VERSION ""

NS_ :

BS_:

BU_: BMS HVB BMU

BO_ 2147484693 CURRENT: 4 Vector__XXX
 SG_ Current : 7|32@0+ (1000,-2147483648) [-2147483648|4292819811352] "A" Vector__XXX

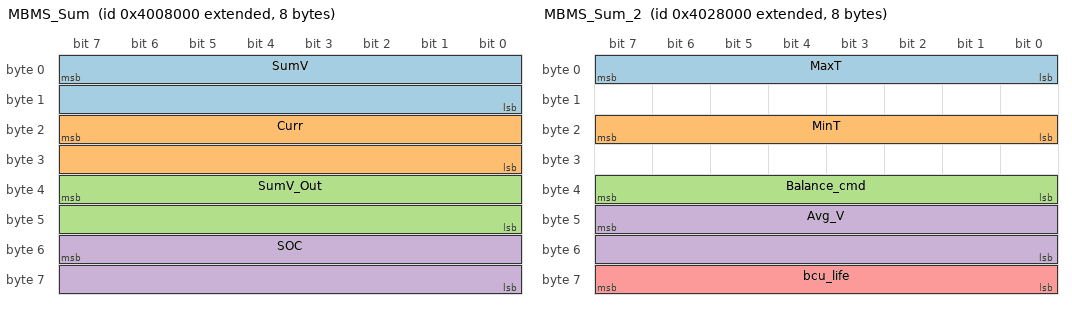
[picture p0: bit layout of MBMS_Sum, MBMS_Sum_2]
BO_ 2214625280 MBMS_Sum: 8 BMS
 SG_ SumV : 7|16@0+ (0.1,0) [1|1] "V" Vector__XXX
 SG_ Curr : 23|16@0+ (0.1,-3000) [1|1] "A" Vector__XXX
 SG_ SumV_Out : 39|16@0+ (0.1,0) [1|1] "V" Vector__XXX
 SG_ SOC : 55|16@0+ (0.1,0) [1|1] "%" Vector__XXX

BO_ 2214690816 MBMS_EVI: 8 BMS
 SG_ MaxV : 7|16@0+ (0.001,0) [1|1] "V" Vector__XXX
 SG_ MinV : 31|16@0+ (0.001,0) [1|1] "V" Vector__XXX
 SG_ SN : 55|8@0+ (1,0) [1|1] "" Vector__XXX

BO_ 2214756352 MBMS_Sum_2: 8 BMS
 SG_ MaxT : 7|8@0+ (1,-40) [1|1] "⊥" Vector__XXX
 SG_ MinT : 23|8@0+ (1,-40) [1|1] "⊥" Vector__XXX
 SG_ Balance_cmd : 39|8@0+ (1,0) [1|1] "" Vector__XXX
 SG_ Avg_V : 47|16@0+ (0.001,0) [1|1] "V" Vector__XXX
 SG_ bcu_life : 63|8@0+ (1,0) [1|1] "" Vector__XXX

BO_ 2214887424 MBMS_Chg_2: 8 BMS
 SG_ NomCap : 39|16@0+ (1,0) [1|1] "AH" Vector__XXX
 SG_ ActCap_ : 55|16@0+ (1,0) [1|1] "AH" Vector__XXX

BO_ 2214952960 MBMS_Data_1: 8 BMS
 SG_ Total_In_Ah : 7|32@0+ (1,0) [1|1] "" Vector__XXX
 SG_ Total_Out_Ah : 39|32@0+ (1,0) [1|1] "" Vector__XXX

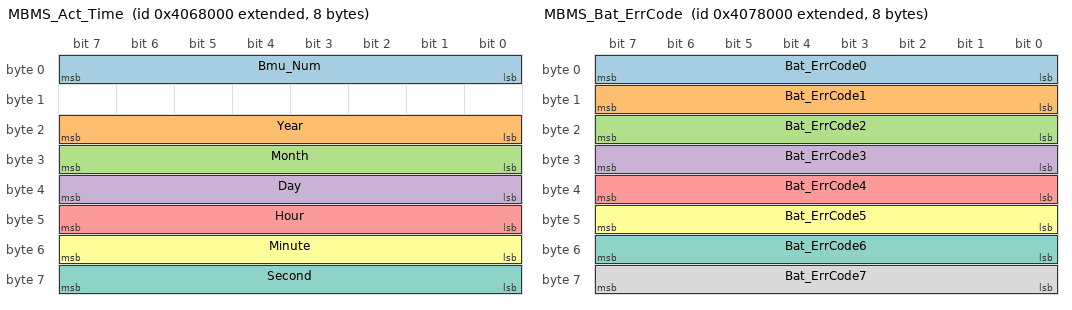
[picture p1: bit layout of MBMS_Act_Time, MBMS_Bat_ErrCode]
BO_ 2215018496 MBMS_Act_Time: 8 BMS
 SG_ Bmu_Num : 7|8@0+ (1,0) [1|1] "" Vector__XXX
 SG_ Year : 23|8@0+ (1,0) [1|1] "" Vector__XXX
 SG_ Month : 31|8@0+ (1,0) [1|1] "" Vector__XXX
 SG_ Day : 39|8@0+ (1,0) [1|1] "" Vector__XXX
 SG_ Hour : 47|8@0+ (1,0) [1|1] "" Vector__XXX
 SG_ Minute : 55|8@0+ (1,0) [1|1] "" Vector__XXX
 SG_ Second : 63|8@0+ (1,0) [1|1] "" Vector__XXX

BO_ 2215084032 MBMS_Bat_ErrCode: 8 BMS
 SG_ Bat_ErrCode0 : 7|8@0+ (1,0) [1|1] "" Vector__XXX
 SG_ Bat_ErrCode1 : 15|8@0+ (1,0) [1|1] "" Vector__XXX
 SG_ Bat_ErrCode2 : 23|8@0+ (1,0) [1|1] "" Vector__XXX
 SG_ Bat_ErrCode3 : 31|8@0+ (1,0) [1|1] "" Vector__XXX
 SG_ Bat_ErrCode4 : 39|8@0+ (1,0) [1|1] "" Vector__XXX
 SG_ Bat_ErrCode5 : 47|8@0+ (1,0) [1|1] "" Vector__XXX
 SG_ Bat_ErrCode6 : 55|8@0+ (1,0) [1|1] "" Vector__XXX
 SG_ Bat_ErrCode7 : 63|8@0+ (1,0) [1|1] "" Vector__XXX

BO_ 2215149568 MBMS_BatSys_ErrCode: 8 BMS
 SG_ BatSys_ErrCode0 : 7|8@0+ (1,0) [1|1] "" Vector__XXX
 SG_ BatSys_ErrCode1 : 15|8@0+ (1,0) [1|1] "" Vector__XXX

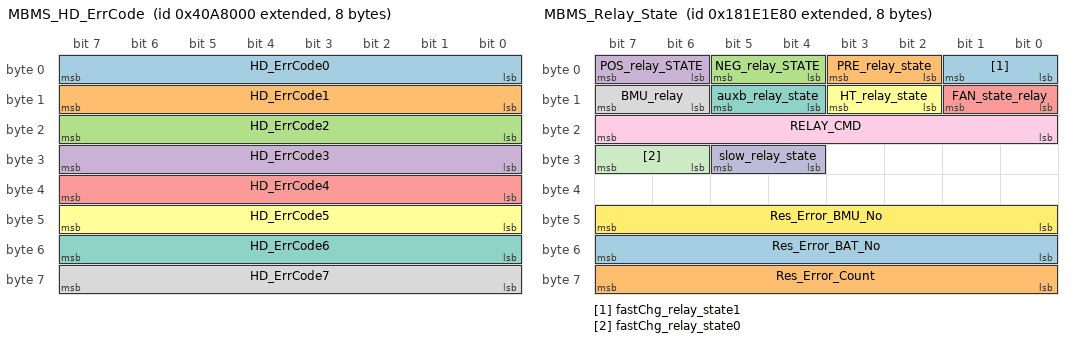
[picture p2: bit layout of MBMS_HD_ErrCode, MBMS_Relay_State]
BO_ 2215280640 MBMS_HD_ErrCode: 8 BMS
 SG_ HD_ErrCode0 : 7|8@0+ (1,0) [1|1] "" Vector__XXX
 SG_ HD_ErrCode1 : 15|8@0+ (1,0) [1|1] "" Vector__XXX
 SG_ HD_ErrCode2 : 23|8@0+ (1,0) [1|1] "" Vector__XXX
 SG_ HD_ErrCode3 : 31|8@0+ (1,0) [1|1] "" Vector__XXX
 SG_ HD_ErrCode4 : 39|8@0+ (1,0) [1|1] "" Vector__XXX
 SG_ HD_ErrCode5 : 47|8@0+ (1,0) [1|1] "" Vector__XXX
 SG_ HD_ErrCode6 : 55|8@0+ (1,0) [1|1] "" Vector__XXX
 SG_ HD_ErrCode7 : 63|8@0+ (1,0) [1|1] "" Vector__XXX

BO_ 2552110720 MBMS_Relay_State: 8 BMS
 SG_ fastChg_relay_state1 : 1|2@0+ (1,0) [1|1] "" Vector__XXX
 SG_ PRE_relay_state : 3|2@0+ (1,0) [1|1] "" Vector__XXX
 SG_ NEG_relay_STATE : 5|2@0+ (1,0) [1|1] "" Vector__XXX
 SG_ POS_relay_STATE : 7|2@0+ (1,0) [1|1] "" Vector__XXX
 SG_ FAN_state_relay : 9|2@0+ (1,0) [1|1] "" Vector__XXX
 SG_ HT_relay_state : 11|2@0+ (1,0) [1|1] "" Vector__XXX
 SG_ auxb_relay_state : 13|2@0+ (1,0) [1|1] "" Vector__XXX
 SG_ BMU_relay : 15|2@0+ (1,0) [1|1] "" Vector__XXX
 SG_ RELAY_CMD : 23|8@0+ (1,0) [1|1] "" Vector__XXX
 SG_ slow_relay_state : 29|2@0+ (1,0) [1|1] "" Vector__XXX
 SG_ fastChg_relay_state0 : 31|2@0+ (1,0) [1|1] "" Vector__XXX
 SG_ Res_Error_BMU_No : 47|8@0+ (1,0) [1|1] "" Vector__XXX
 SG_ Res_Error_BAT_No : 55|8@0+ (1,0) [1|1] "" Vector__XXX
 SG_ Res_Error_Count : 63|8@0+ (1,0) [1|1] "" Vector__XXX

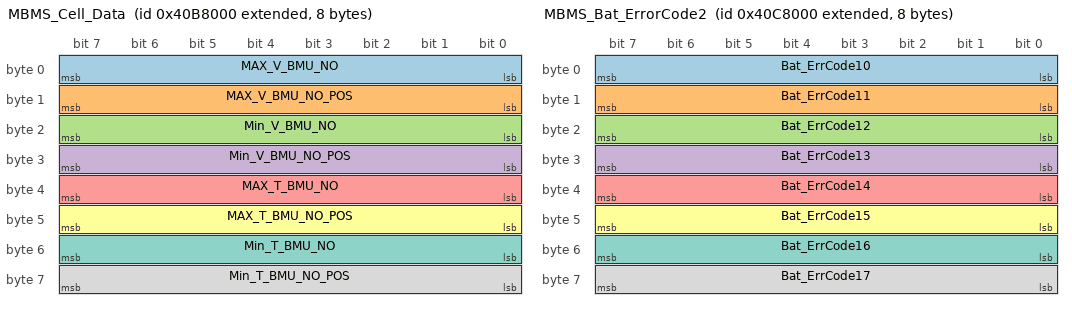
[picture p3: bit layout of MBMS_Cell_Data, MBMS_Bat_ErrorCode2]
BO_ 2215346176 MBMS_Cell_Data: 8 BMS
 SG_ MAX_V_BMU_NO : 7|8@0+ (1,0) [1|1] "" Vector__XXX
 SG_ MAX_V_BMU_NO_POS : 15|8@0+ (1,0) [1|1] "" Vector__XXX
 SG_ Min_V_BMU_NO : 23|8@0+ (1,0) [1|1] "" Vector__XXX
 SG_ Min_V_BMU_NO_POS : 31|8@0+ (1,0) [1|1] "" Vector__XXX
 SG_ MAX_T_BMU_NO : 39|8@0+ (1,0) [1|1] "" Vector__XXX
 SG_ MAX_T_BMU_NO_POS : 47|8@0+ (1,0) [1|1] "" Vector__XXX
 SG_ Min_T_BMU_NO : 55|8@0+ (1,0) [1|1] "" Vector__XXX
 SG_ Min_T_BMU_NO_POS : 63|8@0+ (1,0) [1|1] "" Vector__XXX

BO_ 2215411712 MBMS_Bat_ErrorCode2: 8 BMS
 SG_ Bat_ErrCode10 : 7|8@0+ (1,0) [1|1] "" Vector__XXX
 SG_ Bat_ErrCode11 : 15|8@0+ (1,0) [1|1] "" Vector__XXX
 SG_ Bat_ErrCode12 : 23|8@0+ (1,0) [1|1] "" Vector__XXX
 SG_ Bat_ErrCode13 : 31|8@0+ (1,0) [1|1] "" Vector__XXX
 SG_ Bat_ErrCode14 : 39|8@0+ (1,0) [1|1] "" Vector__XXX
 SG_ Bat_ErrCode15 : 47|8@0+ (1,0) [1|1] "" Vector__XXX
 SG_ Bat_ErrCode16 : 55|8@0+ (1,0) [1|1] "" Vector__XXX
 SG_ Bat_ErrCode17 : 63|8@0+ (1,0) [1|1] "" Vector__XXX

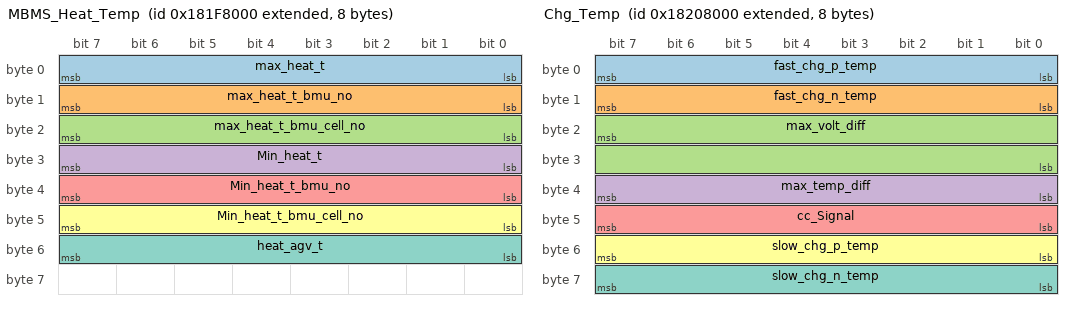
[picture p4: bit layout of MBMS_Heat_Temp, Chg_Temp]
BO_ 2552201216 MBMS_Heat_Temp: 8 BMS
 SG_ max_heat_t : 7|8@0+ (1,-40) [1|1] "⊥" Vector__XXX
 SG_ max_heat_t_bmu_no : 15|8@0+ (1,0) [1|1] "" Vector__XXX
 SG_ max_heat_t_bmu_cell_no : 23|8@0+ (1,0) [1|1] "" Vector__XXX
 SG_ Min_heat_t : 31|8@0+ (1,-40) [1|1] "⊥" Vector__XXX
 SG_ Min_heat_t_bmu_no : 39|8@0+ (1,0) [1|1] "" Vector__XXX
 SG_ Min_heat_t_bmu_cell_no : 47|8@0+ (1,0) [1|1] "" Vector__XXX
 SG_ heat_agv_t : 55|8@0+ (1,-40) [1|1] "⊥" Vector__XXX

BO_ 2552266752 Chg_Temp: 8 BMS
 SG_ fast_chg_p_temp : 7|8@0+ (1,-40) [1|1] "⊥" Vector__XXX
 SG_ fast_chg_n_temp : 15|8@0+ (1,-40) [1|1] "⊥" Vector__XXX
 SG_ max_volt_diff : 23|16@0+ (1,0) [1|1] "mV" Vector__XXX
 SG_ max_temp_diff : 39|8@0+ (1,-40) [1|1] "⊥" Vector__XXX
 SG_ cc_Signal : 47|8@0+ (1,0) [1|1] "" Vector__XXX
 SG_ slow_chg_p_temp : 55|8@0+ (1,-40) [1|1] "⊥" Vector__XXX
 SG_ slow_chg_n_temp : 63|8@0+ (1,-40) [1|1] "⊥" Vector__XXX

BO_ 2215542784 MBMS_HV: 8 BMS
 SG_ BAT_TV : 7|16@0+ (0.1,0) [1|1] "" Vector__XXX
 SG_ CHG_TV : 23|16@0+ (0.1,0) [1|1] "" Vector__XXX

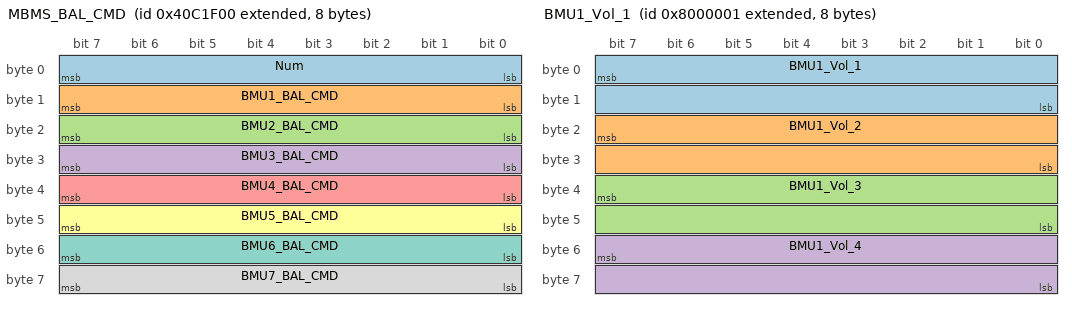
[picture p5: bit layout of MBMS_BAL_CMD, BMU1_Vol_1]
BO_ 2215386880 MBMS_BAL_CMD: 8 BMS
 SG_ Num : 7|8@0+ (1,0) [1|1] "" Vector__XXX
 SG_ BMU1_BAL_CMD : 15|8@0+ (1,0) [1|1] "" Vector__XXX
 SG_ BMU2_BAL_CMD : 23|8@0+ (1,0) [1|1] "" Vector__XXX
 SG_ BMU3_BAL_CMD : 31|8@0+ (1,0) [1|1] "" Vector__XXX
 SG_ BMU4_BAL_CMD : 39|8@0+ (1,0) [1|1] "" Vector__XXX
 SG_ BMU5_BAL_CMD : 47|8@0+ (1,0) [1|1] "" Vector__XXX
 SG_ BMU6_BAL_CMD : 55|8@0+ (1,0) [1|1] "" Vector__XXX
 SG_ BMU7_BAL_CMD : 63|8@0+ (1,0) [1|1] "" Vector__XXX

BO_ 2214920222 HVC_ISO_Res: 8 HVB
 SG_ ISO_RES_VAL : 7|16@0+ (1,0) [1|1] "K次"  BMS

BO_ 2281701377 BMU1_Vol_1: 8 BMU
 SG_ BMU1_Vol_1 : 7|16@0+ (0.001,0) [1|1] "V"  BMS
 SG_ BMU1_Vol_2 : 23|16@0+ (0.001,0) [1|1] "V"  BMS
 SG_ BMU1_Vol_3 : 39|16@0+ (0.001,0) [1|1] "V"  BMS
 SG_ BMU1_Vol_4 : 55|16@0+ (0.001,0) [1|1] "V"  BMS

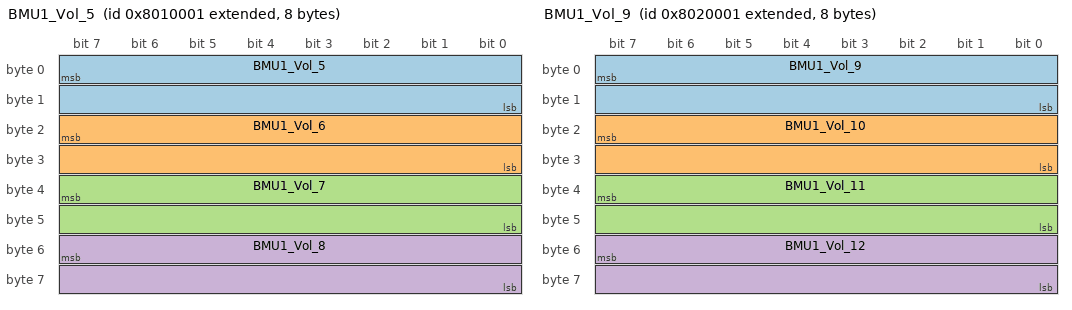
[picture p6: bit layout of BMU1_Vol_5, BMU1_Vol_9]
BO_ 2281766913 BMU1_Vol_5: 8 BMU
 SG_ BMU1_Vol_5 : 7|16@0+ (0.001,0) [1|1] "V"  BMS
 SG_ BMU1_Vol_6 : 23|16@0+ (0.001,0) [1|1] "V"  BMS
 SG_ BMU1_Vol_7 : 39|16@0+ (0.001,0) [1|1] "V"  BMS
 SG_ BMU1_Vol_8 : 55|16@0+ (0.001,0) [1|1] "V"  BMS

BO_ 2281832449 BMU1_Vol_9: 8 BMU
 SG_ BMU1_Vol_9 : 7|16@0+ (0.001,0) [1|1] "V"  BMS
 SG_ BMU1_Vol_10 : 23|16@0+ (0.001,0) [1|1] "V"  BMS
 SG_ BMU1_Vol_11 : 39|16@0+ (0.001,0) [1|1] "V"  BMS
 SG_ BMU1_Vol_12 : 55|16@0+ (0.001,0) [1|1] "V"  BMS

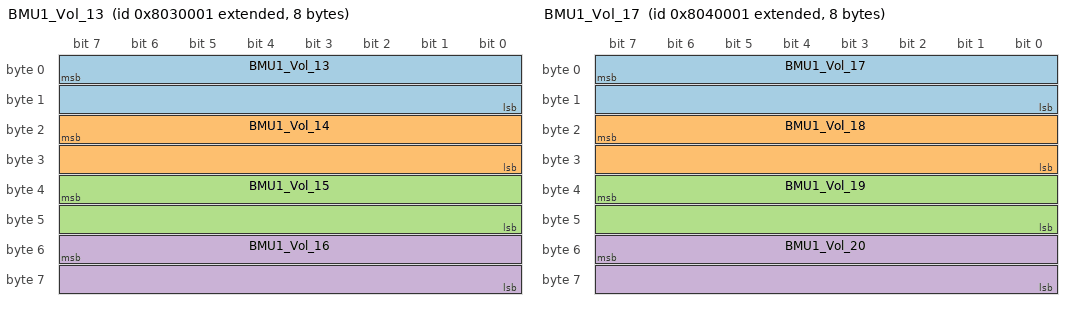
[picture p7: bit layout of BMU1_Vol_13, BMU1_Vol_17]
BO_ 2281897985 BMU1_Vol_13: 8 BMU
 SG_ BMU1_Vol_13 : 7|16@0+ (0.001,0) [1|1] "V"  BMS
 SG_ BMU1_Vol_14 : 23|16@0+ (0.001,0) [1|1] "V"  BMS
 SG_ BMU1_Vol_15 : 39|16@0+ (0.001,0) [1|1] "V"  BMS
 SG_ BMU1_Vol_16 : 55|16@0+ (0.001,0) [1|1] "V"  BMS

BO_ 2281963521 BMU1_Vol_17: 8 BMU
 SG_ BMU1_Vol_17 : 7|16@0+ (0.001,0) [1|1] "V"  BMS
 SG_ BMU1_Vol_18 : 23|16@0+ (0.001,0) [1|1] "V"  BMS
 SG_ BMU1_Vol_19 : 39|16@0+ (0.001,0) [1|1] "V"  BMS
 SG_ BMU1_Vol_20 : 55|16@0+ (0.001,0) [1|1] "V"  BMS

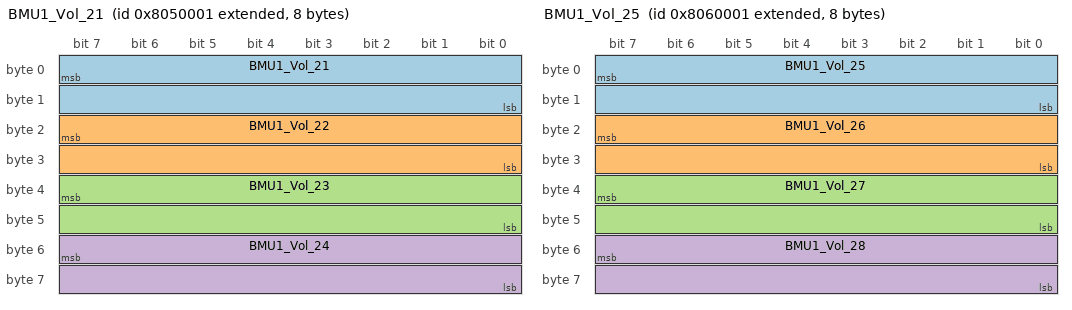
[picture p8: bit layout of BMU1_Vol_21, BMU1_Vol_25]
BO_ 2282029057 BMU1_Vol_21: 8 BMU
 SG_ BMU1_Vol_21 : 7|16@0+ (0.001,0) [1|1] "V"  BMS
 SG_ BMU1_Vol_22 : 23|16@0+ (0.001,0) [1|1] "V"  BMS
 SG_ BMU1_Vol_23 : 39|16@0+ (0.001,0) [1|1] "V"  BMS
 SG_ BMU1_Vol_24 : 55|16@0+ (0.001,0) [1|1] "V"  BMS

BO_ 2282094593 BMU1_Vol_25: 8 BMU
 SG_ BMU1_Vol_25 : 7|16@0+ (0.001,0) [1|1] "V"  BMS
 SG_ BMU1_Vol_26 : 23|16@0+ (0.001,0) [1|1] "V"  BMS
 SG_ BMU1_Vol_27 : 39|16@0+ (0.001,0) [1|1] "V"  BMS
 SG_ BMU1_Vol_28 : 55|16@0+ (0.001,0) [1|1] "V"  BMS

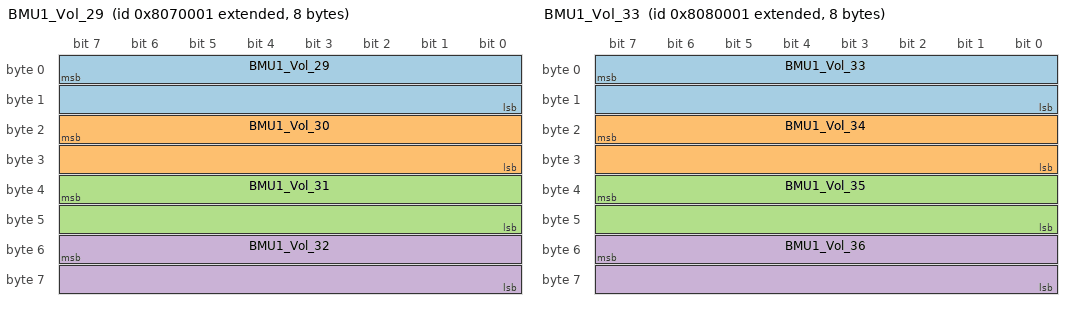
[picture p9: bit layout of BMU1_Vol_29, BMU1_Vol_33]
BO_ 2282160129 BMU1_Vol_29: 8 BMU
 SG_ BMU1_Vol_29 : 7|16@0+ (0.001,0) [1|1] "V"  BMS
 SG_ BMU1_Vol_30 : 23|16@0+ (0.001,0) [1|1] "V"  BMS
 SG_ BMU1_Vol_31 : 39|16@0+ (0.001,0) [1|1] "V"  BMS
 SG_ BMU1_Vol_32 : 55|16@0+ (0.001,0) [1|1] "V"  BMS

BO_ 2282225665 BMU1_Vol_33: 8 BMU
 SG_ BMU1_Vol_33 : 7|16@0+ (0.001,0) [1|1] "V"  BMS
 SG_ BMU1_Vol_34 : 23|16@0+ (0.001,0) [1|1] "V"  BMS
 SG_ BMU1_Vol_35 : 39|16@0+ (0.001,0) [1|1] "V"  BMS
 SG_ BMU1_Vol_36 : 55|16@0+ (0.001,0) [1|1] "V"  BMS

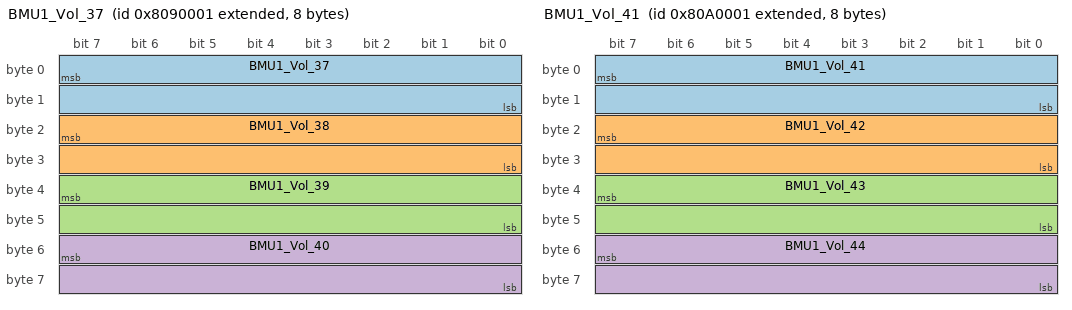
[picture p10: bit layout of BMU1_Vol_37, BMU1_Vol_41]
BO_ 2282291201 BMU1_Vol_37: 8 BMU
 SG_ BMU1_Vol_37 : 7|16@0+ (0.001,0) [1|1] "V"  BMS
 SG_ BMU1_Vol_38 : 23|16@0+ (0.001,0) [1|1] "V"  BMS
 SG_ BMU1_Vol_39 : 39|16@0+ (0.001,0) [1|1] "V"  BMS
 SG_ BMU1_Vol_40 : 55|16@0+ (0.001,0) [1|1] "V"  BMS

BO_ 2282356737 BMU1_Vol_41: 8 BMU
 SG_ BMU1_Vol_41 : 7|16@0+ (0.001,0) [1|1] "V"  BMS
 SG_ BMU1_Vol_42 : 23|16@0+ (0.001,0) [1|1] "V"  BMS
 SG_ BMU1_Vol_43 : 39|16@0+ (0.001,0) [1|1] "V"  BMS
 SG_ BMU1_Vol_44 : 55|16@0+ (0.001,0) [1|1] "V"  BMS

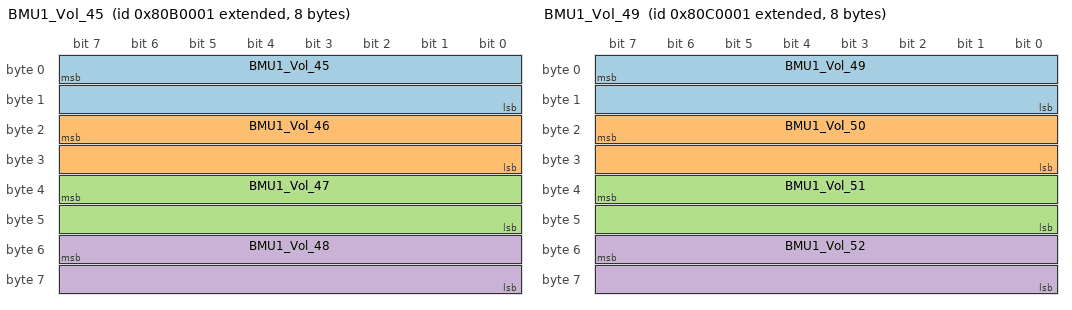
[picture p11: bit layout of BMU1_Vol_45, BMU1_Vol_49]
BO_ 2282422273 BMU1_Vol_45: 8 BMU
 SG_ BMU1_Vol_45 : 7|16@0+ (0.001,0) [1|1] "V"  BMS
 SG_ BMU1_Vol_46 : 23|16@0+ (0.001,0) [1|1] "V"  BMS
 SG_ BMU1_Vol_47 : 39|16@0+ (0.001,0) [1|1] "V"  BMS
 SG_ BMU1_Vol_48 : 55|16@0+ (0.001,0) [1|1] "V"  BMS

BO_ 2282487809 BMU1_Vol_49: 8 BMU
 SG_ BMU1_Vol_49 : 7|16@0+ (0.001,0) [1|1] "V"  BMS
 SG_ BMU1_Vol_50 : 23|16@0+ (0.001,0) [1|1] "V"  BMS
 SG_ BMU1_Vol_51 : 39|16@0+ (0.001,0) [1|1] "V"  BMS
 SG_ BMU1_Vol_52 : 55|16@0+ (0.001,0) [1|1] "V"  BMS

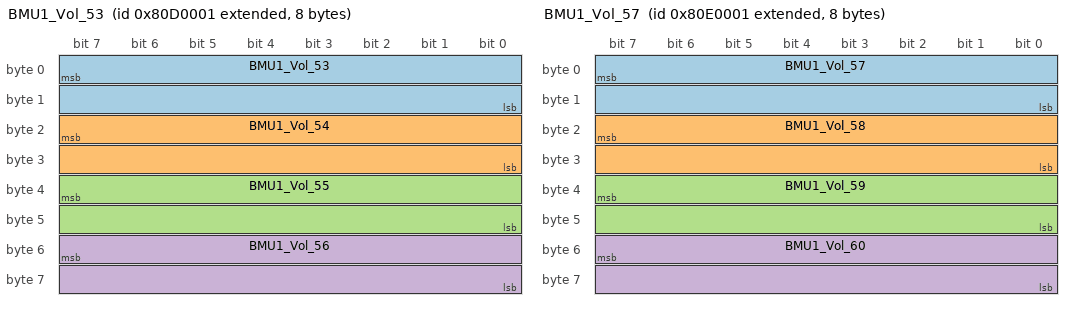
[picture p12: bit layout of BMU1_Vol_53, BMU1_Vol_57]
BO_ 2282553345 BMU1_Vol_53: 8 BMU
 SG_ BMU1_Vol_53 : 7|16@0+ (0.001,0) [1|1] "V"  BMS
 SG_ BMU1_Vol_54 : 23|16@0+ (0.001,0) [1|1] "V"  BMS
 SG_ BMU1_Vol_55 : 39|16@0+ (0.001,0) [1|1] "V"  BMS
 SG_ BMU1_Vol_56 : 55|16@0+ (0.001,0) [1|1] "V"  BMS

BO_ 2282618881 BMU1_Vol_57: 8 BMU
 SG_ BMU1_Vol_57 : 7|16@0+ (0.001,0) [1|1] "V"  BMS
 SG_ BMU1_Vol_58 : 23|16@0+ (0.001,0) [1|1] "V"  BMS
 SG_ BMU1_Vol_59 : 39|16@0+ (0.001,0) [1|1] "V"  BMS
 SG_ BMU1_Vol_60 : 55|16@0+ (0.001,0) [1|1] "V"  BMS

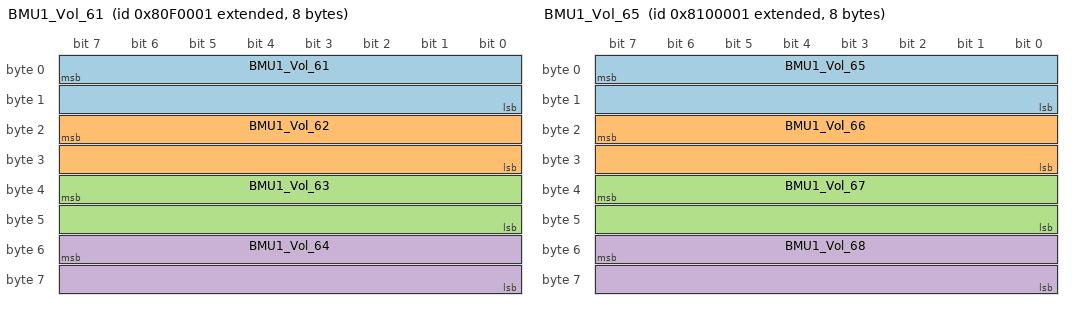
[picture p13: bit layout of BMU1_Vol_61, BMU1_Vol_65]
BO_ 2282684417 BMU1_Vol_61: 8 BMU
 SG_ BMU1_Vol_61 : 7|16@0+ (0.001,0) [1|1] "V"  BMS
 SG_ BMU1_Vol_62 : 23|16@0+ (0.001,0) [1|1] "V"  BMS
 SG_ BMU1_Vol_63 : 39|16@0+ (0.001,0) [1|1] "V"  BMS
 SG_ BMU1_Vol_64 : 55|16@0+ (0.001,0) [1|1] "V"  BMS

BO_ 2282749953 BMU1_Vol_65: 8 BMU
 SG_ BMU1_Vol_65 : 7|16@0+ (0.001,0) [1|1] "V"  BMS
 SG_ BMU1_Vol_66 : 23|16@0+ (0.001,0) [1|1] "V"  BMS
 SG_ BMU1_Vol_67 : 39|16@0+ (0.001,0) [1|1] "V"  BMS
 SG_ BMU1_Vol_68 : 55|16@0+ (0.001,0) [1|1] "V"  BMS

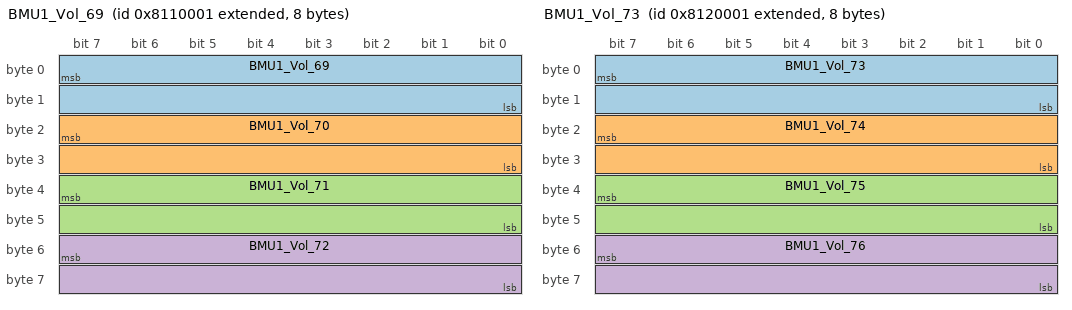
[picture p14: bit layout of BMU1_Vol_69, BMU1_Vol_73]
BO_ 2282815489 BMU1_Vol_69: 8 BMU
 SG_ BMU1_Vol_69 : 7|16@0+ (0.001,0) [1|1] "V"  BMS
 SG_ BMU1_Vol_70 : 23|16@0+ (0.001,0) [1|1] "V"  BMS
 SG_ BMU1_Vol_71 : 39|16@0+ (0.001,0) [1|1] "V"  BMS
 SG_ BMU1_Vol_72 : 55|16@0+ (0.001,0) [1|1] "V"  BMS

BO_ 2282881025 BMU1_Vol_73: 8 BMU
 SG_ BMU1_Vol_73 : 7|16@0+ (0.001,0) [1|1] "V"  BMS
 SG_ BMU1_Vol_74 : 23|16@0+ (0.001,0) [1|1] "V"  BMS
 SG_ BMU1_Vol_75 : 39|16@0+ (0.001,0) [1|1] "V"  BMS
 SG_ BMU1_Vol_76 : 55|16@0+ (0.001,0) [1|1] "V"  BMS

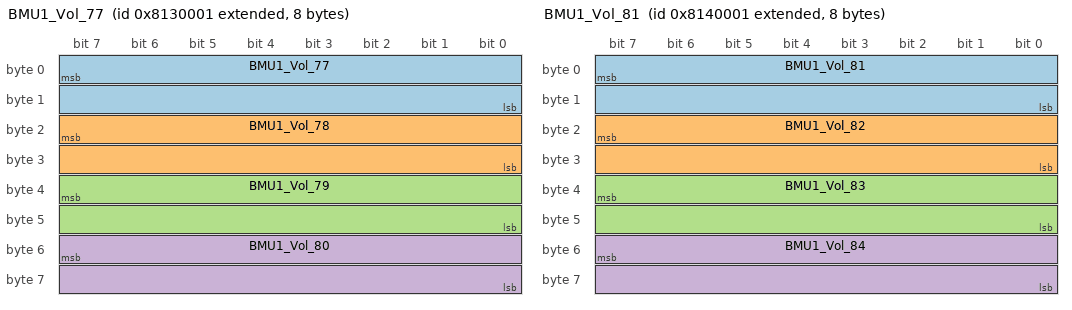
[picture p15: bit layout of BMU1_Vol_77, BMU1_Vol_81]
BO_ 2282946561 BMU1_Vol_77: 8 BMU
 SG_ BMU1_Vol_77 : 7|16@0+ (0.001,0) [1|1] "V"  BMS
 SG_ BMU1_Vol_78 : 23|16@0+ (0.001,0) [1|1] "V"  BMS
 SG_ BMU1_Vol_79 : 39|16@0+ (0.001,0) [1|1] "V"  BMS
 SG_ BMU1_Vol_80 : 55|16@0+ (0.001,0) [1|1] "V"  BMS

BO_ 2283012097 BMU1_Vol_81: 8 BMU
 SG_ BMU1_Vol_81 : 7|16@0+ (0.001,0) [1|1] "V"  BMS
 SG_ BMU1_Vol_82 : 23|16@0+ (0.001,0) [1|1] "V"  BMS
 SG_ BMU1_Vol_83 : 39|16@0+ (0.001,0) [1|1] "V"  BMS
 SG_ BMU1_Vol_84 : 55|16@0+ (0.001,0) [1|1] "V"  BMS

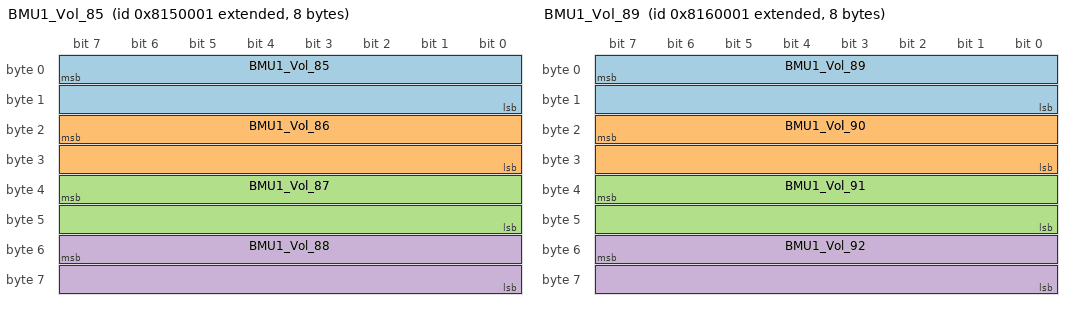
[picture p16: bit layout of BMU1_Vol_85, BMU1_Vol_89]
BO_ 2283077633 BMU1_Vol_85: 8 BMU
 SG_ BMU1_Vol_85 : 7|16@0+ (0.001,0) [1|1] "V"  BMS
 SG_ BMU1_Vol_86 : 23|16@0+ (0.001,0) [1|1] "V"  BMS
 SG_ BMU1_Vol_87 : 39|16@0+ (0.001,0) [1|1] "V"  BMS
 SG_ BMU1_Vol_88 : 55|16@0+ (0.001,0) [1|1] "V"  BMS

BO_ 2283143169 BMU1_Vol_89: 8 BMU
 SG_ BMU1_Vol_89 : 7|16@0+ (0.001,0) [1|1] "V"  BMS
 SG_ BMU1_Vol_90 : 23|16@0+ (0.001,0) [1|1] "V"  BMS
 SG_ BMU1_Vol_91 : 39|16@0+ (0.001,0) [1|1] "V"  BMS
 SG_ BMU1_Vol_92 : 55|16@0+ (0.001,0) [1|1] "V"  BMS

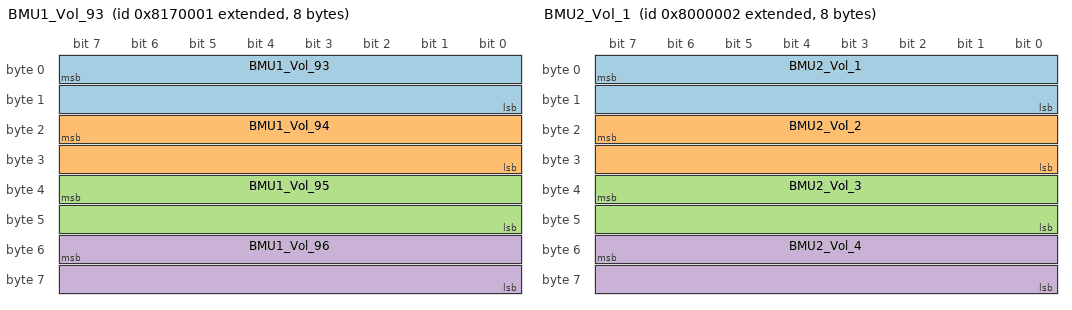
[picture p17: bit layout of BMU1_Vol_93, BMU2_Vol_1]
BO_ 2283208705 BMU1_Vol_93: 8 BMU
 SG_ BMU1_Vol_93 : 7|16@0+ (0.001,0) [1|1] "V"  BMS
 SG_ BMU1_Vol_94 : 23|16@0+ (0.001,0) [1|1] "V"  BMS
 SG_ BMU1_Vol_95 : 39|16@0+ (0.001,0) [1|1] "V"  BMS
 SG_ BMU1_Vol_96 : 55|16@0+ (0.001,0) [1|1] "V"  BMS

BO_ 2281701378 BMU2_Vol_1: 8 BMU
 SG_ BMU2_Vol_1 : 7|16@0+ (0.001,0) [1|1] "V"  BMS
 SG_ BMU2_Vol_2 : 23|16@0+ (0.001,0) [1|1] "V"  BMS
 SG_ BMU2_Vol_3 : 39|16@0+ (0.001,0) [1|1] "V"  BMS
 SG_ BMU2_Vol_4 : 55|16@0+ (0.001,0) [1|1] "V"  BMS

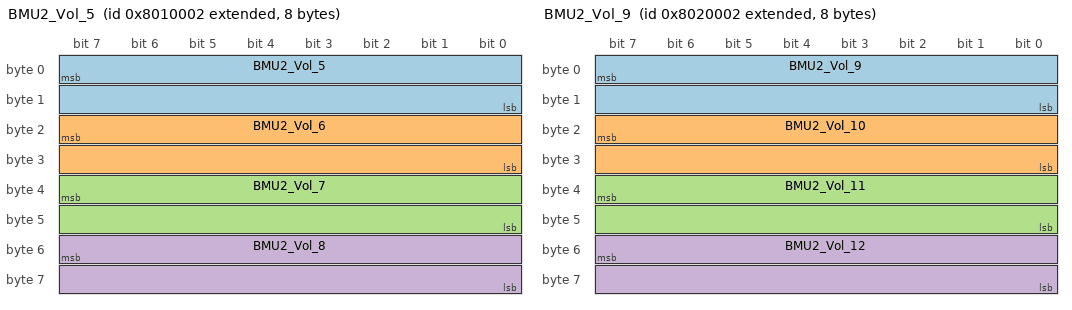
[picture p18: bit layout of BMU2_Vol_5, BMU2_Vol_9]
BO_ 2281766914 BMU2_Vol_5: 8 BMU
 SG_ BMU2_Vol_5 : 7|16@0+ (0.001,0) [1|1] "V"  BMS
 SG_ BMU2_Vol_6 : 23|16@0+ (0.001,0) [1|1] "V"  BMS
 SG_ BMU2_Vol_7 : 39|16@0+ (0.001,0) [1|1] "V"  BMS
 SG_ BMU2_Vol_8 : 55|16@0+ (0.001,0) [1|1] "V"  BMS

BO_ 2281832450 BMU2_Vol_9: 8 BMU
 SG_ BMU2_Vol_9 : 7|16@0+ (0.001,0) [1|1] "V"  BMS
 SG_ BMU2_Vol_10 : 23|16@0+ (0.001,0) [1|1] "V"  BMS
 SG_ BMU2_Vol_11 : 39|16@0+ (0.001,0) [1|1] "V"  BMS
 SG_ BMU2_Vol_12 : 55|16@0+ (0.001,0) [1|1] "V"  BMS

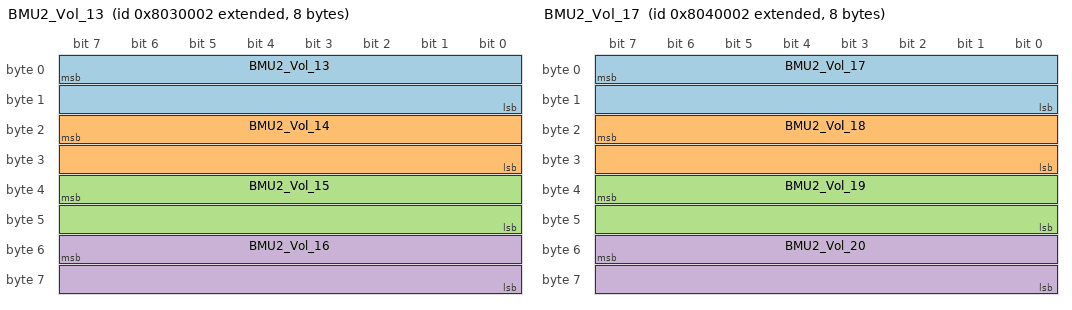
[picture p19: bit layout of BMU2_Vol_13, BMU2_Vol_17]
BO_ 2281897986 BMU2_Vol_13: 8 BMU
 SG_ BMU2_Vol_13 : 7|16@0+ (0.001,0) [1|1] "V"  BMS
 SG_ BMU2_Vol_14 : 23|16@0+ (0.001,0) [1|1] "V"  BMS
 SG_ BMU2_Vol_15 : 39|16@0+ (0.001,0) [1|1] "V"  BMS
 SG_ BMU2_Vol_16 : 55|16@0+ (0.001,0) [1|1] "V"  BMS

BO_ 2281963522 BMU2_Vol_17: 8 BMU
 SG_ BMU2_Vol_17 : 7|16@0+ (0.001,0) [1|1] "V"  BMS
 SG_ BMU2_Vol_18 : 23|16@0+ (0.001,0) [1|1] "V"  BMS
 SG_ BMU2_Vol_19 : 39|16@0+ (0.001,0) [1|1] "V"  BMS
 SG_ BMU2_Vol_20 : 55|16@0+ (0.001,0) [1|1] "V"  BMS

BO_ 2282029058 BMU2_Vol_21: 8 BMU
 SG_ BMU2_Vol_21 : 7|16@0+ (0.001,0) [1|1] "V"  BMS
 SG_ BMU2_Vol_22 : 23|16@0+ (0.001,0) [1|1] "V"  BMS
 SG_ BMU2_Vol_23 : 39|16@0+ (0.001,0) [1|1] "V"  BMS
 SG_ BMU2_Vol_24 : 55|16@0+ (0.001,0) [1|1] "V"  BMS

BO_ 2282094594 BMU2_Vol_25: 8 BMU
 SG_ BMU2_Vol_25 : 7|16@0+ (0.001,0) [1|1] "V"  BMS
 SG_ BMU2_Vol_26 : 23|16@0+ (0.001,0) [1|1] "V"  BMS
 SG_ BMU2_Vol_27 : 39|16@0+ (0.001,0) [1|1] "V"  BMS
 SG_ BMU2_Vol_28 : 55|16@0+ (0.001,0) [1|1] "V"  BMS

BO_ 2282160130 BMU2_Vol_29: 8 BMU
 SG_ BMU2_Vol_29 : 7|16@0+ (0.001,0) [1|1] "V"  BMS
 SG_ BMU2_Vol_30 : 23|16@0+ (0.001,0) [1|1] "V"  BMS
 SG_ BMU2_Vol_31 : 39|16@0+ (0.001,0) [1|1] "V"  BMS
 SG_ BMU2_Vol_32 : 55|16@0+ (0.001,0) [1|1] "V"  BMS

BO_ 2282225666 BMU2_Vol_33: 8 BMU
 SG_ BMU2_Vol_33 : 7|16@0+ (0.001,0) [1|1] "V"  BMS
 SG_ BMU2_Vol_34 : 23|16@0+ (0.001,0) [1|1] "V"  BMS
 SG_ BMU2_Vol_35 : 39|16@0+ (0.001,0) [1|1] "V"  BMS
 SG_ BMU2_Vol_36 : 55|16@0+ (0.001,0) [1|1] "V"  BMS

BO_ 2282291202 BMU2_Vol_37: 8 BMU
 SG_ BMU2_Vol_37 : 7|16@0+ (0.001,0) [1|1] "V"  BMS
 SG_ BMU2_Vol_38 : 23|16@0+ (0.001,0) [1|1] "V"  BMS
 SG_ BMU2_Vol_39 : 39|16@0+ (0.001,0) [1|1] "V"  BMS
 SG_ BMU2_Vol_40 : 55|16@0+ (0.001,0) [1|1] "V"  BMS

BO_ 2282356738 BMU2_Vol_41: 8 BMU
 SG_ BMU2_Vol_41 : 7|16@0+ (0.001,0) [1|1] "V"  BMS
 SG_ BMU2_Vol_42 : 23|16@0+ (0.001,0) [1|1] "V"  BMS
 SG_ BMU2_Vol_43 : 39|16@0+ (0.001,0) [1|1] "V"  BMS
 SG_ BMU2_Vol_44 : 55|16@0+ (0.001,0) [1|1] "V"  BMS

BO_ 2282422274 BMU2_Vol_45: 8 BMU
 SG_ BMU2_Vol_45 : 7|16@0+ (0.001,0) [1|1] "V"  BMS
 SG_ BMU2_Vol_46 : 23|16@0+ (0.001,0) [1|1] "V"  BMS
 SG_ BMU2_Vol_47 : 39|16@0+ (0.001,0) [1|1] "V"  BMS
 SG_ BMU2_Vol_48 : 55|16@0+ (0.001,0) [1|1] "V"  BMS

BO_ 2282487810 BMU2_Vol_49: 8 BMU
 SG_ BMU2_Vol_49 : 7|16@0+ (0.001,0) [1|1] "V"  BMS
 SG_ BMU2_Vol_50 : 23|16@0+ (0.001,0) [1|1] "V"  BMS
 SG_ BMU2_Vol_51 : 39|16@0+ (0.001,0) [1|1] "V"  BMS
 SG_ BMU2_Vol_52 : 55|16@0+ (0.001,0) [1|1] "V"  BMS

BO_ 2282553346 BMU2_Vol_53: 8 BMU
 SG_ BMU2_Vol_53 : 7|16@0+ (0.001,0) [1|1] "V"  BMS
 SG_ BMU2_Vol_54 : 23|16@0+ (0.001,0) [1|1] "V"  BMS
 SG_ BMU2_Vol_55 : 39|16@0+ (0.001,0) [1|1] "V"  BMS
 SG_ BMU2_Vol_56 : 55|16@0+ (0.001,0) [1|1] "V"  BMS

BO_ 2282618882 BMU2_Vol_57: 8 BMU
 SG_ BMU2_Vol_57 : 7|16@0+ (0.001,0) [1|1] "V"  BMS
 SG_ BMU2_Vol_58 : 23|16@0+ (0.001,0) [1|1] "V"  BMS
 SG_ BMU2_Vol_59 : 39|16@0+ (0.001,0) [1|1] "V"  BMS
 SG_ BMU2_Vol_60 : 55|16@0+ (0.001,0) [1|1] "V"  BMS

BO_ 2282684418 BMU2_Vol_61: 8 BMU
 SG_ BMU2_Vol_61 : 7|16@0+ (0.001,0) [1|1] "V"  BMS
 SG_ BMU2_Vol_62 : 23|16@0+ (0.001,0) [1|1] "V"  BMS
 SG_ BMU2_Vol_63 : 39|16@0+ (0.001,0) [1|1] "V"  BMS
 SG_ BMU2_Vol_64 : 55|16@0+ (0.001,0) [1|1] "V"  BMS

BO_ 2282749954 BMU2_Vol_65: 8 BMU
 SG_ BMU2_Vol_65 : 7|16@0+ (0.001,0) [1|1] "V"  BMS
 SG_ BMU2_Vol_66 : 23|16@0+ (0.001,0) [1|1] "V"  BMS
 SG_ BMU2_Vol_67 : 39|16@0+ (0.001,0) [1|1] "V"  BMS
 SG_ BMU2_Vol_68 : 55|16@0+ (0.001,0) [1|1] "V"  BMS

BO_ 2282815490 BMU2_Vol_69: 8 BMU
 SG_ BMU2_Vol_69 : 7|16@0+ (0.001,0) [1|1] "V"  BMS
 SG_ BMU2_Vol_70 : 23|16@0+ (0.001,0) [1|1] "V"  BMS
 SG_ BMU2_Vol_71 : 39|16@0+ (0.001,0) [1|1] "V"  BMS
 SG_ BMU2_Vol_72 : 55|16@0+ (0.001,0) [1|1] "V"  BMS

BO_ 2282881026 BMU2_Vol_73: 8 BMU
 SG_ BMU2_Vol_73 : 7|16@0+ (0.001,0) [1|1] "V"  BMS
 SG_ BMU2_Vol_74 : 23|16@0+ (0.001,0) [1|1] "V"  BMS
 SG_ BMU2_Vol_75 : 39|16@0+ (0.001,0) [1|1] "V"  BMS
 SG_ BMU2_Vol_76 : 55|16@0+ (0.001,0) [1|1] "V"  BMS

BO_ 2282946562 BMU2_Vol_77: 8 BMU
 SG_ BMU2_Vol_77 : 7|16@0+ (0.001,0) [1|1] "V"  BMS
 SG_ BMU2_Vol_78 : 23|16@0+ (0.001,0) [1|1] "V"  BMS
 SG_ BMU2_Vol_79 : 39|16@0+ (0.001,0) [1|1] "V"  BMS
 SG_ BMU2_Vol_80 : 55|16@0+ (0.001,0) [1|1] "V"  BMS

BO_ 2283012098 BMU2_Vol_81: 8 BMU
 SG_ BMU2_Vol_81 : 7|16@0+ (0.001,0) [1|1] "V"  BMS
 SG_ BMU2_Vol_82 : 23|16@0+ (0.001,0) [1|1] "V"  BMS
 SG_ BMU2_Vol_83 : 39|16@0+ (0.001,0) [1|1] "V"  BMS
 SG_ BMU2_Vol_84 : 55|16@0+ (0.001,0) [1|1] "V"  BMS

BO_ 2283077634 BMU2_Vol_85: 8 BMU
 SG_ BMU2_Vol_85 : 7|16@0+ (0.001,0) [1|1] "V"  BMS
 SG_ BMU2_Vol_86 : 23|16@0+ (0.001,0) [1|1] "V"  BMS
 SG_ BMU2_Vol_87 : 39|16@0+ (0.001,0) [1|1] "V"  BMS
 SG_ BMU2_Vol_88 : 55|16@0+ (0.001,0) [1|1] "V"  BMS

BO_ 2283143170 BMU2_Vol_89: 8 BMU
 SG_ BMU2_Vol_89 : 7|16@0+ (0.001,0) [1|1] "V"  BMS
 SG_ BMU2_Vol_90 : 23|16@0+ (0.001,0) [1|1] "V"  BMS
 SG_ BMU2_Vol_91 : 39|16@0+ (0.001,0) [1|1] "V"  BMS
 SG_ BMU2_Vol_92 : 55|16@0+ (0.001,0) [1|1] "V"  BMS

BO_ 2283208706 BMU2_Vol_93: 8 BMU
 SG_ BMU2_Vol_93 : 7|16@0+ (0.001,0) [1|1] "V"  BMS
 SG_ BMU2_Vol_94 : 23|16@0+ (0.001,0) [1|1] "V"  BMS
 SG_ BMU2_Vol_95 : 39|16@0+ (0.001,0) [1|1] "V"  BMS
 SG_ BMU2_Vol_96 : 55|16@0+ (0.001,0) [1|1] "V"  BMS

BO_ 2281701379 BMU3_Vol_1: 8 BMU
 SG_ BMU3_Vol_1 : 7|16@0+ (0.001,0) [1|1] "V"  BMS
 SG_ BMU3_Vol_2 : 23|16@0+ (0.001,0) [1|1] "V"  BMS
 SG_ BMU3_Vol_3 : 39|16@0+ (0.001,0) [1|1] "V"  BMS
 SG_ BMU3_Vol_4 : 55|16@0+ (0.001,0) [1|1] "V"  BMS

BO_ 2281766915 BMU3_Vol_5: 8 BMU
 SG_ BMU3_Vol_5 : 7|16@0+ (0.001,0) [1|1] "V"  BMS
 SG_ BMU3_Vol_6 : 23|16@0+ (0.001,0) [1|1] "V"  BMS
 SG_ BMU3_Vol_7 : 39|16@0+ (0.001,0) [1|1] "V"  BMS
 SG_ BMU3_Vol_8 : 55|16@0+ (0.001,0) [1|1] "V"  BMS

BO_ 2281832451 BMU3_Vol_9: 8 BMU
 SG_ BMU3_Vol_9 : 7|16@0+ (0.001,0) [1|1] "V"  BMS
 SG_ BMU3_Vol_10 : 23|16@0+ (0.001,0) [1|1] "V"  BMS
 SG_ BMU3_Vol_11 : 39|16@0+ (0.001,0) [1|1] "V"  BMS
 SG_ BMU3_Vol_12 : 55|16@0+ (0.001,0) [1|1] "V"  BMS

BO_ 2281897987 BMU3_Vol_13: 8 BMU
 SG_ BMU3_Vol_13 : 7|16@0+ (0.001,0) [1|1] "V"  BMS
 SG_ BMU3_Vol_14 : 23|16@0+ (0.001,0) [1|1] "V"  BMS
 SG_ BMU3_Vol_15 : 39|16@0+ (0.001,0) [1|1] "V"  BMS
 SG_ BMU3_Vol_16 : 55|16@0+ (0.001,0) [1|1] "V"  BMS

BO_ 2281963523 BMU3_Vol_17: 8 BMU
 SG_ BMU3_Vol_17 : 7|16@0+ (0.001,0) [1|1] "V"  BMS
 SG_ BMU3_Vol_18 : 23|16@0+ (0.001,0) [1|1] "V"  BMS
 SG_ BMU3_Vol_19 : 39|16@0+ (0.001,0) [1|1] "V"  BMS
 SG_ BMU3_Vol_20 : 55|16@0+ (0.001,0) [1|1] "V"  BMS

BO_ 2282029059 BMU3_Vol_21: 8 BMU
 SG_ BMU3_Vol_21 : 7|16@0+ (0.001,0) [1|1] "V"  BMS
 SG_ BMU3_Vol_22 : 23|16@0+ (0.001,0) [1|1] "V"  BMS
 SG_ BMU3_Vol_23 : 39|16@0+ (0.001,0) [1|1] "V"  BMS
 SG_ BMU3_Vol_24 : 55|16@0+ (0.001,0) [1|1] "V"  BMS

BO_ 2282094595 BMU3_Vol_25: 8 BMU
 SG_ BMU3_Vol_25 : 7|16@0+ (0.001,0) [1|1] "V"  BMS
 SG_ BMU3_Vol_26 : 23|16@0+ (0.001,0) [1|1] "V"  BMS
 SG_ BMU3_Vol_27 : 39|16@0+ (0.001,0) [1|1] "V"  BMS
 SG_ BMU3_Vol_28 : 55|16@0+ (0.001,0) [1|1] "V"  BMS

BO_ 2282160131 BMU3_Vol_29: 8 BMU
 SG_ BMU3_Vol_29 : 7|16@0+ (0.001,0) [1|1] "V"  BMS
 SG_ BMU3_Vol_30 : 23|16@0+ (0.001,0) [1|1] "V"  BMS
 SG_ BMU3_Vol_31 : 39|16@0+ (0.001,0) [1|1] "V"  BMS
 SG_ BMU3_Vol_32 : 55|16@0+ (0.001,0) [1|1] "V"  BMS

BO_ 2282225667 BMU3_Vol_33: 8 BMU
 SG_ BMU3_Vol_33 : 7|16@0+ (0.001,0) [1|1] "V"  BMS
 SG_ BMU3_Vol_34 : 23|16@0+ (0.001,0) [1|1] "V"  BMS
 SG_ BMU3_Vol_35 : 39|16@0+ (0.001,0) [1|1] "V"  BMS
 SG_ BMU3_Vol_36 : 55|16@0+ (0.001,0) [1|1] "V"  BMS

BO_ 2282291203 BMU3_Vol_37: 8 BMU
 SG_ BMU3_Vol_37 : 7|16@0+ (0.001,0) [1|1] "V"  BMS
 SG_ BMU3_Vol_38 : 23|16@0+ (0.001,0) [1|1] "V"  BMS
 SG_ BMU3_Vol_39 : 39|16@0+ (0.001,0) [1|1] "V"  BMS
 SG_ BMU3_Vol_40 : 55|16@0+ (0.001,0) [1|1] "V"  BMS

BO_ 2282356739 BMU3_Vol_41: 8 BMU
 SG_ BMU3_Vol_41 : 7|16@0+ (0.001,0) [1|1] "V"  BMS
 SG_ BMU3_Vol_42 : 23|16@0+ (0.001,0) [1|1] "V"  BMS
 SG_ BMU3_Vol_43 : 39|16@0+ (0.001,0) [1|1] "V"  BMS
 SG_ BMU3_Vol_44 : 55|16@0+ (0.001,0) [1|1] "V"  BMS

BO_ 2282422275 BMU3_Vol_45: 8 BMU
 SG_ BMU3_Vol_45 : 7|16@0+ (0.001,0) [1|1] "V"  BMS
 SG_ BMU3_Vol_46 : 23|16@0+ (0.001,0) [1|1] "V"  BMS
 SG_ BMU3_Vol_47 : 39|16@0+ (0.001,0) [1|1] "V"  BMS
 SG_ BMU3_Vol_48 : 55|16@0+ (0.001,0) [1|1] "V"  BMS

BO_ 2282487811 BMU3_Vol_49: 8 BMU
 SG_ BMU3_Vol_49 : 7|16@0+ (0.001,0) [1|1] "V"  BMS
 SG_ BMU3_Vol_50 : 23|16@0+ (0.001,0) [1|1] "V"  BMS
 SG_ BMU3_Vol_51 : 39|16@0+ (0.001,0) [1|1] "V"  BMS
 SG_ BMU3_Vol_52 : 55|16@0+ (0.001,0) [1|1] "V"  BMS

BO_ 2282553347 BMU3_Vol_53: 8 BMU
 SG_ BMU3_Vol_53 : 7|16@0+ (0.001,0) [1|1] "V"  BMS
 SG_ BMU3_Vol_54 : 23|16@0+ (0.001,0) [1|1] "V"  BMS
 SG_ BMU3_Vol_55 : 39|16@0+ (0.001,0) [1|1] "V"  BMS
 SG_ BMU3_Vol_56 : 55|16@0+ (0.001,0) [1|1] "V"  BMS

BO_ 2282618883 BMU3_Vol_57: 8 BMU
 SG_ BMU3_Vol_57 : 7|16@0+ (0.001,0) [1|1] "V"  BMS
 SG_ BMU3_Vol_58 : 23|16@0+ (0.001,0) [1|1] "V"  BMS
 SG_ BMU3_Vol_59 : 39|16@0+ (0.001,0) [1|1] "V"  BMS
 SG_ BMU3_Vol_60 : 55|16@0+ (0.001,0) [1|1] "V"  BMS

BO_ 2282684419 BMU3_Vol_61: 8 BMU
 SG_ BMU3_Vol_61 : 7|16@0+ (0.001,0) [1|1] "V"  BMS
 SG_ BMU3_Vol_62 : 23|16@0+ (0.001,0) [1|1] "V"  BMS
 SG_ BMU3_Vol_63 : 39|16@0+ (0.001,0) [1|1] "V"  BMS
 SG_ BMU3_Vol_64 : 55|16@0+ (0.001,0) [1|1] "V"  BMS

BO_ 2282749955 BMU3_Vol_65: 8 BMU
 SG_ BMU3_Vol_65 : 7|16@0+ (0.001,0) [1|1] "V"  BMS
 SG_ BMU3_Vol_66 : 23|16@0+ (0.001,0) [1|1] "V"  BMS
 SG_ BMU3_Vol_67 : 39|16@0+ (0.001,0) [1|1] "V"  BMS
 SG_ BMU3_Vol_68 : 55|16@0+ (0.001,0) [1|1] "V"  BMS

BO_ 2282815491 BMU3_Vol_69: 8 BMU
 SG_ BMU3_Vol_69 : 7|16@0+ (0.001,0) [1|1] "V"  BMS
 SG_ BMU3_Vol_70 : 23|16@0+ (0.001,0) [1|1] "V"  BMS
 SG_ BMU3_Vol_71 : 39|16@0+ (0.001,0) [1|1] "V"  BMS
 SG_ BMU3_Vol_72 : 55|16@0+ (0.001,0) [1|1] "V"  BMS

BO_ 2282881027 BMU3_Vol_73: 8 BMU
 SG_ BMU3_Vol_73 : 7|16@0+ (0.001,0) [1|1] "V"  BMS
 SG_ BMU3_Vol_74 : 23|16@0+ (0.001,0) [1|1] "V"  BMS
 SG_ BMU3_Vol_75 : 39|16@0+ (0.001,0) [1|1] "V"  BMS
 SG_ BMU3_Vol_76 : 55|16@0+ (0.001,0) [1|1] "V"  BMS

BO_ 2282946563 BMU3_Vol_77: 8 BMU
 SG_ BMU3_Vol_77 : 7|16@0+ (0.001,0) [1|1] "V"  BMS
 SG_ BMU3_Vol_78 : 23|16@0+ (0.001,0) [1|1] "V"  BMS
 SG_ BMU3_Vol_79 : 39|16@0+ (0.001,0) [1|1] "V"  BMS
 SG_ BMU3_Vol_80 : 55|16@0+ (0.001,0) [1|1] "V"  BMS

BO_ 2283012099 BMU3_Vol_81: 8 BMU
 SG_ BMU3_Vol_81 : 7|16@0+ (0.001,0) [1|1] "V"  BMS
 SG_ BMU3_Vol_82 : 23|16@0+ (0.001,0) [1|1] "V"  BMS
 SG_ BMU3_Vol_83 : 39|16@0+ (0.001,0) [1|1] "V"  BMS
 SG_ BMU3_Vol_84 : 55|16@0+ (0.001,0) [1|1] "V"  BMS

BO_ 2283077635 BMU3_Vol_85: 8 BMU
 SG_ BMU3_Vol_85 : 7|16@0+ (0.001,0) [1|1] "V"  BMS
 SG_ BMU3_Vol_86 : 23|16@0+ (0.001,0) [1|1] "V"  BMS
 SG_ BMU3_Vol_87 : 39|16@0+ (0.001,0) [1|1] "V"  BMS
 SG_ BMU3_Vol_88 : 55|16@0+ (0.001,0) [1|1] "V"  BMS

BO_ 2283143171 BMU3_Vol_89: 8 BMU
 SG_ BMU3_Vol_89 : 7|16@0+ (0.001,0) [1|1] "V"  BMS
 SG_ BMU3_Vol_90 : 23|16@0+ (0.001,0) [1|1] "V"  BMS
 SG_ BMU3_Vol_91 : 39|16@0+ (0.001,0) [1|1] "V"  BMS
 SG_ BMU3_Vol_92 : 55|16@0+ (0.001,0) [1|1] "V"  BMS

BO_ 2283208707 BMU3_Vol_93: 8 BMU
 SG_ BMU3_Vol_93 : 7|16@0+ (0.001,0) [1|1] "V"  BMS
 SG_ BMU3_Vol_94 : 23|16@0+ (0.001,0) [1|1] "V"  BMS
 SG_ BMU3_Vol_95 : 39|16@0+ (0.001,0) [1|1] "V"  BMS
 SG_ BMU3_Vol_96 : 55|16@0+ (0.001,0) [1|1] "V"  BMS

BO_ 2281701380 BMU4_Vol_1: 8 BMU
 SG_ BMU4_Vol_1 : 7|16@0+ (0.001,0) [1|1] "V"  BMS
 SG_ BMU4_Vol_2 : 23|16@0+ (0.001,0) [1|1] "V"  BMS
 SG_ BMU4_Vol_3 : 39|16@0+ (0.001,0) [1|1] "V"  BMS
 SG_ BMU4_Vol_4 : 55|16@0+ (0.001,0) [1|1] "V"  BMS

BO_ 2281766916 BMU4_Vol_5: 8 BMU
 SG_ BMU4_Vol_5 : 7|16@0+ (0.001,0) [1|1] "V"  BMS
 SG_ BMU4_Vol_6 : 23|16@0+ (0.001,0) [1|1] "V"  BMS
 SG_ BMU4_Vol_7 : 39|16@0+ (0.001,0) [1|1] "V"  BMS
 SG_ BMU4_Vol_8 : 55|16@0+ (0.001,0) [1|1] "V"  BMS

BO_ 2281832452 BMU4_Vol_9: 8 BMU
 SG_ BMU4_Vol_9 : 7|16@0+ (0.001,0) [1|1] "V"  BMS
 SG_ BMU4_Vol_10 : 23|16@0+ (0.001,0) [1|1] "V"  BMS
 SG_ BMU4_Vol_11 : 39|16@0+ (0.001,0) [1|1] "V"  BMS
 SG_ BMU4_Vol_12 : 55|16@0+ (0.001,0) [1|1] "V"  BMS

BO_ 2281897988 BMU4_Vol_13: 8 BMU
 SG_ BMU4_Vol_13 : 7|16@0+ (0.001,0) [1|1] "V"  BMS
 SG_ BMU4_Vol_14 : 23|16@0+ (0.001,0) [1|1] "V"  BMS
 SG_ BMU4_Vol_15 : 39|16@0+ (0.001,0) [1|1] "V"  BMS
 SG_ BMU4_Vol_16 : 55|16@0+ (0.001,0) [1|1] "V"  BMS

BO_ 2281963524 BMU4_Vol_17: 8 BMU
 SG_ BMU4_Vol_17 : 7|16@0+ (0.001,0) [1|1] "V"  BMS
 SG_ BMU4_Vol_18 : 23|16@0+ (0.001,0) [1|1] "V"  BMS
 SG_ BMU4_Vol_19 : 39|16@0+ (0.001,0) [1|1] "V"  BMS
 SG_ BMU4_Vol_20 : 55|16@0+ (0.001,0) [1|1] "V"  BMS

BO_ 2282029060 BMU4_Vol_21: 8 BMU
 SG_ BMU4_Vol_21 : 7|16@0+ (0.001,0) [1|1] "V"  BMS
 SG_ BMU4_Vol_22 : 23|16@0+ (0.001,0) [1|1] "V"  BMS
 SG_ BMU4_Vol_23 : 39|16@0+ (0.001,0) [1|1] "V"  BMS
 SG_ BMU4_Vol_24 : 55|16@0+ (0.001,0) [1|1] "V"  BMS

BO_ 2282094596 BMU4_Vol_25: 8 BMU
 SG_ BMU4_Vol_25 : 7|16@0+ (0.001,0) [1|1] "V"  BMS
 SG_ BMU4_Vol_26 : 23|16@0+ (0.001,0) [1|1] "V"  BMS
 SG_ BMU4_Vol_27 : 39|16@0+ (0.001,0) [1|1] "V"  BMS
 SG_ BMU4_Vol_28 : 55|16@0+ (0.001,0) [1|1] "V"  BMS

BO_ 2282160132 BMU4_Vol_29: 8 BMU
 SG_ BMU4_Vol_29 : 7|16@0+ (0.001,0) [1|1] "V"  BMS
 SG_ BMU4_Vol_30 : 23|16@0+ (0.001,0) [1|1] "V"  BMS
 SG_ BMU4_Vol_31 : 39|16@0+ (0.001,0) [1|1] "V"  BMS
 SG_ BMU4_Vol_32 : 55|16@0+ (0.001,0) [1|1] "V"  BMS

BO_ 2282225668 BMU4_Vol_33: 8 BMU
 SG_ BMU4_Vol_33 : 7|16@0+ (0.001,0) [1|1] "V"  BMS
 SG_ BMU4_Vol_34 : 23|16@0+ (0.001,0) [1|1] "V"  BMS
 SG_ BMU4_Vol_35 : 39|16@0+ (0.001,0) [1|1] "V"  BMS
 SG_ BMU4_Vol_36 : 55|16@0+ (0.001,0) [1|1] "V"  BMS

BO_ 2282291204 BMU4_Vol_37: 8 BMU
 SG_ BMU4_Vol_37 : 7|16@0+ (0.001,0) [1|1] "V"  BMS
 SG_ BMU4_Vol_38 : 23|16@0+ (0.001,0) [1|1] "V"  BMS
 SG_ BMU4_Vol_39 : 39|16@0+ (0.001,0) [1|1] "V"  BMS
 SG_ BMU4_Vol_40 : 55|16@0+ (0.001,0) [1|1] "V"  BMS

BO_ 2282356740 BMU4_Vol_41: 8 BMU
 SG_ BMU4_Vol_41 : 7|16@0+ (0.001,0) [1|1] "V"  BMS
 SG_ BMU4_Vol_42 : 23|16@0+ (0.001,0) [1|1] "V"  BMS
 SG_ BMU4_Vol_43 : 39|16@0+ (0.001,0) [1|1] "V"  BMS
 SG_ BMU4_Vol_44 : 55|16@0+ (0.001,0) [1|1] "V"  BMS

BO_ 2282422276 BMU4_Vol_45: 8 BMU
 SG_ BMU4_Vol_45 : 7|16@0+ (0.001,0) [1|1] "V"  BMS
 SG_ BMU4_Vol_46 : 23|16@0+ (0.001,0) [1|1] "V"  BMS
 SG_ BMU4_Vol_47 : 39|16@0+ (0.001,0) [1|1] "V"  BMS
 SG_ BMU4_Vol_48 : 55|16@0+ (0.001,0) [1|1] "V"  BMS

BO_ 2282487812 BMU4_Vol_49: 8 BMU
 SG_ BMU4_Vol_49 : 7|16@0+ (0.001,0) [1|1] "V"  BMS
 SG_ BMU4_Vol_50 : 23|16@0+ (0.001,0) [1|1] "V"  BMS
 SG_ BMU4_Vol_51 : 39|16@0+ (0.001,0) [1|1] "V"  BMS
 SG_ BMU4_Vol_52 : 55|16@0+ (0.001,0) [1|1] "V"  BMS

BO_ 2282553348 BMU4_Vol_53: 8 BMU
 SG_ BMU4_Vol_53 : 7|16@0+ (0.001,0) [1|1] "V"  BMS
 SG_ BMU4_Vol_54 : 23|16@0+ (0.001,0) [1|1] "V"  BMS
 SG_ BMU4_Vol_55 : 39|16@0+ (0.001,0) [1|1] "V"  BMS
 SG_ BMU4_Vol_56 : 55|16@0+ (0.001,0) [1|1] "V"  BMS

BO_ 2282618884 BMU4_Vol_57: 8 BMU
 SG_ BMU4_Vol_57 : 7|16@0+ (0.001,0) [1|1] "V"  BMS
 SG_ BMU4_Vol_58 : 23|16@0+ (0.001,0) [1|1] "V"  BMS
 SG_ BMU4_Vol_59 : 39|16@0+ (0.001,0) [1|1] "V"  BMS
 SG_ BMU4_Vol_60 : 55|16@0+ (0.001,0) [1|1] "V"  BMS

BO_ 2282684420 BMU4_Vol_61: 8 BMU
 SG_ BMU4_Vol_61 : 7|16@0+ (0.001,0) [1|1] "V"  BMS
 SG_ BMU4_Vol_62 : 23|16@0+ (0.001,0) [1|1] "V"  BMS
 SG_ BMU4_Vol_63 : 39|16@0+ (0.001,0) [1|1] "V"  BMS
 SG_ BMU4_Vol_64 : 55|16@0+ (0.001,0) [1|1] "V"  BMS

BO_ 2282749956 BMU4_Vol_65: 8 BMU
 SG_ BMU4_Vol_65 : 7|16@0+ (0.001,0) [1|1] "V"  BMS
 SG_ BMU4_Vol_66 : 23|16@0+ (0.001,0) [1|1] "V"  BMS
 SG_ BMU4_Vol_67 : 39|16@0+ (0.001,0) [1|1] "V"  BMS
 SG_ BMU4_Vol_68 : 55|16@0+ (0.001,0) [1|1] "V"  BMS

BO_ 2282815492 BMU4_Vol_69: 8 BMU
 SG_ BMU4_Vol_69 : 7|16@0+ (0.001,0) [1|1] "V"  BMS
 SG_ BMU4_Vol_70 : 23|16@0+ (0.001,0) [1|1] "V"  BMS
 SG_ BMU4_Vol_71 : 39|16@0+ (0.001,0) [1|1] "V"  BMS
 SG_ BMU4_Vol_72 : 55|16@0+ (0.001,0) [1|1] "V"  BMS

BO_ 2282881028 BMU4_Vol_73: 8 BMU
 SG_ BMU4_Vol_73 : 7|16@0+ (0.001,0) [1|1] "V"  BMS
 SG_ BMU4_Vol_74 : 23|16@0+ (0.001,0) [1|1] "V"  BMS
 SG_ BMU4_Vol_75 : 39|16@0+ (0.001,0) [1|1] "V"  BMS
 SG_ BMU4_Vol_76 : 55|16@0+ (0.001,0) [1|1] "V"  BMS

BO_ 2282946564 BMU4_Vol_77: 8 BMU
 SG_ BMU4_Vol_77 : 7|16@0+ (0.001,0) [1|1] "V"  BMS
 SG_ BMU4_Vol_78 : 23|16@0+ (0.001,0) [1|1] "V"  BMS
 SG_ BMU4_Vol_79 : 39|16@0+ (0.001,0) [1|1] "V"  BMS
 SG_ BMU4_Vol_80 : 55|16@0+ (0.001,0) [1|1] "V"  BMS

BO_ 2283012100 BMU4_Vol_81: 8 BMU
 SG_ BMU4_Vol_81 : 7|16@0+ (0.001,0) [1|1] "V"  BMS
 SG_ BMU4_Vol_82 : 23|16@0+ (0.001,0) [1|1] "V"  BMS
 SG_ BMU4_Vol_83 : 39|16@0+ (0.001,0) [1|1] "V"  BMS
 SG_ BMU4_Vol_84 : 55|16@0+ (0.001,0) [1|1] "V"  BMS

BO_ 2283077636 BMU4_Vol_85: 8 BMU
 SG_ BMU4_Vol_85 : 7|16@0+ (0.001,0) [1|1] "V"  BMS
 SG_ BMU4_Vol_86 : 23|16@0+ (0.001,0) [1|1] "V"  BMS
 SG_ BMU4_Vol_87 : 39|16@0+ (0.001,0) [1|1] "V"  BMS
 SG_ BMU4_Vol_88 : 55|16@0+ (0.001,0) [1|1] "V"  BMS

BO_ 2283143172 BMU4_Vol_89: 8 BMU
 SG_ BMU4_Vol_89 : 7|16@0+ (0.001,0) [1|1] "V"  BMS
 SG_ BMU4_Vol_90 : 23|16@0+ (0.001,0) [1|1] "V"  BMS
 SG_ BMU4_Vol_91 : 39|16@0+ (0.001,0) [1|1] "V"  BMS
 SG_ BMU4_Vol_92 : 55|16@0+ (0.001,0) [1|1] "V"  BMS

BO_ 2283208708 BMU4_Vol_93: 8 BMU
 SG_ BMU4_Vol_93 : 7|16@0+ (0.001,0) [1|1] "V"  BMS
 SG_ BMU4_Vol_94 : 23|16@0+ (0.001,0) [1|1] "V"  BMS
 SG_ BMU4_Vol_95 : 39|16@0+ (0.001,0) [1|1] "V"  BMS
 SG_ BMU4_Vol_96 : 55|16@0+ (0.001,0) [1|1] "V"  BMS

BO_ 2281701381 BMU5_Vol_1: 8 BMU
 SG_ BMU5_Vol_1 : 7|16@0+ (0.001,0) [1|1] "V"  BMS
 SG_ BMU5_Vol_2 : 23|16@0+ (0.001,0) [1|1] "V"  BMS
 SG_ BMU5_Vol_3 : 39|16@0+ (0.001,0) [1|1] "V"  BMS
 SG_ BMU5_Vol_4 : 55|16@0+ (0.001,0) [1|1] "V"  BMS

BO_ 2281766917 BMU5_Vol_5: 8 BMU
 SG_ BMU5_Vol_5 : 7|16@0+ (0.001,0) [1|1] "V"  BMS
 SG_ BMU5_Vol_6 : 23|16@0+ (0.001,0) [1|1] "V"  BMS
 SG_ BMU5_Vol_7 : 39|16@0+ (0.001,0) [1|1] "V"  BMS
 SG_ BMU5_Vol_8 : 55|16@0+ (0.001,0) [1|1] "V"  BMS

BO_ 2281832453 BMU5_Vol_9: 8 BMU
 SG_ BMU5_Vol_9 : 7|16@0+ (0.001,0) [1|1] "V"  BMS
 SG_ BMU5_Vol_10 : 23|16@0+ (0.001,0) [1|1] "V"  BMS
 SG_ BMU5_Vol_11 : 39|16@0+ (0.001,0) [1|1] "V"  BMS
 SG_ BMU5_Vol_12 : 55|16@0+ (0.001,0) [1|1] "V"  BMS

BO_ 2281897989 BMU5_Vol_13: 8 BMU
 SG_ BMU5_Vol_13 : 7|16@0+ (0.001,0) [1|1] "V"  BMS
 SG_ BMU5_Vol_14 : 23|16@0+ (0.001,0) [1|1] "V"  BMS
 SG_ BMU5_Vol_15 : 39|16@0+ (0.001,0) [1|1] "V"  BMS
 SG_ BMU5_Vol_16 : 55|16@0+ (0.001,0) [1|1] "V"  BMS

BO_ 2281963525 BMU5_Vol_17: 8 BMU
 SG_ BMU5_Vol_17 : 7|16@0+ (0.001,0) [1|1] "V"  BMS
 SG_ BMU5_Vol_18 : 23|16@0+ (0.001,0) [1|1] "V"  BMS
 SG_ BMU5_Vol_19 : 39|16@0+ (0.001,0) [1|1] "V"  BMS
 SG_ BMU5_Vol_20 : 55|16@0+ (0.001,0) [1|1] "V"  BMS

BO_ 2282029061 BMU5_Vol_21: 8 BMU
 SG_ BMU5_Vol_21 : 7|16@0+ (0.001,0) [1|1] "V"  BMS
 SG_ BMU5_Vol_22 : 23|16@0+ (0.001,0) [1|1] "V"  BMS
 SG_ BMU5_Vol_23 : 39|16@0+ (0.001,0) [1|1] "V"  BMS
 SG_ BMU5_Vol_24 : 55|16@0+ (0.001,0) [1|1] "V"  BMS

BO_ 2282094597 BMU5_Vol_25: 8 BMU
 SG_ BMU5_Vol_25 : 7|16@0+ (0.001,0) [1|1] "V"  BMS
 SG_ BMU5_Vol_26 : 23|16@0+ (0.001,0) [1|1] "V"  BMS
 SG_ BMU5_Vol_27 : 39|16@0+ (0.001,0) [1|1] "V"  BMS
 SG_ BMU5_Vol_28 : 55|16@0+ (0.001,0) [1|1] "V"  BMS

BO_ 2282160133 BMU5_Vol_29: 8 BMU
 SG_ BMU5_Vol_29 : 7|16@0+ (0.001,0) [1|1] "V"  BMS
 SG_ BMU5_Vol_30 : 23|16@0+ (0.001,0) [1|1] "V"  BMS
 SG_ BMU5_Vol_31 : 39|16@0+ (0.001,0) [1|1] "V"  BMS
 SG_ BMU5_Vol_32 : 55|16@0+ (0.001,0) [1|1] "V"  BMS

BO_ 2282225669 BMU5_Vol_33: 8 BMU
 SG_ BMU5_Vol_33 : 7|16@0+ (0.001,0) [1|1] "V"  BMS
 SG_ BMU5_Vol_34 : 23|16@0+ (0.001,0) [1|1] "V"  BMS
 SG_ BMU5_Vol_35 : 39|16@0+ (0.001,0) [1|1] "V"  BMS
 SG_ BMU5_Vol_36 : 55|16@0+ (0.001,0) [1|1] "V"  BMS

BO_ 2282291205 BMU5_Vol_37: 8 BMU
 SG_ BMU5_Vol_37 : 7|16@0+ (0.001,0) [1|1] "V"  BMS
 SG_ BMU5_Vol_38 : 23|16@0+ (0.001,0) [1|1] "V"  BMS
 SG_ BMU5_Vol_39 : 39|16@0+ (0.001,0) [1|1] "V"  BMS
 SG_ BMU5_Vol_40 : 55|16@0+ (0.001,0) [1|1] "V"  BMS

BO_ 2282356741 BMU5_Vol_41: 8 BMU
 SG_ BMU5_Vol_41 : 7|16@0+ (0.001,0) [1|1] "V"  BMS
 SG_ BMU5_Vol_42 : 23|16@0+ (0.001,0) [1|1] "V"  BMS
 SG_ BMU5_Vol_43 : 39|16@0+ (0.001,0) [1|1] "V"  BMS
 SG_ BMU5_Vol_44 : 55|16@0+ (0.001,0) [1|1] "V"  BMS

BO_ 2282422277 BMU5_Vol_45: 8 BMU
 SG_ BMU5_Vol_45 : 7|16@0+ (0.001,0) [1|1] "V"  BMS
 SG_ BMU5_Vol_46 : 23|16@0+ (0.001,0) [1|1] "V"  BMS
 SG_ BMU5_Vol_47 : 39|16@0+ (0.001,0) [1|1] "V"  BMS
 SG_ BMU5_Vol_48 : 55|16@0+ (0.001,0) [1|1] "V"  BMS

BO_ 2282487813 BMU5_Vol_49: 8 BMU
 SG_ BMU5_Vol_49 : 7|16@0+ (0.001,0) [1|1] "V"  BMS
 SG_ BMU5_Vol_50 : 23|16@0+ (0.001,0) [1|1] "V"  BMS
 SG_ BMU5_Vol_51 : 39|16@0+ (0.001,0) [1|1] "V"  BMS
 SG_ BMU5_Vol_52 : 55|16@0+ (0.001,0) [1|1] "V"  BMS

BO_ 2282553349 BMU5_Vol_53: 8 BMU
 SG_ BMU5_Vol_53 : 7|16@0+ (0.001,0) [1|1] "V"  BMS
 SG_ BMU5_Vol_54 : 23|16@0+ (0.001,0) [1|1] "V"  BMS
 SG_ BMU5_Vol_55 : 39|16@0+ (0.001,0) [1|1] "V"  BMS
 SG_ BMU5_Vol_56 : 55|16@0+ (0.001,0) [1|1] "V"  BMS

BO_ 2282618885 BMU5_Vol_57: 8 BMU
 SG_ BMU5_Vol_57 : 7|16@0+ (0.001,0) [1|1] "V"  BMS
 SG_ BMU5_Vol_58 : 23|16@0+ (0.001,0) [1|1] "V"  BMS
 SG_ BMU5_Vol_59 : 39|16@0+ (0.001,0) [1|1] "V"  BMS
 SG_ BMU5_Vol_60 : 55|16@0+ (0.001,0) [1|1] "V"  BMS

BO_ 2282684421 BMU5_Vol_61: 8 BMU
 SG_ BMU5_Vol_61 : 7|16@0+ (0.001,0) [1|1] "V"  BMS
 SG_ BMU5_Vol_62 : 23|16@0+ (0.001,0) [1|1] "V"  BMS
 SG_ BMU5_Vol_63 : 39|16@0+ (0.001,0) [1|1] "V"  BMS
 SG_ BMU5_Vol_64 : 55|16@0+ (0.001,0) [1|1] "V"  BMS

BO_ 2282749957 BMU5_Vol_65: 8 BMU
 SG_ BMU5_Vol_65 : 7|16@0+ (0.001,0) [1|1] "V"  BMS
 SG_ BMU5_Vol_66 : 23|16@0+ (0.001,0) [1|1] "V"  BMS
 SG_ BMU5_Vol_67 : 39|16@0+ (0.001,0) [1|1] "V"  BMS
 SG_ BMU5_Vol_68 : 55|16@0+ (0.001,0) [1|1] "V"  BMS

BO_ 2282815493 BMU5_Vol_69: 8 BMU
 SG_ BMU5_Vol_69 : 7|16@0+ (0.001,0) [1|1] "V"  BMS
 SG_ BMU5_Vol_70 : 23|16@0+ (0.001,0) [1|1] "V"  BMS
 SG_ BMU5_Vol_71 : 39|16@0+ (0.001,0) [1|1] "V"  BMS
 SG_ BMU5_Vol_72 : 55|16@0+ (0.001,0) [1|1] "V"  BMS

BO_ 2282881029 BMU5_Vol_73: 8 BMU
 SG_ BMU5_Vol_73 : 7|16@0+ (0.001,0) [1|1] "V"  BMS
 SG_ BMU5_Vol_74 : 23|16@0+ (0.001,0) [1|1] "V"  BMS
 SG_ BMU5_Vol_75 : 39|16@0+ (0.001,0) [1|1] "V"  BMS
 SG_ BMU5_Vol_76 : 55|16@0+ (0.001,0) [1|1] "V"  BMS

BO_ 2282946565 BMU5_Vol_77: 8 BMU
 SG_ BMU5_Vol_77 : 7|16@0+ (0.001,0) [1|1] "V"  BMS
 SG_ BMU5_Vol_78 : 23|16@0+ (0.001,0) [1|1] "V"  BMS
 SG_ BMU5_Vol_79 : 39|16@0+ (0.001,0) [1|1] "V"  BMS
 SG_ BMU5_Vol_80 : 55|16@0+ (0.001,0) [1|1] "V"  BMS

BO_ 2283012101 BMU5_Vol_81: 8 BMU
 SG_ BMU5_Vol_81 : 7|16@0+ (0.001,0) [1|1] "V"  BMS
 SG_ BMU5_Vol_82 : 23|16@0+ (0.001,0) [1|1] "V"  BMS
 SG_ BMU5_Vol_83 : 39|16@0+ (0.001,0) [1|1] "V"  BMS
 SG_ BMU5_Vol_84 : 55|16@0+ (0.001,0) [1|1] "V"  BMS

BO_ 2283077637 BMU5_Vol_85: 8 BMU
 SG_ BMU5_Vol_85 : 7|16@0+ (0.001,0) [1|1] "V"  BMS
 SG_ BMU5_Vol_86 : 23|16@0+ (0.001,0) [1|1] "V"  BMS
 SG_ BMU5_Vol_87 : 39|16@0+ (0.001,0) [1|1] "V"  BMS
 SG_ BMU5_Vol_88 : 55|16@0+ (0.001,0) [1|1] "V"  BMS

BO_ 2283143173 BMU5_Vol_89: 8 BMU
 SG_ BMU5_Vol_89 : 7|16@0+ (0.001,0) [1|1] "V"  BMS
 SG_ BMU5_Vol_90 : 23|16@0+ (0.001,0) [1|1] "V"  BMS
 SG_ BMU5_Vol_91 : 39|16@0+ (0.001,0) [1|1] "V"  BMS
 SG_ BMU5_Vol_92 : 55|16@0+ (0.001,0) [1|1] "V"  BMS

BO_ 2283208709 BMU5_Vol_93: 8 BMU
 SG_ BMU5_Vol_93 : 7|16@0+ (0.001,0) [1|1] "V"  BMS
 SG_ BMU5_Vol_94 : 23|16@0+ (0.001,0) [1|1] "V"  BMS
 SG_ BMU5_Vol_95 : 39|16@0+ (0.001,0) [1|1] "V"  BMS
 SG_ BMU5_Vol_96 : 55|16@0+ (0.001,0) [1|1] "V"  BMS

BO_ 2281701382 BMU6_Vol_1: 8 BMU
 SG_ BMU6_Vol_1 : 7|16@0+ (0.001,0) [1|1] "V"  BMS
 SG_ BMU6_Vol_2 : 23|16@0+ (0.001,0) [1|1] "V"  BMS
 SG_ BMU6_Vol_3 : 39|16@0+ (0.001,0) [1|1] "V"  BMS
 SG_ BMU6_Vol_4 : 55|16@0+ (0.001,0) [1|1] "V"  BMS

BO_ 2281766918 BMU6_Vol_5: 8 BMU
 SG_ BMU6_Vol_5 : 7|16@0+ (0.001,0) [1|1] "V"  BMS
 SG_ BMU6_Vol_6 : 23|16@0+ (0.001,0) [1|1] "V"  BMS
 SG_ BMU6_Vol_7 : 39|16@0+ (0.001,0) [1|1] "V"  BMS
 SG_ BMU6_Vol_8 : 55|16@0+ (0.001,0) [1|1] "V"  BMS

BO_ 2281832454 BMU6_Vol_9: 8 BMU
 SG_ BMU6_Vol_9 : 7|16@0+ (0.001,0) [1|1] "V"  BMS
 SG_ BMU6_Vol_10 : 23|16@0+ (0.001,0) [1|1] "V"  BMS
 SG_ BMU6_Vol_11 : 39|16@0+ (0.001,0) [1|1] "V"  BMS
 SG_ BMU6_Vol_12 : 55|16@0+ (0.001,0) [1|1] "V"  BMS

BO_ 2281897990 BMU6_Vol_13: 8 BMU
 SG_ BMU6_Vol_13 : 7|16@0+ (0.001,0) [1|1] "V"  BMS
 SG_ BMU6_Vol_14 : 23|16@0+ (0.001,0) [1|1] "V"  BMS
 SG_ BMU6_Vol_15 : 39|16@0+ (0.001,0) [1|1] "V"  BMS
 SG_ BMU6_Vol_16 : 55|16@0+ (0.001,0) [1|1] "V"  BMS

BO_ 2281963526 BMU6_Vol_17: 8 BMU
 SG_ BMU6_Vol_17 : 7|16@0+ (0.001,0) [1|1] "V"  BMS
 SG_ BMU6_Vol_18 : 23|16@0+ (0.001,0) [1|1] "V"  BMS
 SG_ BMU6_Vol_19 : 39|16@0+ (0.001,0) [1|1] "V"  BMS
 SG_ BMU6_Vol_20 : 55|16@0+ (0.001,0) [1|1] "V"  BMS

BO_ 2282029062 BMU6_Vol_21: 8 BMU
 SG_ BMU6_Vol_21 : 7|16@0+ (0.001,0) [1|1] "V"  BMS
 SG_ BMU6_Vol_22 : 23|16@0+ (0.001,0) [1|1] "V"  BMS
 SG_ BMU6_Vol_23 : 39|16@0+ (0.001,0) [1|1] "V"  BMS
 SG_ BMU6_Vol_24 : 55|16@0+ (0.001,0) [1|1] "V"  BMS

BO_ 2282094598 BMU6_Vol_25: 8 BMU
 SG_ BMU6_Vol_25 : 7|16@0+ (0.001,0) [1|1] "V"  BMS
 SG_ BMU6_Vol_26 : 23|16@0+ (0.001,0) [1|1] "V"  BMS
 SG_ BMU6_Vol_27 : 39|16@0+ (0.001,0) [1|1] "V"  BMS
 SG_ BMU6_Vol_28 : 55|16@0+ (0.001,0) [1|1] "V"  BMS

BO_ 2282160134 BMU6_Vol_29: 8 BMU
 SG_ BMU6_Vol_29 : 7|16@0+ (0.001,0) [1|1] "V"  BMS
 SG_ BMU6_Vol_30 : 23|16@0+ (0.001,0) [1|1] "V"  BMS
 SG_ BMU6_Vol_31 : 39|16@0+ (0.001,0) [1|1] "V"  BMS
 SG_ BMU6_Vol_32 : 55|16@0+ (0.001,0) [1|1] "V"  BMS

BO_ 2282225670 BMU6_Vol_33: 8 BMU
 SG_ BMU6_Vol_33 : 7|16@0+ (0.001,0) [1|1] "V"  BMS
 SG_ BMU6_Vol_34 : 23|16@0+ (0.001,0) [1|1] "V"  BMS
 SG_ BMU6_Vol_35 : 39|16@0+ (0.001,0) [1|1] "V"  BMS
 SG_ BMU6_Vol_36 : 55|16@0+ (0.001,0) [1|1] "V"  BMS

BO_ 2282291206 BMU6_Vol_37: 8 BMU
 SG_ BMU6_Vol_37 : 7|16@0+ (0.001,0) [1|1] "V"  BMS
 SG_ BMU6_Vol_38 : 23|16@0+ (0.001,0) [1|1] "V"  BMS
 SG_ BMU6_Vol_39 : 39|16@0+ (0.001,0) [1|1] "V"  BMS
 SG_ BMU6_Vol_40 : 55|16@0+ (0.001,0) [1|1] "V"  BMS

BO_ 2282356742 BMU6_Vol_41: 8 BMU
 SG_ BMU6_Vol_41 : 7|16@0+ (0.001,0) [1|1] "V"  BMS
 SG_ BMU6_Vol_42 : 23|16@0+ (0.001,0) [1|1] "V"  BMS
 SG_ BMU6_Vol_43 : 39|16@0+ (0.001,0) [1|1] "V"  BMS
 SG_ BMU6_Vol_44 : 55|16@0+ (0.001,0) [1|1] "V"  BMS

BO_ 2282422278 BMU6_Vol_45: 8 BMU
 SG_ BMU6_Vol_45 : 7|16@0+ (0.001,0) [1|1] "V"  BMS
 SG_ BMU6_Vol_46 : 23|16@0+ (0.001,0) [1|1] "V"  BMS
 SG_ BMU6_Vol_47 : 39|16@0+ (0.001,0) [1|1] "V"  BMS
 SG_ BMU6_Vol_48 : 55|16@0+ (0.001,0) [1|1] "V"  BMS

BO_ 2282487814 BMU6_Vol_49: 8 BMU
 SG_ BMU6_Vol_49 : 7|16@0+ (0.001,0) [1|1] "V"  BMS
 SG_ BMU6_Vol_50 : 23|16@0+ (0.001,0) [1|1] "V"  BMS
 SG_ BMU6_Vol_51 : 39|16@0+ (0.001,0) [1|1] "V"  BMS
 SG_ BMU6_Vol_52 : 55|16@0+ (0.001,0) [1|1] "V"  BMS

BO_ 2282553350 BMU6_Vol_53: 8 BMU
 SG_ BMU6_Vol_53 : 7|16@0+ (0.001,0) [1|1] "V"  BMS
 SG_ BMU6_Vol_54 : 23|16@0+ (0.001,0) [1|1] "V"  BMS
 SG_ BMU6_Vol_55 : 39|16@0+ (0.001,0) [1|1] "V"  BMS
 SG_ BMU6_Vol_56 : 55|16@0+ (0.001,0) [1|1] "V"  BMS

BO_ 2282618886 BMU6_Vol_57: 8 BMU
 SG_ BMU6_Vol_57 : 7|16@0+ (0.001,0) [1|1] "V"  BMS
 SG_ BMU6_Vol_58 : 23|16@0+ (0.001,0) [1|1] "V"  BMS
 SG_ BMU6_Vol_59 : 39|16@0+ (0.001,0) [1|1] "V"  BMS
 SG_ BMU6_Vol_60 : 55|16@0+ (0.001,0) [1|1] "V"  BMS

BO_ 2282684422 BMU6_Vol_61: 8 BMU
 SG_ BMU6_Vol_61 : 7|16@0+ (0.001,0) [1|1] "V"  BMS
 SG_ BMU6_Vol_62 : 23|16@0+ (0.001,0) [1|1] "V"  BMS
 SG_ BMU6_Vol_63 : 39|16@0+ (0.001,0) [1|1] "V"  BMS
 SG_ BMU6_Vol_64 : 55|16@0+ (0.001,0) [1|1] "V"  BMS

BO_ 2282749958 BMU6_Vol_65: 8 BMU
 SG_ BMU6_Vol_65 : 7|16@0+ (0.001,0) [1|1] "V"  BMS
 SG_ BMU6_Vol_66 : 23|16@0+ (0.001,0) [1|1] "V"  BMS
 SG_ BMU6_Vol_67 : 39|16@0+ (0.001,0) [1|1] "V"  BMS
 SG_ BMU6_Vol_68 : 55|16@0+ (0.001,0) [1|1] "V"  BMS

BO_ 2282815494 BMU6_Vol_69: 8 BMU
 SG_ BMU6_Vol_69 : 7|16@0+ (0.001,0) [1|1] "V"  BMS
 SG_ BMU6_Vol_70 : 23|16@0+ (0.001,0) [1|1] "V"  BMS
 SG_ BMU6_Vol_71 : 39|16@0+ (0.001,0) [1|1] "V"  BMS
 SG_ BMU6_Vol_72 : 55|16@0+ (0.001,0) [1|1] "V"  BMS

BO_ 2282881030 BMU6_Vol_73: 8 BMU
 SG_ BMU6_Vol_73 : 7|16@0+ (0.001,0) [1|1] "V"  BMS
 SG_ BMU6_Vol_74 : 23|16@0+ (0.001,0) [1|1] "V"  BMS
 SG_ BMU6_Vol_75 : 39|16@0+ (0.001,0) [1|1] "V"  BMS
 SG_ BMU6_Vol_76 : 55|16@0+ (0.001,0) [1|1] "V"  BMS

BO_ 2282946566 BMU6_Vol_77: 8 BMU
 SG_ BMU6_Vol_77 : 7|16@0+ (0.001,0) [1|1] "V"  BMS
 SG_ BMU6_Vol_78 : 23|16@0+ (0.001,0) [1|1] "V"  BMS
 SG_ BMU6_Vol_79 : 39|16@0+ (0.001,0) [1|1] "V"  BMS
 SG_ BMU6_Vol_80 : 55|16@0+ (0.001,0) [1|1] "V"  BMS

BO_ 2283012102 BMU6_Vol_81: 8 BMU
 SG_ BMU6_Vol_81 : 7|16@0+ (0.001,0) [1|1] "V"  BMS
 SG_ BMU6_Vol_82 : 23|16@0+ (0.001,0) [1|1] "V"  BMS
 SG_ BMU6_Vol_83 : 39|16@0+ (0.001,0) [1|1] "V"  BMS
 SG_ BMU6_Vol_84 : 55|16@0+ (0.001,0) [1|1] "V"  BMS

BO_ 2283077638 BMU6_Vol_85: 8 BMU
 SG_ BMU6_Vol_85 : 7|16@0+ (0.001,0) [1|1] "V"  BMS
 SG_ BMU6_Vol_86 : 23|16@0+ (0.001,0) [1|1] "V"  BMS
 SG_ BMU6_Vol_87 : 39|16@0+ (0.001,0) [1|1] "V"  BMS
 SG_ BMU6_Vol_88 : 55|16@0+ (0.001,0) [1|1] "V"  BMS

BO_ 2283143174 BMU6_Vol_89: 8 BMU
 SG_ BMU6_Vol_89 : 7|16@0+ (0.001,0) [1|1] "V"  BMS
 SG_ BMU6_Vol_90 : 23|16@0+ (0.001,0) [1|1] "V"  BMS
 SG_ BMU6_Vol_91 : 39|16@0+ (0.001,0) [1|1] "V"  BMS
 SG_ BMU6_Vol_92 : 55|16@0+ (0.001,0) [1|1] "V"  BMS

BO_ 2283208710 BMU6_Vol_93: 8 BMU
 SG_ BMU6_Vol_93 : 7|16@0+ (0.001,0) [1|1] "V"  BMS
 SG_ BMU6_Vol_94 : 23|16@0+ (0.001,0) [1|1] "V"  BMS
 SG_ BMU6_Vol_95 : 39|16@0+ (0.001,0) [1|1] "V"  BMS
 SG_ BMU6_Vol_96 : 55|16@0+ (0.001,0) [1|1] "V"  BMS

BO_ 2281701383 BMU7_Vol_1: 8 BMU
 SG_ BMU7_Vol_1 : 7|16@0+ (0.001,0) [1|1] "V"  BMS
 SG_ BMU7_Vol_2 : 23|16@0+ (0.001,0) [1|1] "V"  BMS
 SG_ BMU7_Vol_3 : 39|16@0+ (0.001,0) [1|1] "V"  BMS
 SG_ BMU7_Vol_4 : 55|16@0+ (0.001,0) [1|1] "V"  BMS

BO_ 2281766919 BMU7_Vol_5: 8 BMU
 SG_ BMU7_Vol_5 : 7|16@0+ (0.001,0) [1|1] "V"  BMS
 SG_ BMU7_Vol_6 : 23|16@0+ (0.001,0) [1|1] "V"  BMS
 SG_ BMU7_Vol_7 : 39|16@0+ (0.001,0) [1|1] "V"  BMS
 SG_ BMU7_Vol_8 : 55|16@0+ (0.001,0) [1|1] "V"  BMS

BO_ 2281832455 BMU7_Vol_9: 8 BMU
 SG_ BMU7_Vol_9 : 7|16@0+ (0.001,0) [1|1] "V"  BMS
 SG_ BMU7_Vol_10 : 23|16@0+ (0.001,0) [1|1] "V"  BMS
 SG_ BMU7_Vol_11 : 39|16@0+ (0.001,0) [1|1] "V"  BMS
 SG_ BMU7_Vol_12 : 55|16@0+ (0.001,0) [1|1] "V"  BMS

BO_ 2281897991 BMU7_Vol_13: 8 BMU
 SG_ BMU7_Vol_13 : 7|16@0+ (0.001,0) [1|1] "V"  BMS
 SG_ BMU7_Vol_14 : 23|16@0+ (0.001,0) [1|1] "V"  BMS
 SG_ BMU7_Vol_15 : 39|16@0+ (0.001,0) [1|1] "V"  BMS
 SG_ BMU7_Vol_16 : 55|16@0+ (0.001,0) [1|1] "V"  BMS

BO_ 2281963527 BMU7_Vol_17: 8 BMU
 SG_ BMU7_Vol_17 : 7|16@0+ (0.001,0) [1|1] "V"  BMS
 SG_ BMU7_Vol_18 : 23|16@0+ (0.001,0) [1|1] "V"  BMS
 SG_ BMU7_Vol_19 : 39|16@0+ (0.001,0) [1|1] "V"  BMS
 SG_ BMU7_Vol_20 : 55|16@0+ (0.001,0) [1|1] "V"  BMS

BO_ 2282029063 BMU7_Vol_21: 8 BMU
 SG_ BMU7_Vol_21 : 7|16@0+ (0.001,0) [1|1] "V"  BMS
 SG_ BMU7_Vol_22 : 23|16@0+ (0.001,0) [1|1] "V"  BMS
 SG_ BMU7_Vol_23 : 39|16@0+ (0.001,0) [1|1] "V"  BMS
 SG_ BMU7_Vol_24 : 55|16@0+ (0.001,0) [1|1] "V"  BMS

BO_ 2282094599 BMU7_Vol_25: 8 BMU
 SG_ BMU7_Vol_25 : 7|16@0+ (0.001,0) [1|1] "V"  BMS
 SG_ BMU7_Vol_26 : 23|16@0+ (0.001,0) [1|1] "V"  BMS
 SG_ BMU7_Vol_27 : 39|16@0+ (0.001,0) [1|1] "V"  BMS
 SG_ BMU7_Vol_28 : 55|16@0+ (0.001,0) [1|1] "V"  BMS

BO_ 2282160135 BMU7_Vol_29: 8 BMU
 SG_ BMU7_Vol_29 : 7|16@0+ (0.001,0) [1|1] "V"  BMS
 SG_ BMU7_Vol_30 : 23|16@0+ (0.001,0) [1|1] "V"  BMS
 SG_ BMU7_Vol_31 : 39|16@0+ (0.001,0) [1|1] "V"  BMS
 SG_ BMU7_Vol_32 : 55|16@0+ (0.001,0) [1|1] "V"  BMS

BO_ 2282225671 BMU7_Vol_33: 8 BMU
 SG_ BMU7_Vol_33 : 7|16@0+ (0.001,0) [1|1] "V"  BMS
 SG_ BMU7_Vol_34 : 23|16@0+ (0.001,0) [1|1] "V"  BMS
 SG_ BMU7_Vol_35 : 39|16@0+ (0.001,0) [1|1] "V"  BMS
 SG_ BMU7_Vol_36 : 55|16@0+ (0.001,0) [1|1] "V"  BMS

BO_ 2282291207 BMU7_Vol_37: 8 BMU
 SG_ BMU7_Vol_37 : 7|16@0+ (0.001,0) [1|1] "V"  BMS
 SG_ BMU7_Vol_38 : 23|16@0+ (0.001,0) [1|1] "V"  BMS
 SG_ BMU7_Vol_39 : 39|16@0+ (0.001,0) [1|1] "V"  BMS
 SG_ BMU7_Vol_40 : 55|16@0+ (0.001,0) [1|1] "V"  BMS

BO_ 2282356743 BMU7_Vol_41: 8 BMU
 SG_ BMU7_Vol_41 : 7|16@0+ (0.001,0) [1|1] "V"  BMS
 SG_ BMU7_Vol_42 : 23|16@0+ (0.001,0) [1|1] "V"  BMS
 SG_ BMU7_Vol_43 : 39|16@0+ (0.001,0) [1|1] "V"  BMS
 SG_ BMU7_Vol_44 : 55|16@0+ (0.001,0) [1|1] "V"  BMS

BO_ 2282422279 BMU7_Vol_45: 8 BMU
 SG_ BMU7_Vol_45 : 7|16@0+ (0.001,0) [1|1] "V"  BMS
 SG_ BMU7_Vol_46 : 23|16@0+ (0.001,0) [1|1] "V"  BMS
 SG_ BMU7_Vol_47 : 39|16@0+ (0.001,0) [1|1] "V"  BMS
 SG_ BMU7_Vol_48 : 55|16@0+ (0.001,0) [1|1] "V"  BMS

BO_ 2282487815 BMU7_Vol_49: 8 BMU
 SG_ BMU7_Vol_49 : 7|16@0+ (0.001,0) [1|1] "V"  BMS
 SG_ BMU7_Vol_50 : 23|16@0+ (0.001,0) [1|1] "V"  BMS
 SG_ BMU7_Vol_51 : 39|16@0+ (0.001,0) [1|1] "V"  BMS
 SG_ BMU7_Vol_52 : 55|16@0+ (0.001,0) [1|1] "V"  BMS

BO_ 2282553351 BMU7_Vol_53: 8 BMU
 SG_ BMU7_Vol_53 : 7|16@0+ (0.001,0) [1|1] "V"  BMS
 SG_ BMU7_Vol_54 : 23|16@0+ (0.001,0) [1|1] "V"  BMS
 SG_ BMU7_Vol_55 : 39|16@0+ (0.001,0) [1|1] "V"  BMS
 SG_ BMU7_Vol_56 : 55|16@0+ (0.001,0) [1|1] "V"  BMS

BO_ 2282618887 BMU7_Vol_57: 8 BMU
 SG_ BMU7_Vol_57 : 7|16@0+ (0.001,0) [1|1] "V"  BMS
 SG_ BMU7_Vol_58 : 23|16@0+ (0.001,0) [1|1] "V"  BMS
 SG_ BMU7_Vol_59 : 39|16@0+ (0.001,0) [1|1] "V"  BMS
 SG_ BMU7_Vol_60 : 55|16@0+ (0.001,0) [1|1] "V"  BMS

BO_ 2282684423 BMU7_Vol_61: 8 BMU
 SG_ BMU7_Vol_61 : 7|16@0+ (0.001,0) [1|1] "V"  BMS
 SG_ BMU7_Vol_62 : 23|16@0+ (0.001,0) [1|1] "V"  BMS
 SG_ BMU7_Vol_63 : 39|16@0+ (0.001,0) [1|1] "V"  BMS
 SG_ BMU7_Vol_64 : 55|16@0+ (0.001,0) [1|1] "V"  BMS

BO_ 2282749959 BMU7_Vol_65: 8 BMU
 SG_ BMU7_Vol_65 : 7|16@0+ (0.001,0) [1|1] "V"  BMS
 SG_ BMU7_Vol_66 : 23|16@0+ (0.001,0) [1|1] "V"  BMS
 SG_ BMU7_Vol_67 : 39|16@0+ (0.001,0) [1|1] "V"  BMS
 SG_ BMU7_Vol_68 : 55|16@0+ (0.001,0) [1|1] "V"  BMS

BO_ 2282815495 BMU7_Vol_69: 8 BMU
 SG_ BMU7_Vol_69 : 7|16@0+ (0.001,0) [1|1] "V"  BMS
 SG_ BMU7_Vol_70 : 23|16@0+ (0.001,0) [1|1] "V"  BMS
 SG_ BMU7_Vol_71 : 39|16@0+ (0.001,0) [1|1] "V"  BMS
 SG_ BMU7_Vol_72 : 55|16@0+ (0.001,0) [1|1] "V"  BMS

BO_ 2282881031 BMU7_Vol_73: 8 BMU
 SG_ BMU7_Vol_73 : 7|16@0+ (0.001,0) [1|1] "V"  BMS
 SG_ BMU7_Vol_74 : 23|16@0+ (0.001,0) [1|1] "V"  BMS
 SG_ BMU7_Vol_75 : 39|16@0+ (0.001,0) [1|1] "V"  BMS
 SG_ BMU7_Vol_76 : 55|16@0+ (0.001,0) [1|1] "V"  BMS

BO_ 2282946567 BMU7_Vol_77: 8 BMU
 SG_ BMU7_Vol_77 : 7|16@0+ (0.001,0) [1|1] "V"  BMS
 SG_ BMU7_Vol_78 : 23|16@0+ (0.001,0) [1|1] "V"  BMS
 SG_ BMU7_Vol_79 : 39|16@0+ (0.001,0) [1|1] "V"  BMS
 SG_ BMU7_Vol_80 : 55|16@0+ (0.001,0) [1|1] "V"  BMS

BO_ 2283012103 BMU7_Vol_81: 8 BMU
 SG_ BMU7_Vol_81 : 7|16@0+ (0.001,0) [1|1] "V"  BMS
 SG_ BMU7_Vol_82 : 23|16@0+ (0.001,0) [1|1] "V"  BMS
 SG_ BMU7_Vol_83 : 39|16@0+ (0.001,0) [1|1] "V"  BMS
 SG_ BMU7_Vol_84 : 55|16@0+ (0.001,0) [1|1] "V"  BMS

BO_ 2283077639 BMU7_Vol_85: 8 BMU
 SG_ BMU7_Vol_85 : 7|16@0+ (0.001,0) [1|1] "V"  BMS
 SG_ BMU7_Vol_86 : 23|16@0+ (0.001,0) [1|1] "V"  BMS
 SG_ BMU7_Vol_87 : 39|16@0+ (0.001,0) [1|1] "V"  BMS
 SG_ BMU7_Vol_88 : 55|16@0+ (0.001,0) [1|1] "V"  BMS

BO_ 2283143175 BMU7_Vol_89: 8 BMU
 SG_ BMU7_Vol_89 : 7|16@0+ (0.001,0) [1|1] "V"  BMS
 SG_ BMU7_Vol_90 : 23|16@0+ (0.001,0) [1|1] "V"  BMS
 SG_ BMU7_Vol_91 : 39|16@0+ (0.001,0) [1|1] "V"  BMS
 SG_ BMU7_Vol_92 : 55|16@0+ (0.001,0) [1|1] "V"  BMS

BO_ 2283208711 BMU7_Vol_93: 8 BMU
 SG_ BMU7_Vol_93 : 7|16@0+ (0.001,0) [1|1] "V"  BMS
 SG_ BMU7_Vol_94 : 23|16@0+ (0.001,0) [1|1] "V"  BMS
 SG_ BMU7_Vol_95 : 39|16@0+ (0.001,0) [1|1] "V"  BMS
 SG_ BMU7_Vol_96 : 55|16@0+ (0.001,0) [1|1] "V"  BMS

BO_ 2281701384 BMU8_Vol_1: 8 BMU
 SG_ BMU8_Vol_1 : 7|16@0+ (0.001,0) [1|1] "V"  BMS
 SG_ BMU8_Vol_2 : 23|16@0+ (0.001,0) [1|1] "V"  BMS
 SG_ BMU8_Vol_3 : 39|16@0+ (0.001,0) [1|1] "V"  BMS
 SG_ BMU8_Vol_4 : 55|16@0+ (0.001,0) [1|1] "V"  BMS

BO_ 2281766920 BMU8_Vol_5: 8 BMU
 SG_ BMU8_Vol_5 : 7|16@0+ (0.001,0) [1|1] "V"  BMS
 SG_ BMU8_Vol_6 : 23|16@0+ (0.001,0) [1|1] "V"  BMS
 SG_ BMU8_Vol_7 : 39|16@0+ (0.001,0) [1|1] "V"  BMS
 SG_ BMU8_Vol_8 : 55|16@0+ (0.001,0) [1|1] "V"  BMS

BO_ 2281832456 BMU8_Vol_9: 8 BMU
 SG_ BMU8_Vol_9 : 7|16@0+ (0.001,0) [1|1] "V"  BMS
 SG_ BMU8_Vol_10 : 23|16@0+ (0.001,0) [1|1] "V"  BMS
 SG_ BMU8_Vol_11 : 39|16@0+ (0.001,0) [1|1] "V"  BMS
 SG_ BMU8_Vol_12 : 55|16@0+ (0.001,0) [1|1] "V"  BMS

BO_ 2281897992 BMU8_Vol_13: 8 BMU
 SG_ BMU8_Vol_13 : 7|16@0+ (0.001,0) [1|1] "V"  BMS
 SG_ BMU8_Vol_14 : 23|16@0+ (0.001,0) [1|1] "V"  BMS
 SG_ BMU8_Vol_15 : 39|16@0+ (0.001,0) [1|1] "V"  BMS
 SG_ BMU8_Vol_16 : 55|16@0+ (0.001,0) [1|1] "V"  BMS

BO_ 2281963528 BMU8_Vol_17: 8 BMU
 SG_ BMU8_Vol_17 : 7|16@0+ (0.001,0) [1|1] "V"  BMS
 SG_ BMU8_Vol_18 : 23|16@0+ (0.001,0) [1|1] "V"  BMS
 SG_ BMU8_Vol_19 : 39|16@0+ (0.001,0) [1|1] "V"  BMS
 SG_ BMU8_Vol_20 : 55|16@0+ (0.001,0) [1|1] "V"  BMS

BO_ 2282029064 BMU8_Vol_21: 8 BMU
 SG_ BMU8_Vol_21 : 7|16@0+ (0.001,0) [1|1] "V"  BMS
 SG_ BMU8_Vol_22 : 23|16@0+ (0.001,0) [1|1] "V"  BMS
 SG_ BMU8_Vol_23 : 39|16@0+ (0.001,0) [1|1] "V"  BMS
 SG_ BMU8_Vol_24 : 55|16@0+ (0.001,0) [1|1] "V"  BMS

BO_ 2282094600 BMU8_Vol_25: 8 BMU
 SG_ BMU8_Vol_25 : 7|16@0+ (0.001,0) [1|1] "V"  BMS
 SG_ BMU8_Vol_26 : 23|16@0+ (0.001,0) [1|1] "V"  BMS
 SG_ BMU8_Vol_27 : 39|16@0+ (0.001,0) [1|1] "V"  BMS
 SG_ BMU8_Vol_28 : 55|16@0+ (0.001,0) [1|1] "V"  BMS

BO_ 2282160136 BMU8_Vol_29: 8 BMU
 SG_ BMU8_Vol_29 : 7|16@0+ (0.001,0) [1|1] "V"  BMS
 SG_ BMU8_Vol_30 : 23|16@0+ (0.001,0) [1|1] "V"  BMS
 SG_ BMU8_Vol_31 : 39|16@0+ (0.001,0) [1|1] "V"  BMS
 SG_ BMU8_Vol_32 : 55|16@0+ (0.001,0) [1|1] "V"  BMS

BO_ 2282225672 BMU8_Vol_33: 8 BMU
 SG_ BMU8_Vol_33 : 7|16@0+ (0.001,0) [1|1] "V"  BMS
 SG_ BMU8_Vol_34 : 23|16@0+ (0.001,0) [1|1] "V"  BMS
 SG_ BMU8_Vol_35 : 39|16@0+ (0.001,0) [1|1] "V"  BMS
 SG_ BMU8_Vol_36 : 55|16@0+ (0.001,0) [1|1] "V"  BMS

BO_ 2282291208 BMU8_Vol_37: 8 BMU
 SG_ BMU8_Vol_37 : 7|16@0+ (0.001,0) [1|1] "V"  BMS
 SG_ BMU8_Vol_38 : 23|16@0+ (0.001,0) [1|1] "V"  BMS
 SG_ BMU8_Vol_39 : 39|16@0+ (0.001,0) [1|1] "V"  BMS
 SG_ BMU8_Vol_40 : 55|16@0+ (0.001,0) [1|1] "V"  BMS

BO_ 2282356744 BMU8_Vol_41: 8 BMU
 SG_ BMU8_Vol_41 : 7|16@0+ (0.001,0) [1|1] "V"  BMS
 SG_ BMU8_Vol_42 : 23|16@0+ (0.001,0) [1|1] "V"  BMS
 SG_ BMU8_Vol_43 : 39|16@0+ (0.001,0) [1|1] "V"  BMS
 SG_ BMU8_Vol_44 : 55|16@0+ (0.001,0) [1|1] "V"  BMS

BO_ 2282422280 BMU8_Vol_45: 8 BMU
 SG_ BMU8_Vol_45 : 7|16@0+ (0.001,0) [1|1] "V"  BMS
 SG_ BMU8_Vol_46 : 23|16@0+ (0.001,0) [1|1] "V"  BMS
 SG_ BMU8_Vol_47 : 39|16@0+ (0.001,0) [1|1] "V"  BMS
 SG_ BMU8_Vol_48 : 55|16@0+ (0.001,0) [1|1] "V"  BMS

BO_ 2282487816 BMU8_Vol_49: 8 BMU
 SG_ BMU8_Vol_49 : 7|16@0+ (0.001,0) [1|1] "V"  BMS
 SG_ BMU8_Vol_50 : 23|16@0+ (0.001,0) [1|1] "V"  BMS
 SG_ BMU8_Vol_51 : 39|16@0+ (0.001,0) [1|1] "V"  BMS
 SG_ BMU8_Vol_52 : 55|16@0+ (0.001,0) [1|1] "V"  BMS

BO_ 2282553352 BMU8_Vol_53: 8 BMU
 SG_ BMU8_Vol_53 : 7|16@0+ (0.001,0) [1|1] "V"  BMS
 SG_ BMU8_Vol_54 : 23|16@0+ (0.001,0) [1|1] "V"  BMS
 SG_ BMU8_Vol_55 : 39|16@0+ (0.001,0) [1|1] "V"  BMS
 SG_ BMU8_Vol_56 : 55|16@0+ (0.001,0) [1|1] "V"  BMS

BO_ 2282618888 BMU8_Vol_57: 8 BMU
 SG_ BMU8_Vol_57 : 7|16@0+ (0.001,0) [1|1] "V"  BMS
 SG_ BMU8_Vol_58 : 23|16@0+ (0.001,0) [1|1] "V"  BMS
 SG_ BMU8_Vol_59 : 39|16@0+ (0.001,0) [1|1] "V"  BMS
 SG_ BMU8_Vol_60 : 55|16@0+ (0.001,0) [1|1] "V"  BMS

BO_ 2282684424 BMU8_Vol_61: 8 BMU
 SG_ BMU8_Vol_61 : 7|16@0+ (0.001,0) [1|1] "V"  BMS
 SG_ BMU8_Vol_62 : 23|16@0+ (0.001,0) [1|1] "V"  BMS
 SG_ BMU8_Vol_63 : 39|16@0+ (0.001,0) [1|1] "V"  BMS
 SG_ BMU8_Vol_64 : 55|16@0+ (0.001,0) [1|1] "V"  BMS

BO_ 2282749960 BMU8_Vol_65: 8 BMU
 SG_ BMU8_Vol_65 : 7|16@0+ (0.001,0) [1|1] "V"  BMS
 SG_ BMU8_Vol_66 : 23|16@0+ (0.001,0) [1|1] "V"  BMS
 SG_ BMU8_Vol_67 : 39|16@0+ (0.001,0) [1|1] "V"  BMS
 SG_ BMU8_Vol_68 : 55|16@0+ (0.001,0) [1|1] "V"  BMS

BO_ 2282815496 BMU8_Vol_69: 8 BMU
 SG_ BMU8_Vol_69 : 7|16@0+ (0.001,0) [1|1] "V"  BMS
 SG_ BMU8_Vol_70 : 23|16@0+ (0.001,0) [1|1] "V"  BMS
 SG_ BMU8_Vol_71 : 39|16@0+ (0.001,0) [1|1] "V"  BMS
 SG_ BMU8_Vol_72 : 55|16@0+ (0.001,0) [1|1] "V"  BMS

BO_ 2282881032 BMU8_Vol_73: 8 BMU
 SG_ BMU8_Vol_73 : 7|16@0+ (0.001,0) [1|1] "V"  BMS
 SG_ BMU8_Vol_74 : 23|16@0+ (0.001,0) [1|1] "V"  BMS
 SG_ BMU8_Vol_75 : 39|16@0+ (0.001,0) [1|1] "V"  BMS
 SG_ BMU8_Vol_76 : 55|16@0+ (0.001,0) [1|1] "V"  BMS

BO_ 2282946568 BMU8_Vol_77: 8 BMU
 SG_ BMU8_Vol_77 : 7|16@0+ (0.001,0) [1|1] "V"  BMS
 SG_ BMU8_Vol_78 : 23|16@0+ (0.001,0) [1|1] "V"  BMS
 SG_ BMU8_Vol_79 : 39|16@0+ (0.001,0) [1|1] "V"  BMS
 SG_ BMU8_Vol_80 : 55|16@0+ (0.001,0) [1|1] "V"  BMS

BO_ 2283012104 BMU8_Vol_81: 8 BMU
 SG_ BMU8_Vol_81 : 7|16@0+ (0.001,0) [1|1] "V"  BMS
 SG_ BMU8_Vol_82 : 23|16@0+ (0.001,0) [1|1] "V"  BMS
 SG_ BMU8_Vol_83 : 39|16@0+ (0.001,0) [1|1] "V"  BMS
 SG_ BMU8_Vol_84 : 55|16@0+ (0.001,0) [1|1] "V"  BMS

BO_ 2283077640 BMU8_Vol_85: 8 BMU
 SG_ BMU8_Vol_85 : 7|16@0+ (0.001,0) [1|1] "V"  BMS
 SG_ BMU8_Vol_86 : 23|16@0+ (0.001,0) [1|1] "V"  BMS
 SG_ BMU8_Vol_87 : 39|16@0+ (0.001,0) [1|1] "V"  BMS
 SG_ BMU8_Vol_88 : 55|16@0+ (0.001,0) [1|1] "V"  BMS

BO_ 2283143176 BMU8_Vol_89: 8 BMU
 SG_ BMU8_Vol_89 : 7|16@0+ (0.001,0) [1|1] "V"  BMS
 SG_ BMU8_Vol_90 : 23|16@0+ (0.001,0) [1|1] "V"  BMS
 SG_ BMU8_Vol_91 : 39|16@0+ (0.001,0) [1|1] "V"  BMS
 SG_ BMU8_Vol_92 : 55|16@0+ (0.001,0) [1|1] "V"  BMS

BO_ 2283208712 BMU8_Vol_93: 8 BMU
 SG_ BMU8_Vol_93 : 7|16@0+ (0.001,0) [1|1] "V"  BMS
 SG_ BMU8_Vol_94 : 23|16@0+ (0.001,0) [1|1] "V"  BMS
 SG_ BMU8_Vol_95 : 39|16@0+ (0.001,0) [1|1] "V"  BMS
 SG_ BMU8_Vol_96 : 55|16@0+ (0.001,0) [1|1] "V"  BMS

BO_ 2281701385 BMU9_Vol_1: 8 BMU
 SG_ BMU9_Vol_1 : 7|16@0+ (0.001,0) [1|1] "V"  BMS
 SG_ BMU9_Vol_2 : 23|16@0+ (0.001,0) [1|1] "V"  BMS
 SG_ BMU9_Vol_3 : 39|16@0+ (0.001,0) [1|1] "V"  BMS
 SG_ BMU9_Vol_4 : 55|16@0+ (0.001,0) [1|1] "V"  BMS

BO_ 2281766921 BMU9_Vol_5: 8 BMU
 SG_ BMU9_Vol_5 : 7|16@0+ (0.001,0) [1|1] "V"  BMS
 SG_ BMU9_Vol_6 : 23|16@0+ (0.001,0) [1|1] "V"  BMS
 SG_ BMU9_Vol_7 : 39|16@0+ (0.001,0) [1|1] "V"  BMS
 SG_ BMU9_Vol_8 : 55|16@0+ (0.001,0) [1|1] "V"  BMS

BO_ 2281832457 BMU9_Vol_9: 8 BMU
 SG_ BMU9_Vol_9 : 7|16@0+ (0.001,0) [1|1] "V"  BMS
 SG_ BMU9_Vol_10 : 23|16@0+ (0.001,0) [1|1] "V"  BMS
 SG_ BMU9_Vol_11 : 39|16@0+ (0.001,0) [1|1] "V"  BMS
 SG_ BMU9_Vol_12 : 55|16@0+ (0.001,0) [1|1] "V"  BMS

BO_ 2281897993 BMU9_Vol_13: 8 BMU
 SG_ BMU9_Vol_13 : 7|16@0+ (0.001,0) [1|1] "V"  BMS
 SG_ BMU9_Vol_14 : 23|16@0+ (0.001,0) [1|1] "V"  BMS
 SG_ BMU9_Vol_15 : 39|16@0+ (0.001,0) [1|1] "V"  BMS
 SG_ BMU9_Vol_16 : 55|16@0+ (0.001,0) [1|1] "V"  BMS

BO_ 2281963529 BMU9_Vol_17: 8 BMU
 SG_ BMU9_Vol_17 : 7|16@0+ (0.001,0) [1|1] "V"  BMS
 SG_ BMU9_Vol_18 : 23|16@0+ (0.001,0) [1|1] "V"  BMS
 SG_ BMU9_Vol_19 : 39|16@0+ (0.001,0) [1|1] "V"  BMS
 SG_ BMU9_Vol_20 : 55|16@0+ (0.001,0) [1|1] "V"  BMS

BO_ 2282029065 BMU9_Vol_21: 8 BMU
 SG_ BMU9_Vol_21 : 7|16@0+ (0.001,0) [1|1] "V"  BMS
 SG_ BMU9_Vol_22 : 23|16@0+ (0.001,0) [1|1] "V"  BMS
 SG_ BMU9_Vol_23 : 39|16@0+ (0.001,0) [1|1] "V"  BMS
 SG_ BMU9_Vol_24 : 55|16@0+ (0.001,0) [1|1] "V"  BMS

BO_ 2282094601 BMU9_Vol_25: 8 BMU
 SG_ BMU9_Vol_25 : 7|16@0+ (0.001,0) [1|1] "V"  BMS
 SG_ BMU9_Vol_26 : 23|16@0+ (0.001,0) [1|1] "V"  BMS
 SG_ BMU9_Vol_27 : 39|16@0+ (0.001,0) [1|1] "V"  BMS
 SG_ BMU9_Vol_28 : 55|16@0+ (0.001,0) [1|1] "V"  BMS

BO_ 2282160137 BMU9_Vol_29: 8 BMU
 SG_ BMU9_Vol_29 : 7|16@0+ (0.001,0) [1|1] "V"  BMS
 SG_ BMU9_Vol_30 : 23|16@0+ (0.001,0) [1|1] "V"  BMS
 SG_ BMU9_Vol_31 : 39|16@0+ (0.001,0) [1|1] "V"  BMS
 SG_ BMU9_Vol_32 : 55|16@0+ (0.001,0) [1|1] "V"  BMS

BO_ 2282225673 BMU9_Vol_33: 8 BMU
 SG_ BMU9_Vol_33 : 7|16@0+ (0.001,0) [1|1] "V"  BMS
 SG_ BMU9_Vol_34 : 23|16@0+ (0.001,0) [1|1] "V"  BMS
 SG_ BMU9_Vol_35 : 39|16@0+ (0.001,0) [1|1] "V"  BMS
 SG_ BMU9_Vol_36 : 55|16@0+ (0.001,0) [1|1] "V"  BMS

BO_ 2282291209 BMU9_Vol_37: 8 BMU
 SG_ BMU9_Vol_37 : 7|16@0+ (0.001,0) [1|1] "V"  BMS
 SG_ BMU9_Vol_38 : 23|16@0+ (0.001,0) [1|1] "V"  BMS
 SG_ BMU9_Vol_39 : 39|16@0+ (0.001,0) [1|1] "V"  BMS
 SG_ BMU9_Vol_40 : 55|16@0+ (0.001,0) [1|1] "V"  BMS

BO_ 2282356745 BMU9_Vol_41: 8 BMU
 SG_ BMU9_Vol_41 : 7|16@0+ (0.001,0) [1|1] "V"  BMS
 SG_ BMU9_Vol_42 : 23|16@0+ (0.001,0) [1|1] "V"  BMS
 SG_ BMU9_Vol_43 : 39|16@0+ (0.001,0) [1|1] "V"  BMS
 SG_ BMU9_Vol_44 : 55|16@0+ (0.001,0) [1|1] "V"  BMS

BO_ 2282422281 BMU9_Vol_45: 8 BMU
 SG_ BMU9_Vol_45 : 7|16@0+ (0.001,0) [1|1] "V"  BMS
 SG_ BMU9_Vol_46 : 23|16@0+ (0.001,0) [1|1] "V"  BMS
 SG_ BMU9_Vol_47 : 39|16@0+ (0.001,0) [1|1] "V"  BMS
 SG_ BMU9_Vol_48 : 55|16@0+ (0.001,0) [1|1] "V"  BMS

BO_ 2282487817 BMU9_Vol_49: 8 BMU
 SG_ BMU9_Vol_49 : 7|16@0+ (0.001,0) [1|1] "V"  BMS
 SG_ BMU9_Vol_50 : 23|16@0+ (0.001,0) [1|1] "V"  BMS
 SG_ BMU9_Vol_51 : 39|16@0+ (0.001,0) [1|1] "V"  BMS
 SG_ BMU9_Vol_52 : 55|16@0+ (0.001,0) [1|1] "V"  BMS

BO_ 2282553353 BMU9_Vol_53: 8 BMU
 SG_ BMU9_Vol_53 : 7|16@0+ (0.001,0) [1|1] "V"  BMS
 SG_ BMU9_Vol_54 : 23|16@0+ (0.001,0) [1|1] "V"  BMS
 SG_ BMU9_Vol_55 : 39|16@0+ (0.001,0) [1|1] "V"  BMS
 SG_ BMU9_Vol_56 : 55|16@0+ (0.001,0) [1|1] "V"  BMS

BO_ 2282618889 BMU9_Vol_57: 8 BMU
 SG_ BMU9_Vol_57 : 7|16@0+ (0.001,0) [1|1] "V"  BMS
 SG_ BMU9_Vol_58 : 23|16@0+ (0.001,0) [1|1] "V"  BMS
 SG_ BMU9_Vol_59 : 39|16@0+ (0.001,0) [1|1] "V"  BMS
 SG_ BMU9_Vol_60 : 55|16@0+ (0.001,0) [1|1] "V"  BMS

BO_ 2282684425 BMU9_Vol_61: 8 BMU
 SG_ BMU9_Vol_61 : 7|16@0+ (0.001,0) [1|1] "V"  BMS
 SG_ BMU9_Vol_62 : 23|16@0+ (0.001,0) [1|1] "V"  BMS
 SG_ BMU9_Vol_63 : 39|16@0+ (0.001,0) [1|1] "V"  BMS
 SG_ BMU9_Vol_64 : 55|16@0+ (0.001,0) [1|1] "V"  BMS

BO_ 2282749961 BMU9_Vol_65: 8 BMU
 SG_ BMU9_Vol_65 : 7|16@0+ (0.001,0) [1|1] "V"  BMS
 SG_ BMU9_Vol_66 : 23|16@0+ (0.001,0) [1|1] "V"  BMS
 SG_ BMU9_Vol_67 : 39|16@0+ (0.001,0) [1|1] "V"  BMS
 SG_ BMU9_Vol_68 : 55|16@0+ (0.001,0) [1|1] "V"  BMS

BO_ 2282815497 BMU9_Vol_69: 8 BMU
 SG_ BMU9_Vol_69 : 7|16@0+ (0.001,0) [1|1] "V"  BMS
 SG_ BMU9_Vol_70 : 23|16@0+ (0.001,0) [1|1] "V"  BMS
 SG_ BMU9_Vol_71 : 39|16@0+ (0.001,0) [1|1] "V"  BMS
 SG_ BMU9_Vol_72 : 55|16@0+ (0.001,0) [1|1] "V"  BMS

BO_ 2282881033 BMU9_Vol_73: 8 BMU
 SG_ BMU9_Vol_73 : 7|16@0+ (0.001,0) [1|1] "V"  BMS
 SG_ BMU9_Vol_74 : 23|16@0+ (0.001,0) [1|1] "V"  BMS
 SG_ BMU9_Vol_75 : 39|16@0+ (0.001,0) [1|1] "V"  BMS
 SG_ BMU9_Vol_76 : 55|16@0+ (0.001,0) [1|1] "V"  BMS

BO_ 2282946569 BMU9_Vol_77: 8 BMU
 SG_ BMU9_Vol_77 : 7|16@0+ (0.001,0) [1|1] "V"  BMS
 SG_ BMU9_Vol_78 : 23|16@0+ (0.001,0) [1|1] "V"  BMS
 SG_ BMU9_Vol_79 : 39|16@0+ (0.001,0) [1|1] "V"  BMS
 SG_ BMU9_Vol_80 : 55|16@0+ (0.001,0) [1|1] "V"  BMS

BO_ 2283012105 BMU9_Vol_81: 8 BMU
 SG_ BMU9_Vol_81 : 7|16@0+ (0.001,0) [1|1] "V"  BMS
 SG_ BMU9_Vol_82 : 23|16@0+ (0.001,0) [1|1] "V"  BMS
 SG_ BMU9_Vol_83 : 39|16@0+ (0.001,0) [1|1] "V"  BMS
 SG_ BMU9_Vol_84 : 55|16@0+ (0.001,0) [1|1] "V"  BMS

BO_ 2283077641 BMU9_Vol_85: 8 BMU
 SG_ BMU9_Vol_85 : 7|16@0+ (0.001,0) [1|1] "V"  BMS
 SG_ BMU9_Vol_86 : 23|16@0+ (0.001,0) [1|1] "V"  BMS
 SG_ BMU9_Vol_87 : 39|16@0+ (0.001,0) [1|1] "V"  BMS
 SG_ BMU9_Vol_88 : 55|16@0+ (0.001,0) [1|1] "V"  BMS

BO_ 2283143177 BMU9_Vol_89: 8 BMU
 SG_ BMU9_Vol_89 : 7|16@0+ (0.001,0) [1|1] "V"  BMS
 SG_ BMU9_Vol_90 : 23|16@0+ (0.001,0) [1|1] "V"  BMS
 SG_ BMU9_Vol_91 : 39|16@0+ (0.001,0) [1|1] "V"  BMS
 SG_ BMU9_Vol_92 : 55|16@0+ (0.001,0) [1|1] "V"  BMS

BO_ 2283208713 BMU9_Vol_93: 8 BMU
 SG_ BMU9_Vol_93 : 7|16@0+ (0.001,0) [1|1] "V"  BMS
 SG_ BMU9_Vol_94 : 23|16@0+ (0.001,0) [1|1] "V"  BMS
 SG_ BMU9_Vol_95 : 39|16@0+ (0.001,0) [1|1] "V"  BMS
 SG_ BMU9_Vol_96 : 55|16@0+ (0.001,0) [1|1] "V"  BMS

BO_ 2281701386 BMU10_Vol_1: 8 BMU
 SG_ BMU10_Vol_1 : 7|16@0+ (0.001,0) [1|1] "V"  BMS
 SG_ BMU10_Vol_2 : 23|16@0+ (0.001,0) [1|1] "V"  BMS
 SG_ BMU10_Vol_3 : 39|16@0+ (0.001,0) [1|1] "V"  BMS
 SG_ BMU10_Vol_4 : 55|16@0+ (0.001,0) [1|1] "V"  BMS

BO_ 2281766922 BMU10_Vol_5: 8 BMU
 SG_ BMU10_Vol_5 : 7|16@0+ (0.001,0) [1|1] "V"  BMS
 SG_ BMU10_Vol_6 : 23|16@0+ (0.001,0) [1|1] "V"  BMS
 SG_ BMU10_Vol_7 : 39|16@0+ (0.001,0) [1|1] "V"  BMS
 SG_ BMU10_Vol_8 : 55|16@0+ (0.001,0) [1|1] "V"  BMS

BO_ 2281832458 BMU10_Vol_9: 8 BMU
 SG_ BMU10_Vol_9 : 7|16@0+ (0.001,0) [1|1] "V"  BMS
 SG_ BMU10_Vol_10 : 23|16@0+ (0.001,0) [1|1] "V"  BMS
 SG_ BMU10_Vol_11 : 39|16@0+ (0.001,0) [1|1] "V"  BMS
 SG_ BMU10_Vol_12 : 55|16@0+ (0.001,0) [1|1] "V"  BMS

BO_ 2281897994 BMU10_Vol_13: 8 BMU
 SG_ BMU10_Vol_13 : 7|16@0+ (0.001,0) [1|1] "V"  BMS
 SG_ BMU10_Vol_14 : 23|16@0+ (0.001,0) [1|1] "V"  BMS
 SG_ BMU10_Vol_15 : 39|16@0+ (0.001,0) [1|1] "V"  BMS
 SG_ BMU10_Vol_16 : 55|16@0+ (0.001,0) [1|1] "V"  BMS

BO_ 2281963530 BMU10_Vol_17: 8 BMU
 SG_ BMU10_Vol_17 : 7|16@0+ (0.001,0) [1|1] "V"  BMS
 SG_ BMU10_Vol_18 : 23|16@0+ (0.001,0) [1|1] "V"  BMS
 SG_ BMU10_Vol_19 : 39|16@0+ (0.001,0) [1|1] "V"  BMS
 SG_ BMU10_Vol_20 : 55|16@0+ (0.001,0) [1|1] "V"  BMS

BO_ 2282029066 BMU10_Vol_21: 8 BMU
 SG_ BMU10_Vol_21 : 7|16@0+ (0.001,0) [1|1] "V"  BMS
 SG_ BMU10_Vol_22 : 23|16@0+ (0.001,0) [1|1] "V"  BMS
 SG_ BMU10_Vol_23 : 39|16@0+ (0.001,0) [1|1] "V"  BMS
 SG_ BMU10_Vol_24 : 55|16@0+ (0.001,0) [1|1] "V"  BMS

BO_ 2282094602 BMU10_Vol_25: 8 BMU
 SG_ BMU10_Vol_25 : 7|16@0+ (0.001,0) [1|1] "V"  BMS
 SG_ BMU10_Vol_26 : 23|16@0+ (0.001,0) [1|1] "V"  BMS
 SG_ BMU10_Vol_27 : 39|16@0+ (0.001,0) [1|1] "V"  BMS
 SG_ BMU10_Vol_28 : 55|16@0+ (0.001,0) [1|1] "V"  BMS

BO_ 2282160138 BMU10_Vol_29: 8 BMU
 SG_ BMU10_Vol_29 : 7|16@0+ (0.001,0) [1|1] "V"  BMS
 SG_ BMU10_Vol_30 : 23|16@0+ (0.001,0) [1|1] "V"  BMS
 SG_ BMU10_Vol_31 : 39|16@0+ (0.001,0) [1|1] "V"  BMS
 SG_ BMU10_Vol_32 : 55|16@0+ (0.001,0) [1|1] "V"  BMS

BO_ 2282225674 BMU10_Vol_33: 8 BMU
 SG_ BMU10_Vol_33 : 7|16@0+ (0.001,0) [1|1] "V"  BMS
 SG_ BMU10_Vol_34 : 23|16@0+ (0.001,0) [1|1] "V"  BMS
 SG_ BMU10_Vol_35 : 39|16@0+ (0.001,0) [1|1] "V"  BMS
 SG_ BMU10_Vol_36 : 55|16@0+ (0.001,0) [1|1] "V"  BMS

BO_ 2282291210 BMU10_Vol_37: 8 BMU
 SG_ BMU10_Vol_37 : 7|16@0+ (0.001,0) [1|1] "V"  BMS
 SG_ BMU10_Vol_38 : 23|16@0+ (0.001,0) [1|1] "V"  BMS
 SG_ BMU10_Vol_39 : 39|16@0+ (0.001,0) [1|1] "V"  BMS
 SG_ BMU10_Vol_40 : 55|16@0+ (0.001,0) [1|1] "V"  BMS

BO_ 2282356746 BMU10_Vol_41: 8 BMU
 SG_ BMU10_Vol_41 : 7|16@0+ (0.001,0) [1|1] "V"  BMS
 SG_ BMU10_Vol_42 : 23|16@0+ (0.001,0) [1|1] "V"  BMS
 SG_ BMU10_Vol_43 : 39|16@0+ (0.001,0) [1|1] "V"  BMS
 SG_ BMU10_Vol_44 : 55|16@0+ (0.001,0) [1|1] "V"  BMS

BO_ 2282422282 BMU10_Vol_45: 8 BMU
 SG_ BMU10_Vol_45 : 7|16@0+ (0.001,0) [1|1] "V"  BMS
 SG_ BMU10_Vol_46 : 23|16@0+ (0.001,0) [1|1] "V"  BMS
 SG_ BMU10_Vol_47 : 39|16@0+ (0.001,0) [1|1] "V"  BMS
 SG_ BMU10_Vol_48 : 55|16@0+ (0.001,0) [1|1] "V"  BMS

BO_ 2282487818 BMU10_Vol_49: 8 BMU
 SG_ BMU10_Vol_49 : 7|16@0+ (0.001,0) [1|1] "V"  BMS
 SG_ BMU10_Vol_50 : 23|16@0+ (0.001,0) [1|1] "V"  BMS
 SG_ BMU10_Vol_51 : 39|16@0+ (0.001,0) [1|1] "V"  BMS
 SG_ BMU10_Vol_52 : 55|16@0+ (0.001,0) [1|1] "V"  BMS

BO_ 2282553354 BMU10_Vol_53: 8 BMU
 SG_ BMU10_Vol_53 : 7|16@0+ (0.001,0) [1|1] "V"  BMS
 SG_ BMU10_Vol_54 : 23|16@0+ (0.001,0) [1|1] "V"  BMS
 SG_ BMU10_Vol_55 : 39|16@0+ (0.001,0) [1|1] "V"  BMS
 SG_ BMU10_Vol_56 : 55|16@0+ (0.001,0) [1|1] "V"  BMS

BO_ 2282618890 BMU10_Vol_57: 8 BMU
 SG_ BMU10_Vol_57 : 7|16@0+ (0.001,0) [1|1] "V"  BMS
 SG_ BMU10_Vol_58 : 23|16@0+ (0.001,0) [1|1] "V"  BMS
 SG_ BMU10_Vol_59 : 39|16@0+ (0.001,0) [1|1] "V"  BMS
 SG_ BMU10_Vol_60 : 55|16@0+ (0.001,0) [1|1] "V"  BMS

BO_ 2282684426 BMU10_Vol_61: 8 BMU
 SG_ BMU10_Vol_61 : 7|16@0+ (0.001,0) [1|1] "V"  BMS
 SG_ BMU10_Vol_62 : 23|16@0+ (0.001,0) [1|1] "V"  BMS
 SG_ BMU10_Vol_63 : 39|16@0+ (0.001,0) [1|1] "V"  BMS
 SG_ BMU10_Vol_64 : 55|16@0+ (0.001,0) [1|1] "V"  BMS

BO_ 2282749962 BMU10_Vol_65: 8 BMU
 SG_ BMU10_Vol_65 : 7|16@0+ (0.001,0) [1|1] "V"  BMS
 SG_ BMU10_Vol_66 : 23|16@0+ (0.001,0) [1|1] "V"  BMS
 SG_ BMU10_Vol_67 : 39|16@0+ (0.001,0) [1|1] "V"  BMS
 SG_ BMU10_Vol_68 : 55|16@0+ (0.001,0) [1|1] "V"  BMS

BO_ 2282815498 BMU10_Vol_69: 8 BMU
 SG_ BMU10_Vol_69 : 7|16@0+ (0.001,0) [1|1] "V"  BMS
 SG_ BMU10_Vol_70 : 23|16@0+ (0.001,0) [1|1] "V"  BMS
 SG_ BMU10_Vol_71 : 39|16@0+ (0.001,0) [1|1] "V"  BMS
 SG_ BMU10_Vol_72 : 55|16@0+ (0.001,0) [1|1] "V"  BMS

BO_ 2282881034 BMU10_Vol_73: 8 BMU
 SG_ BMU10_Vol_73 : 7|16@0+ (0.001,0) [1|1] "V"  BMS
 SG_ BMU10_Vol_74 : 23|16@0+ (0.001,0) [1|1] "V"  BMS
 SG_ BMU10_Vol_75 : 39|16@0+ (0.001,0) [1|1] "V"  BMS
 SG_ BMU10_Vol_76 : 55|16@0+ (0.001,0) [1|1] "V"  BMS

BO_ 2282946570 BMU10_Vol_77: 8 BMU
 SG_ BMU10_Vol_77 : 7|16@0+ (0.001,0) [1|1] "V"  BMS
 SG_ BMU10_Vol_78 : 23|16@0+ (0.001,0) [1|1] "V"  BMS
 SG_ BMU10_Vol_79 : 39|16@0+ (0.001,0) [1|1] "V"  BMS
 SG_ BMU10_Vol_80 : 55|16@0+ (0.001,0) [1|1] "V"  BMS

BO_ 2283012106 BMU10_Vol_81: 8 BMU
 SG_ BMU10_Vol_81 : 7|16@0+ (0.001,0) [1|1] "V"  BMS
 SG_ BMU10_Vol_82 : 23|16@0+ (0.001,0) [1|1] "V"  BMS
 SG_ BMU10_Vol_83 : 39|16@0+ (0.001,0) [1|1] "V"  BMS
 SG_ BMU10_Vol_84 : 55|16@0+ (0.001,0) [1|1] "V"  BMS

BO_ 2283077642 BMU10_Vol_85: 8 BMU
 SG_ BMU10_Vol_85 : 7|16@0+ (0.001,0) [1|1] "V"  BMS
 SG_ BMU10_Vol_86 : 23|16@0+ (0.001,0) [1|1] "V"  BMS
 SG_ BMU10_Vol_87 : 39|16@0+ (0.001,0) [1|1] "V"  BMS
 SG_ BMU10_Vol_88 : 55|16@0+ (0.001,0) [1|1] "V"  BMS

BO_ 2283143178 BMU10_Vol_89: 8 BMU
 SG_ BMU10_Vol_89 : 7|16@0+ (0.001,0) [1|1] "V"  BMS
 SG_ BMU10_Vol_90 : 23|16@0+ (0.001,0) [1|1] "V"  BMS
 SG_ BMU10_Vol_91 : 39|16@0+ (0.001,0) [1|1] "V"  BMS
 SG_ BMU10_Vol_92 : 55|16@0+ (0.001,0) [1|1] "V"  BMS

BO_ 2283208714 BMU10_Vol_93: 8 BMU
 SG_ BMU10_Vol_93 : 7|16@0+ (0.001,0) [1|1] "V"  BMS
 SG_ BMU10_Vol_94 : 23|16@0+ (0.001,0) [1|1] "V"  BMS
 SG_ BMU10_Vol_95 : 39|16@0+ (0.001,0) [1|1] "V"  BMS
 SG_ BMU10_Vol_96 : 55|16@0+ (0.001,0) [1|1] "V"  BMS

BO_ 2281701387 BMU11_Vol_1: 8 BMU
 SG_ BMU11_Vol_1 : 7|16@0+ (0.001,0) [1|1] "V"  BMS
 SG_ BMU11_Vol_2 : 23|16@0+ (0.001,0) [1|1] "V"  BMS
 SG_ BMU11_Vol_3 : 39|16@0+ (0.001,0) [1|1] "V"  BMS
 SG_ BMU11_Vol_4 : 55|16@0+ (0.001,0) [1|1] "V"  BMS

BO_ 2281766923 BMU11_Vol_5: 8 BMU
 SG_ BMU11_Vol_5 : 7|16@0+ (0.001,0) [1|1] "V"  BMS
 SG_ BMU11_Vol_6 : 23|16@0+ (0.001,0) [1|1] "V"  BMS
 SG_ BMU11_Vol_7 : 39|16@0+ (0.001,0) [1|1] "V"  BMS
 SG_ BMU11_Vol_8 : 55|16@0+ (0.001,0) [1|1] "V"  BMS

BO_ 2281832459 BMU11_Vol_9: 8 BMU
 SG_ BMU11_Vol_9 : 7|16@0+ (0.001,0) [1|1] "V"  BMS
 SG_ BMU11_Vol_10 : 23|16@0+ (0.001,0) [1|1] "V"  BMS
 SG_ BMU11_Vol_11 : 39|16@0+ (0.001,0) [1|1] "V"  BMS
 SG_ BMU11_Vol_12 : 55|16@0+ (0.001,0) [1|1] "V"  BMS

BO_ 2281897995 BMU11_Vol_13: 8 BMU
 SG_ BMU11_Vol_13 : 7|16@0+ (0.001,0) [1|1] "V"  BMS
 SG_ BMU11_Vol_14 : 23|16@0+ (0.001,0) [1|1] "V"  BMS
 SG_ BMU11_Vol_15 : 39|16@0+ (0.001,0) [1|1] "V"  BMS
 SG_ BMU11_Vol_16 : 55|16@0+ (0.001,0) [1|1] "V"  BMS

BO_ 2281963531 BMU11_Vol_17: 8 BMU
 SG_ BMU11_Vol_17 : 7|16@0+ (0.001,0) [1|1] "V"  BMS
 SG_ BMU11_Vol_18 : 23|16@0+ (0.001,0) [1|1] "V"  BMS
 SG_ BMU11_Vol_19 : 39|16@0+ (0.001,0) [1|1] "V"  BMS
 SG_ BMU11_Vol_20 : 55|16@0+ (0.001,0) [1|1] "V"  BMS

BO_ 2282029067 BMU11_Vol_21: 8 BMU
 SG_ BMU11_Vol_21 : 7|16@0+ (0.001,0) [1|1] "V"  BMS
 SG_ BMU11_Vol_22 : 23|16@0+ (0.001,0) [1|1] "V"  BMS
 SG_ BMU11_Vol_23 : 39|16@0+ (0.001,0) [1|1] "V"  BMS
 SG_ BMU11_Vol_24 : 55|16@0+ (0.001,0) [1|1] "V"  BMS

BO_ 2282094603 BMU11_Vol_25: 8 BMU
 SG_ BMU11_Vol_25 : 7|16@0+ (0.001,0) [1|1] "V"  BMS
 SG_ BMU11_Vol_26 : 23|16@0+ (0.001,0) [1|1] "V"  BMS
 SG_ BMU11_Vol_27 : 39|16@0+ (0.001,0) [1|1] "V"  BMS
 SG_ BMU11_Vol_28 : 55|16@0+ (0.001,0) [1|1] "V"  BMS

BO_ 2282160139 BMU11_Vol_29: 8 BMU
 SG_ BMU11_Vol_29 : 7|16@0+ (0.001,0) [1|1] "V"  BMS
 SG_ BMU11_Vol_30 : 23|16@0+ (0.001,0) [1|1] "V"  BMS
 SG_ BMU11_Vol_31 : 39|16@0+ (0.001,0) [1|1] "V"  BMS
 SG_ BMU11_Vol_32 : 55|16@0+ (0.001,0) [1|1] "V"  BMS

BO_ 2282225675 BMU11_Vol_33: 8 BMU
 SG_ BMU11_Vol_33 : 7|16@0+ (0.001,0) [1|1] "V"  BMS
 SG_ BMU11_Vol_34 : 23|16@0+ (0.001,0) [1|1] "V"  BMS
 SG_ BMU11_Vol_35 : 39|16@0+ (0.001,0) [1|1] "V"  BMS
 SG_ BMU11_Vol_36 : 55|16@0+ (0.001,0) [1|1] "V"  BMS

BO_ 2282291211 BMU11_Vol_37: 8 BMU
 SG_ BMU11_Vol_37 : 7|16@0+ (0.001,0) [1|1] "V"  BMS
 SG_ BMU11_Vol_38 : 23|16@0+ (0.001,0) [1|1] "V"  BMS
 SG_ BMU11_Vol_39 : 39|16@0+ (0.001,0) [1|1] "V"  BMS
 SG_ BMU11_Vol_40 : 55|16@0+ (0.001,0) [1|1] "V"  BMS

BO_ 2282356747 BMU11_Vol_41: 8 BMU
 SG_ BMU11_Vol_41 : 7|16@0+ (0.001,0) [1|1] "V"  BMS
 SG_ BMU11_Vol_42 : 23|16@0+ (0.001,0) [1|1] "V"  BMS
 SG_ BMU11_Vol_43 : 39|16@0+ (0.001,0) [1|1] "V"  BMS
 SG_ BMU11_Vol_44 : 55|16@0+ (0.001,0) [1|1] "V"  BMS

BO_ 2282422283 BMU11_Vol_45: 8 BMU
 SG_ BMU11_Vol_45 : 7|16@0+ (0.001,0) [1|1] "V"  BMS
 SG_ BMU11_Vol_46 : 23|16@0+ (0.001,0) [1|1] "V"  BMS
 SG_ BMU11_Vol_47 : 39|16@0+ (0.001,0) [1|1] "V"  BMS
 SG_ BMU11_Vol_48 : 55|16@0+ (0.001,0) [1|1] "V"  BMS

BO_ 2282487819 BMU11_Vol_49: 8 BMU
 SG_ BMU11_Vol_49 : 7|16@0+ (0.001,0) [1|1] "V"  BMS
 SG_ BMU11_Vol_50 : 23|16@0+ (0.001,0) [1|1] "V"  BMS
 SG_ BMU11_Vol_51 : 39|16@0+ (0.001,0) [1|1] "V"  BMS
 SG_ BMU11_Vol_52 : 55|16@0+ (0.001,0) [1|1] "V"  BMS

BO_ 2282553355 BMU11_Vol_53: 8 BMU
 SG_ BMU11_Vol_53 : 7|16@0+ (0.001,0) [1|1] "V"  BMS
 SG_ BMU11_Vol_54 : 23|16@0+ (0.001,0) [1|1] "V"  BMS
 SG_ BMU11_Vol_55 : 39|16@0+ (0.001,0) [1|1] "V"  BMS
 SG_ BMU11_Vol_56 : 55|16@0+ (0.001,0) [1|1] "V"  BMS

BO_ 2282618891 BMU11_Vol_57: 8 BMU
 SG_ BMU11_Vol_57 : 7|16@0+ (0.001,0) [1|1] "V"  BMS
 SG_ BMU11_Vol_58 : 23|16@0+ (0.001,0) [1|1] "V"  BMS
 SG_ BMU11_Vol_59 : 39|16@0+ (0.001,0) [1|1] "V"  BMS
 SG_ BMU11_Vol_60 : 55|16@0+ (0.001,0) [1|1] "V"  BMS

BO_ 2282684427 BMU11_Vol_61: 8 BMU
 SG_ BMU11_Vol_61 : 7|16@0+ (0.001,0) [1|1] "V"  BMS
 SG_ BMU11_Vol_62 : 23|16@0+ (0.001,0) [1|1] "V"  BMS
 SG_ BMU11_Vol_63 : 39|16@0+ (0.001,0) [1|1] "V"  BMS
 SG_ BMU11_Vol_64 : 55|16@0+ (0.001,0) [1|1] "V"  BMS

BO_ 2282749963 BMU11_Vol_65: 8 BMU
 SG_ BMU11_Vol_65 : 7|16@0+ (0.001,0) [1|1] "V"  BMS
 SG_ BMU11_Vol_66 : 23|16@0+ (0.001,0) [1|1] "V"  BMS
 SG_ BMU11_Vol_67 : 39|16@0+ (0.001,0) [1|1] "V"  BMS
 SG_ BMU11_Vol_68 : 55|16@0+ (0.001,0) [1|1] "V"  BMS

BO_ 2282815499 BMU11_Vol_69: 8 BMU
 SG_ BMU11_Vol_69 : 7|16@0+ (0.001,0) [1|1] "V"  BMS
 SG_ BMU11_Vol_70 : 23|16@0+ (0.001,0) [1|1] "V"  BMS
 SG_ BMU11_Vol_71 : 39|16@0+ (0.001,0) [1|1] "V"  BMS
 SG_ BMU11_Vol_72 : 55|16@0+ (0.001,0) [1|1] "V"  BMS

BO_ 2282881035 BMU11_Vol_73: 8 BMU
 SG_ BMU11_Vol_73 : 7|16@0+ (0.001,0) [1|1] "V"  BMS
 SG_ BMU11_Vol_74 : 23|16@0+ (0.001,0) [1|1] "V"  BMS
 SG_ BMU11_Vol_75 : 39|16@0+ (0.001,0) [1|1] "V"  BMS
 SG_ BMU11_Vol_76 : 55|16@0+ (0.001,0) [1|1] "V"  BMS

BO_ 2282946571 BMU11_Vol_77: 8 BMU
 SG_ BMU11_Vol_77 : 7|16@0+ (0.001,0) [1|1] "V"  BMS
 SG_ BMU11_Vol_78 : 23|16@0+ (0.001,0) [1|1] "V"  BMS
 SG_ BMU11_Vol_79 : 39|16@0+ (0.001,0) [1|1] "V"  BMS
 SG_ BMU11_Vol_80 : 55|16@0+ (0.001,0) [1|1] "V"  BMS

BO_ 2283012107 BMU11_Vol_81: 8 BMU
 SG_ BMU11_Vol_81 : 7|16@0+ (0.001,0) [1|1] "V"  BMS
 SG_ BMU11_Vol_82 : 23|16@0+ (0.001,0) [1|1] "V"  BMS
 SG_ BMU11_Vol_83 : 39|16@0+ (0.001,0) [1|1] "V"  BMS
 SG_ BMU11_Vol_84 : 55|16@0+ (0.001,0) [1|1] "V"  BMS

BO_ 2283077643 BMU11_Vol_85: 8 BMU
 SG_ BMU11_Vol_85 : 7|16@0+ (0.001,0) [1|1] "V"  BMS
 SG_ BMU11_Vol_86 : 23|16@0+ (0.001,0) [1|1] "V"  BMS
 SG_ BMU11_Vol_87 : 39|16@0+ (0.001,0) [1|1] "V"  BMS
 SG_ BMU11_Vol_88 : 55|16@0+ (0.001,0) [1|1] "V"  BMS

BO_ 2283143179 BMU11_Vol_89: 8 BMU
 SG_ BMU11_Vol_89 : 7|16@0+ (0.001,0) [1|1] "V"  BMS
 SG_ BMU11_Vol_90 : 23|16@0+ (0.001,0) [1|1] "V"  BMS
 SG_ BMU11_Vol_91 : 39|16@0+ (0.001,0) [1|1] "V"  BMS
 SG_ BMU11_Vol_92 : 55|16@0+ (0.001,0) [1|1] "V"  BMS

BO_ 2283208715 BMU11_Vol_93: 8 BMU
 SG_ BMU11_Vol_93 : 7|16@0+ (0.001,0) [1|1] "V"  BMS
 SG_ BMU11_Vol_94 : 23|16@0+ (0.001,0) [1|1] "V"  BMS
 SG_ BMU11_Vol_95 : 39|16@0+ (0.001,0) [1|1] "V"  BMS
 SG_ BMU11_Vol_96 : 55|16@0+ (0.001,0) [1|1] "V"  BMS

BO_ 2281701388 BMU12_Vol_1: 8 BMU
 SG_ BMU12_Vol_1 : 7|16@0+ (0.001,0) [1|1] "V"  BMS
 SG_ BMU12_Vol_2 : 23|16@0+ (0.001,0) [1|1] "V"  BMS
 SG_ BMU12_Vol_3 : 39|16@0+ (0.001,0) [1|1] "V"  BMS
 SG_ BMU12_Vol_4 : 55|16@0+ (0.001,0) [1|1] "V"  BMS

BO_ 2281766924 BMU12_Vol_5: 8 BMU
 SG_ BMU12_Vol_5 : 7|16@0+ (0.001,0) [1|1] "V"  BMS
 SG_ BMU12_Vol_6 : 23|16@0+ (0.001,0) [1|1] "V"  BMS
 SG_ BMU12_Vol_7 : 39|16@0+ (0.001,0) [1|1] "V"  BMS
 SG_ BMU12_Vol_8 : 55|16@0+ (0.001,0) [1|1] "V"  BMS

BO_ 2281832460 BMU12_Vol_9: 8 BMU
 SG_ BMU12_Vol_9 : 7|16@0+ (0.001,0) [1|1] "V"  BMS
 SG_ BMU12_Vol_10 : 23|16@0+ (0.001,0) [1|1] "V"  BMS
 SG_ BMU12_Vol_11 : 39|16@0+ (0.001,0) [1|1] "V"  BMS
 SG_ BMU12_Vol_12 : 55|16@0+ (0.001,0) [1|1] "V"  BMS

BO_ 2281897996 BMU12_Vol_13: 8 BMU
 SG_ BMU12_Vol_13 : 7|16@0+ (0.001,0) [1|1] "V"  BMS
 SG_ BMU12_Vol_14 : 23|16@0+ (0.001,0) [1|1] "V"  BMS
 SG_ BMU12_Vol_15 : 39|16@0+ (0.001,0) [1|1] "V"  BMS
 SG_ BMU12_Vol_16 : 55|16@0+ (0.001,0) [1|1] "V"  BMS

BO_ 2281963532 BMU12_Vol_17: 8 BMU
 SG_ BMU12_Vol_17 : 7|16@0+ (0.001,0) [1|1] "V"  BMS
 SG_ BMU12_Vol_18 : 23|16@0+ (0.001,0) [1|1] "V"  BMS
 SG_ BMU12_Vol_19 : 39|16@0+ (0.001,0) [1|1] "V"  BMS
 SG_ BMU12_Vol_20 : 55|16@0+ (0.001,0) [1|1] "V"  BMS

BO_ 2282029068 BMU12_Vol_21: 8 BMU
 SG_ BMU12_Vol_21 : 7|16@0+ (0.001,0) [1|1] "V"  BMS
 SG_ BMU12_Vol_22 : 23|16@0+ (0.001,0) [1|1] "V"  BMS
 SG_ BMU12_Vol_23 : 39|16@0+ (0.001,0) [1|1] "V"  BMS
 SG_ BMU12_Vol_24 : 55|16@0+ (0.001,0) [1|1] "V"  BMS

BO_ 2282094604 BMU12_Vol_25: 8 BMU
 SG_ BMU12_Vol_25 : 7|16@0+ (0.001,0) [1|1] "V"  BMS
 SG_ BMU12_Vol_26 : 23|16@0+ (0.001,0) [1|1] "V"  BMS
 SG_ BMU12_Vol_27 : 39|16@0+ (0.001,0) [1|1] "V"  BMS
 SG_ BMU12_Vol_28 : 55|16@0+ (0.001,0) [1|1] "V"  BMS

BO_ 2282160140 BMU12_Vol_29: 8 BMU
 SG_ BMU12_Vol_29 : 7|16@0+ (0.001,0) [1|1] "V"  BMS
 SG_ BMU12_Vol_30 : 23|16@0+ (0.001,0) [1|1] "V"  BMS
 SG_ BMU12_Vol_31 : 39|16@0+ (0.001,0) [1|1] "V"  BMS
 SG_ BMU12_Vol_32 : 55|16@0+ (0.001,0) [1|1] "V"  BMS

BO_ 2282225676 BMU12_Vol_33: 8 BMU
 SG_ BMU12_Vol_33 : 7|16@0+ (0.001,0) [1|1] "V"  BMS
 SG_ BMU12_Vol_34 : 23|16@0+ (0.001,0) [1|1] "V"  BMS
 SG_ BMU12_Vol_35 : 39|16@0+ (0.001,0) [1|1] "V"  BMS
 SG_ BMU12_Vol_36 : 55|16@0+ (0.001,0) [1|1] "V"  BMS

BO_ 2282291212 BMU12_Vol_37: 8 BMU
 SG_ BMU12_Vol_37 : 7|16@0+ (0.001,0) [1|1] "V"  BMS
 SG_ BMU12_Vol_38 : 23|16@0+ (0.001,0) [1|1] "V"  BMS
 SG_ BMU12_Vol_39 : 39|16@0+ (0.001,0) [1|1] "V"  BMS
 SG_ BMU12_Vol_40 : 55|16@0+ (0.001,0) [1|1] "V"  BMS

BO_ 2282356748 BMU12_Vol_41: 8 BMU
 SG_ BMU12_Vol_41 : 7|16@0+ (0.001,0) [1|1] "V"  BMS
 SG_ BMU12_Vol_42 : 23|16@0+ (0.001,0) [1|1] "V"  BMS
 SG_ BMU12_Vol_43 : 39|16@0+ (0.001,0) [1|1] "V"  BMS
 SG_ BMU12_Vol_44 : 55|16@0+ (0.001,0) [1|1] "V"  BMS

BO_ 2282422284 BMU12_Vol_45: 8 BMU
 SG_ BMU12_Vol_45 : 7|16@0+ (0.001,0) [1|1] "V"  BMS
 SG_ BMU12_Vol_46 : 23|16@0+ (0.001,0) [1|1] "V"  BMS
 SG_ BMU12_Vol_47 : 39|16@0+ (0.001,0) [1|1] "V"  BMS
 SG_ BMU12_Vol_48 : 55|16@0+ (0.001,0) [1|1] "V"  BMS

BO_ 2282487820 BMU12_Vol_49: 8 BMU
 SG_ BMU12_Vol_49 : 7|16@0+ (0.001,0) [1|1] "V"  BMS
 SG_ BMU12_Vol_50 : 23|16@0+ (0.001,0) [1|1] "V"  BMS
 SG_ BMU12_Vol_51 : 39|16@0+ (0.001,0) [1|1] "V"  BMS
 SG_ BMU12_Vol_52 : 55|16@0+ (0.001,0) [1|1] "V"  BMS

BO_ 2282553356 BMU12_Vol_53: 8 BMU
 SG_ BMU12_Vol_53 : 7|16@0+ (0.001,0) [1|1] "V"  BMS
 SG_ BMU12_Vol_54 : 23|16@0+ (0.001,0) [1|1] "V"  BMS
 SG_ BMU12_Vol_55 : 39|16@0+ (0.001,0) [1|1] "V"  BMS
 SG_ BMU12_Vol_56 : 55|16@0+ (0.001,0) [1|1] "V"  BMS

BO_ 2282618892 BMU12_Vol_57: 8 BMU
 SG_ BMU12_Vol_57 : 7|16@0+ (0.001,0) [1|1] "V"  BMS
 SG_ BMU12_Vol_58 : 23|16@0+ (0.001,0) [1|1] "V"  BMS
 SG_ BMU12_Vol_59 : 39|16@0+ (0.001,0) [1|1] "V"  BMS
 SG_ BMU12_Vol_60 : 55|16@0+ (0.001,0) [1|1] "V"  BMS

BO_ 2282684428 BMU12_Vol_61: 8 BMU
 SG_ BMU12_Vol_61 : 7|16@0+ (0.001,0) [1|1] "V"  BMS
 SG_ BMU12_Vol_62 : 23|16@0+ (0.001,0) [1|1] "V"  BMS
 SG_ BMU12_Vol_63 : 39|16@0+ (0.001,0) [1|1] "V"  BMS
 SG_ BMU12_Vol_64 : 55|16@0+ (0.001,0) [1|1] "V"  BMS

BO_ 2282749964 BMU12_Vol_65: 8 BMU
 SG_ BMU12_Vol_65 : 7|16@0+ (0.001,0) [1|1] "V"  BMS
 SG_ BMU12_Vol_66 : 23|16@0+ (0.001,0) [1|1] "V"  BMS
 SG_ BMU12_Vol_67 : 39|16@0+ (0.001,0) [1|1] "V"  BMS
 SG_ BMU12_Vol_68 : 55|16@0+ (0.001,0) [1|1] "V"  BMS

BO_ 2282815500 BMU12_Vol_69: 8 BMU
 SG_ BMU12_Vol_69 : 7|16@0+ (0.001,0) [1|1] "V"  BMS
 SG_ BMU12_Vol_70 : 23|16@0+ (0.001,0) [1|1] "V"  BMS
 SG_ BMU12_Vol_71 : 39|16@0+ (0.001,0) [1|1] "V"  BMS
 SG_ BMU12_Vol_72 : 55|16@0+ (0.001,0) [1|1] "V"  BMS

BO_ 2282881036 BMU12_Vol_73: 8 BMU
 SG_ BMU12_Vol_73 : 7|16@0+ (0.001,0) [1|1] "V"  BMS
 SG_ BMU12_Vol_74 : 23|16@0+ (0.001,0) [1|1] "V"  BMS
 SG_ BMU12_Vol_75 : 39|16@0+ (0.001,0) [1|1] "V"  BMS
 SG_ BMU12_Vol_76 : 55|16@0+ (0.001,0) [1|1] "V"  BMS

BO_ 2282946572 BMU12_Vol_77: 8 BMU
 SG_ BMU12_Vol_77 : 7|16@0+ (0.001,0) [1|1] "V"  BMS
 SG_ BMU12_Vol_78 : 23|16@0+ (0.001,0) [1|1] "V"  BMS
 SG_ BMU12_Vol_79 : 39|16@0+ (0.001,0) [1|1] "V"  BMS
 SG_ BMU12_Vol_80 : 55|16@0+ (0.001,0) [1|1] "V"  BMS

BO_ 2283012108 BMU12_Vol_81: 8 BMU
 SG_ BMU12_Vol_81 : 7|16@0+ (0.001,0) [1|1] "V"  BMS
 SG_ BMU12_Vol_82 : 23|16@0+ (0.001,0) [1|1] "V"  BMS
 SG_ BMU12_Vol_83 : 39|16@0+ (0.001,0) [1|1] "V"  BMS
 SG_ BMU12_Vol_84 : 55|16@0+ (0.001,0) [1|1] "V"  BMS

BO_ 2283077644 BMU12_Vol_85: 8 BMU
 SG_ BMU12_Vol_85 : 7|16@0+ (0.001,0) [1|1] "V"  BMS
 SG_ BMU12_Vol_86 : 23|16@0+ (0.001,0) [1|1] "V"  BMS
 SG_ BMU12_Vol_87 : 39|16@0+ (0.001,0) [1|1] "V"  BMS
 SG_ BMU12_Vol_88 : 55|16@0+ (0.001,0) [1|1] "V"  BMS

BO_ 2283143180 BMU12_Vol_89: 8 BMU
 SG_ BMU12_Vol_89 : 7|16@0+ (0.001,0) [1|1] "V"  BMS
 SG_ BMU12_Vol_90 : 23|16@0+ (0.001,0) [1|1] "V"  BMS
 SG_ BMU12_Vol_91 : 39|16@0+ (0.001,0) [1|1] "V"  BMS
 SG_ BMU12_Vol_92 : 55|16@0+ (0.001,0) [1|1] "V"  BMS

BO_ 2283208716 BMU12_Vol_93: 8 BMU
 SG_ BMU12_Vol_93 : 7|16@0+ (0.001,0) [1|1] "V"  BMS
 SG_ BMU12_Vol_94 : 23|16@0+ (0.001,0) [1|1] "V"  BMS
 SG_ BMU12_Vol_95 : 39|16@0+ (0.001,0) [1|1] "V"  BMS
 SG_ BMU12_Vol_96 : 55|16@0+ (0.001,0) [1|1] "V"  BMS

BO_ 2281701389 BMU13_Vol_1: 8 BMU
 SG_ BMU13_Vol_1 : 7|16@0+ (0.001,0) [1|1] "V"  BMS
 SG_ BMU13_Vol_2 : 23|16@0+ (0.001,0) [1|1] "V"  BMS
 SG_ BMU13_Vol_3 : 39|16@0+ (0.001,0) [1|1] "V"  BMS
 SG_ BMU13_Vol_4 : 55|16@0+ (0.001,0) [1|1] "V"  BMS

BO_ 2281766925 BMU13_Vol_5: 8 BMU
 SG_ BMU13_Vol_5 : 7|16@0+ (0.001,0) [1|1] "V"  BMS
 SG_ BMU13_Vol_6 : 23|16@0+ (0.001,0) [1|1] "V"  BMS
 SG_ BMU13_Vol_7 : 39|16@0+ (0.001,0) [1|1] "V"  BMS
 SG_ BMU13_Vol_8 : 55|16@0+ (0.001,0) [1|1] "V"  BMS

BO_ 2281832461 BMU13_Vol_9: 8 BMU
 SG_ BMU13_Vol_9 : 7|16@0+ (0.001,0) [1|1] "V"  BMS
 SG_ BMU13_Vol_10 : 23|16@0+ (0.001,0) [1|1] "V"  BMS
 SG_ BMU13_Vol_11 : 39|16@0+ (0.001,0) [1|1] "V"  BMS
 SG_ BMU13_Vol_12 : 55|16@0+ (0.001,0) [1|1] "V"  BMS

BO_ 2281897997 BMU13_Vol_13: 8 BMU
 SG_ BMU13_Vol_13 : 7|16@0+ (0.001,0) [1|1] "V"  BMS
 SG_ BMU13_Vol_14 : 23|16@0+ (0.001,0) [1|1] "V"  BMS
 SG_ BMU13_Vol_15 : 39|16@0+ (0.001,0) [1|1] "V"  BMS
 SG_ BMU13_Vol_16 : 55|16@0+ (0.001,0) [1|1] "V"  BMS

BO_ 2281963533 BMU13_Vol_17: 8 BMU
 SG_ BMU13_Vol_17 : 7|16@0+ (0.001,0) [1|1] "V"  BMS
 SG_ BMU13_Vol_18 : 23|16@0+ (0.001,0) [1|1] "V"  BMS
 SG_ BMU13_Vol_19 : 39|16@0+ (0.001,0) [1|1] "V"  BMS
 SG_ BMU13_Vol_20 : 55|16@0+ (0.001,0) [1|1] "V"  BMS

BO_ 2282029069 BMU13_Vol_21: 8 BMU
 SG_ BMU13_Vol_21 : 7|16@0+ (0.001,0) [1|1] "V"  BMS
 SG_ BMU13_Vol_22 : 23|16@0+ (0.001,0) [1|1] "V"  BMS
 SG_ BMU13_Vol_23 : 39|16@0+ (0.001,0) [1|1] "V"  BMS
 SG_ BMU13_Vol_24 : 55|16@0+ (0.001,0) [1|1] "V"  BMS

BO_ 2282094605 BMU13_Vol_25: 8 BMU
 SG_ BMU13_Vol_25 : 7|16@0+ (0.001,0) [1|1] "V"  BMS
 SG_ BMU13_Vol_26 : 23|16@0+ (0.001,0) [1|1] "V"  BMS
 SG_ BMU13_Vol_27 : 39|16@0+ (0.001,0) [1|1] "V"  BMS
 SG_ BMU13_Vol_28 : 55|16@0+ (0.001,0) [1|1] "V"  BMS

BO_ 2282160141 BMU13_Vol_29: 8 BMU
 SG_ BMU13_Vol_29 : 7|16@0+ (0.001,0) [1|1] "V"  BMS
 SG_ BMU13_Vol_30 : 23|16@0+ (0.001,0) [1|1] "V"  BMS
 SG_ BMU13_Vol_31 : 39|16@0+ (0.001,0) [1|1] "V"  BMS
 SG_ BMU13_Vol_32 : 55|16@0+ (0.001,0) [1|1] "V"  BMS

BO_ 2282225677 BMU13_Vol_33: 8 BMU
 SG_ BMU13_Vol_33 : 7|16@0+ (0.001,0) [1|1] "V"  BMS
 SG_ BMU13_Vol_34 : 23|16@0+ (0.001,0) [1|1] "V"  BMS
 SG_ BMU13_Vol_35 : 39|16@0+ (0.001,0) [1|1] "V"  BMS
 SG_ BMU13_Vol_36 : 55|16@0+ (0.001,0) [1|1] "V"  BMS

BO_ 2282291213 BMU13_Vol_37: 8 BMU
 SG_ BMU13_Vol_37 : 7|16@0+ (0.001,0) [1|1] "V"  BMS
 SG_ BMU13_Vol_38 : 23|16@0+ (0.001,0) [1|1] "V"  BMS
 SG_ BMU13_Vol_39 : 39|16@0+ (0.001,0) [1|1] "V"  BMS
 SG_ BMU13_Vol_40 : 55|16@0+ (0.001,0) [1|1] "V"  BMS

BO_ 2282356749 BMU13_Vol_41: 8 BMU
 SG_ BMU13_Vol_41 : 7|16@0+ (0.001,0) [1|1] "V"  BMS
 SG_ BMU13_Vol_42 : 23|16@0+ (0.001,0) [1|1] "V"  BMS
 SG_ BMU13_Vol_43 : 39|16@0+ (0.001,0) [1|1] "V"  BMS
 SG_ BMU13_Vol_44 : 55|16@0+ (0.001,0) [1|1] "V"  BMS

BO_ 2282422285 BMU13_Vol_45: 8 BMU
 SG_ BMU13_Vol_45 : 7|16@0+ (0.001,0) [1|1] "V"  BMS
 SG_ BMU13_Vol_46 : 23|16@0+ (0.001,0) [1|1] "V"  BMS
 SG_ BMU13_Vol_47 : 39|16@0+ (0.001,0) [1|1] "V"  BMS
 SG_ BMU13_Vol_48 : 55|16@0+ (0.001,0) [1|1] "V"  BMS

BO_ 2282487821 BMU13_Vol_49: 8 BMU
 SG_ BMU13_Vol_49 : 7|16@0+ (0.001,0) [1|1] "V"  BMS
 SG_ BMU13_Vol_50 : 23|16@0+ (0.001,0) [1|1] "V"  BMS
 SG_ BMU13_Vol_51 : 39|16@0+ (0.001,0) [1|1] "V"  BMS
 SG_ BMU13_Vol_52 : 55|16@0+ (0.001,0) [1|1] "V"  BMS

BO_ 2282553357 BMU13_Vol_53: 8 BMU
 SG_ BMU13_Vol_53 : 7|16@0+ (0.001,0) [1|1] "V"  BMS
 SG_ BMU13_Vol_54 : 23|16@0+ (0.001,0) [1|1] "V"  BMS
 SG_ BMU13_Vol_55 : 39|16@0+ (0.001,0) [1|1] "V"  BMS
 SG_ BMU13_Vol_56 : 55|16@0+ (0.001,0) [1|1] "V"  BMS

BO_ 2282618893 BMU13_Vol_57: 8 BMU
 SG_ BMU13_Vol_57 : 7|16@0+ (0.001,0) [1|1] "V"  BMS
 SG_ BMU13_Vol_58 : 23|16@0+ (0.001,0) [1|1] "V"  BMS
 SG_ BMU13_Vol_59 : 39|16@0+ (0.001,0) [1|1] "V"  BMS
 SG_ BMU13_Vol_60 : 55|16@0+ (0.001,0) [1|1] "V"  BMS

BO_ 2282684429 BMU13_Vol_61: 8 BMU
 SG_ BMU13_Vol_61 : 7|16@0+ (0.001,0) [1|1] "V"  BMS
 SG_ BMU13_Vol_62 : 23|16@0+ (0.001,0) [1|1] "V"  BMS
 SG_ BMU13_Vol_63 : 39|16@0+ (0.001,0) [1|1] "V"  BMS
 SG_ BMU13_Vol_64 : 55|16@0+ (0.001,0) [1|1] "V"  BMS

BO_ 2282749965 BMU13_Vol_65: 8 BMU
 SG_ BMU13_Vol_65 : 7|16@0+ (0.001,0) [1|1] "V"  BMS
 SG_ BMU13_Vol_66 : 23|16@0+ (0.001,0) [1|1] "V"  BMS
 SG_ BMU13_Vol_67 : 39|16@0+ (0.001,0) [1|1] "V"  BMS
 SG_ BMU13_Vol_68 : 55|16@0+ (0.001,0) [1|1] "V"  BMS

BO_ 2282815501 BMU13_Vol_69: 8 BMU
 SG_ BMU13_Vol_69 : 7|16@0+ (0.001,0) [1|1] "V"  BMS
 SG_ BMU13_Vol_70 : 23|16@0+ (0.001,0) [1|1] "V"  BMS
 SG_ BMU13_Vol_71 : 39|16@0+ (0.001,0) [1|1] "V"  BMS
 SG_ BMU13_Vol_72 : 55|16@0+ (0.001,0) [1|1] "V"  BMS

BO_ 2282881037 BMU13_Vol_73: 8 BMU
 SG_ BMU13_Vol_73 : 7|16@0+ (0.001,0) [1|1] "V"  BMS
 SG_ BMU13_Vol_74 : 23|16@0+ (0.001,0) [1|1] "V"  BMS
 SG_ BMU13_Vol_75 : 39|16@0+ (0.001,0) [1|1] "V"  BMS
 SG_ BMU13_Vol_76 : 55|16@0+ (0.001,0) [1|1] "V"  BMS

BO_ 2282946573 BMU13_Vol_77: 8 BMU
 SG_ BMU13_Vol_77 : 7|16@0+ (0.001,0) [1|1] "V"  BMS
 SG_ BMU13_Vol_78 : 23|16@0+ (0.001,0) [1|1] "V"  BMS
 SG_ BMU13_Vol_79 : 39|16@0+ (0.001,0) [1|1] "V"  BMS
 SG_ BMU13_Vol_80 : 55|16@0+ (0.001,0) [1|1] "V"  BMS

BO_ 2283012109 BMU13_Vol_81: 8 BMU
 SG_ BMU13_Vol_81 : 7|16@0+ (0.001,0) [1|1] "V"  BMS
 SG_ BMU13_Vol_82 : 23|16@0+ (0.001,0) [1|1] "V"  BMS
 SG_ BMU13_Vol_83 : 39|16@0+ (0.001,0) [1|1] "V"  BMS
 SG_ BMU13_Vol_84 : 55|16@0+ (0.001,0) [1|1] "V"  BMS

BO_ 2283077645 BMU13_Vol_85: 8 BMU
 SG_ BMU13_Vol_85 : 7|16@0+ (0.001,0) [1|1] "V"  BMS
 SG_ BMU13_Vol_86 : 23|16@0+ (0.001,0) [1|1] "V"  BMS
 SG_ BMU13_Vol_87 : 39|16@0+ (0.001,0) [1|1] "V"  BMS
 SG_ BMU13_Vol_88 : 55|16@0+ (0.001,0) [1|1] "V"  BMS

BO_ 2283143181 BMU13_Vol_89: 8 BMU
 SG_ BMU13_Vol_89 : 7|16@0+ (0.001,0) [1|1] "V"  BMS
 SG_ BMU13_Vol_90 : 23|16@0+ (0.001,0) [1|1] "V"  BMS
 SG_ BMU13_Vol_91 : 39|16@0+ (0.001,0) [1|1] "V"  BMS
 SG_ BMU13_Vol_92 : 55|16@0+ (0.001,0) [1|1] "V"  BMS

BO_ 2283208717 BMU13_Vol_93: 8 BMU
 SG_ BMU13_Vol_93 : 7|16@0+ (0.001,0) [1|1] "V"  BMS
 SG_ BMU13_Vol_94 : 23|16@0+ (0.001,0) [1|1] "V"  BMS
 SG_ BMU13_Vol_95 : 39|16@0+ (0.001,0) [1|1] "V"  BMS
 SG_ BMU13_Vol_96 : 55|16@0+ (0.001,0) [1|1] "V"  BMS

BO_ 2281701390 BMU14_Vol_1: 8 BMU
 SG_ BMU14_Vol_1 : 7|16@0+ (0.001,0) [1|1] "V"  BMS
 SG_ BMU14_Vol_2 : 23|16@0+ (0.001,0) [1|1] "V"  BMS
 SG_ BMU14_Vol_3 : 39|16@0+ (0.001,0) [1|1] "V"  BMS
 SG_ BMU14_Vol_4 : 55|16@0+ (0.001,0) [1|1] "V"  BMS

BO_ 2281766926 BMU14_Vol_5: 8 BMU
 SG_ BMU14_Vol_5 : 7|16@0+ (0.001,0) [1|1] "V"  BMS
 SG_ BMU14_Vol_6 : 23|16@0+ (0.001,0) [1|1] "V"  BMS
 SG_ BMU14_Vol_7 : 39|16@0+ (0.001,0) [1|1] "V"  BMS
 SG_ BMU14_Vol_8 : 55|16@0+ (0.001,0) [1|1] "V"  BMS

BO_ 2281832462 BMU14_Vol_9: 8 BMU
 SG_ BMU14_Vol_9 : 7|16@0+ (0.001,0) [1|1] "V"  BMS
 SG_ BMU14_Vol_10 : 23|16@0+ (0.001,0) [1|1] "V"  BMS
 SG_ BMU14_Vol_11 : 39|16@0+ (0.001,0) [1|1] "V"  BMS
 SG_ BMU14_Vol_12 : 55|16@0+ (0.001,0) [1|1] "V"  BMS

BO_ 2281897998 BMU14_Vol_13: 8 BMU
 SG_ BMU14_Vol_13 : 7|16@0+ (0.001,0) [1|1] "V"  BMS
 SG_ BMU14_Vol_14 : 23|16@0+ (0.001,0) [1|1] "V"  BMS
 SG_ BMU14_Vol_15 : 39|16@0+ (0.001,0) [1|1] "V"  BMS
 SG_ BMU14_Vol_16 : 55|16@0+ (0.001,0) [1|1] "V"  BMS

BO_ 2281963534 BMU14_Vol_17: 8 BMU
 SG_ BMU14_Vol_17 : 7|16@0+ (0.001,0) [1|1] "V"  BMS
 SG_ BMU14_Vol_18 : 23|16@0+ (0.001,0) [1|1] "V"  BMS
 SG_ BMU14_Vol_19 : 39|16@0+ (0.001,0) [1|1] "V"  BMS
 SG_ BMU14_Vol_20 : 55|16@0+ (0.001,0) [1|1] "V"  BMS

BO_ 2282029070 BMU14_Vol_21: 8 BMU
 SG_ BMU14_Vol_21 : 7|16@0+ (0.001,0) [1|1] "V"  BMS
 SG_ BMU14_Vol_22 : 23|16@0+ (0.001,0) [1|1] "V"  BMS
 SG_ BMU14_Vol_23 : 39|16@0+ (0.001,0) [1|1] "V"  BMS
 SG_ BMU14_Vol_24 : 55|16@0+ (0.001,0) [1|1] "V"  BMS

BO_ 2282094606 BMU14_Vol_25: 8 BMU
 SG_ BMU14_Vol_25 : 7|16@0+ (0.001,0) [1|1] "V"  BMS
 SG_ BMU14_Vol_26 : 23|16@0+ (0.001,0) [1|1] "V"  BMS
 SG_ BMU14_Vol_27 : 39|16@0+ (0.001,0) [1|1] "V"  BMS
 SG_ BMU14_Vol_28 : 55|16@0+ (0.001,0) [1|1] "V"  BMS

BO_ 2282160142 BMU14_Vol_29: 8 BMU
 SG_ BMU14_Vol_29 : 7|16@0+ (0.001,0) [1|1] "V"  BMS
 SG_ BMU14_Vol_30 : 23|16@0+ (0.001,0) [1|1] "V"  BMS
 SG_ BMU14_Vol_31 : 39|16@0+ (0.001,0) [1|1] "V"  BMS
 SG_ BMU14_Vol_32 : 55|16@0+ (0.001,0) [1|1] "V"  BMS

BO_ 2282225678 BMU14_Vol_33: 8 BMU
 SG_ BMU14_Vol_33 : 7|16@0+ (0.001,0) [1|1] "V"  BMS
 SG_ BMU14_Vol_34 : 23|16@0+ (0.001,0) [1|1] "V"  BMS
 SG_ BMU14_Vol_35 : 39|16@0+ (0.001,0) [1|1] "V"  BMS
 SG_ BMU14_Vol_36 : 55|16@0+ (0.001,0) [1|1] "V"  BMS

BO_ 2282291214 BMU14_Vol_37: 8 BMU
 SG_ BMU14_Vol_37 : 7|16@0+ (0.001,0) [1|1] "V"  BMS
 SG_ BMU14_Vol_38 : 23|16@0+ (0.001,0) [1|1] "V"  BMS
 SG_ BMU14_Vol_39 : 39|16@0+ (0.001,0) [1|1] "V"  BMS
 SG_ BMU14_Vol_40 : 55|16@0+ (0.001,0) [1|1] "V"  BMS

BO_ 2282356750 BMU14_Vol_41: 8 BMU
 SG_ BMU14_Vol_41 : 7|16@0+ (0.001,0) [1|1] "V"  BMS
 SG_ BMU14_Vol_42 : 23|16@0+ (0.001,0) [1|1] "V"  BMS
 SG_ BMU14_Vol_43 : 39|16@0+ (0.001,0) [1|1] "V"  BMS
 SG_ BMU14_Vol_44 : 55|16@0+ (0.001,0) [1|1] "V"  BMS

BO_ 2282422286 BMU14_Vol_45: 8 BMU
 SG_ BMU14_Vol_45 : 7|16@0+ (0.001,0) [1|1] "V"  BMS
 SG_ BMU14_Vol_46 : 23|16@0+ (0.001,0) [1|1] "V"  BMS
 SG_ BMU14_Vol_47 : 39|16@0+ (0.001,0) [1|1] "V"  BMS
 SG_ BMU14_Vol_48 : 55|16@0+ (0.001,0) [1|1] "V"  BMS

BO_ 2282487822 BMU14_Vol_49: 8 BMU
 SG_ BMU14_Vol_49 : 7|16@0+ (0.001,0) [1|1] "V"  BMS
 SG_ BMU14_Vol_50 : 23|16@0+ (0.001,0) [1|1] "V"  BMS
 SG_ BMU14_Vol_51 : 39|16@0+ (0.001,0) [1|1] "V"  BMS
 SG_ BMU14_Vol_52 : 55|16@0+ (0.001,0) [1|1] "V"  BMS

BO_ 2282553358 BMU14_Vol_53: 8 BMU
 SG_ BMU14_Vol_53 : 7|16@0+ (0.001,0) [1|1] "V"  BMS
 SG_ BMU14_Vol_54 : 23|16@0+ (0.001,0) [1|1] "V"  BMS
 SG_ BMU14_Vol_55 : 39|16@0+ (0.001,0) [1|1] "V"  BMS
 SG_ BMU14_Vol_56 : 55|16@0+ (0.001,0) [1|1] "V"  BMS

BO_ 2282618894 BMU14_Vol_57: 8 BMU
 SG_ BMU14_Vol_57 : 7|16@0+ (0.001,0) [1|1] "V"  BMS
 SG_ BMU14_Vol_58 : 23|16@0+ (0.001,0) [1|1] "V"  BMS
 SG_ BMU14_Vol_59 : 39|16@0+ (0.001,0) [1|1] "V"  BMS
 SG_ BMU14_Vol_60 : 55|16@0+ (0.001,0) [1|1] "V"  BMS

BO_ 2282684430 BMU14_Vol_61: 8 BMU
 SG_ BMU14_Vol_61 : 7|16@0+ (0.001,0) [1|1] "V"  BMS
 SG_ BMU14_Vol_62 : 23|16@0+ (0.001,0) [1|1] "V"  BMS
 SG_ BMU14_Vol_63 : 39|16@0+ (0.001,0) [1|1] "V"  BMS
 SG_ BMU14_Vol_64 : 55|16@0+ (0.001,0) [1|1] "V"  BMS

BO_ 2282749966 BMU14_Vol_65: 8 BMU
 SG_ BMU14_Vol_65 : 7|16@0+ (0.001,0) [1|1] "V"  BMS
 SG_ BMU14_Vol_66 : 23|16@0+ (0.001,0) [1|1] "V"  BMS
 SG_ BMU14_Vol_67 : 39|16@0+ (0.001,0) [1|1] "V"  BMS
 SG_ BMU14_Vol_68 : 55|16@0+ (0.001,0) [1|1] "V"  BMS

BO_ 2282815502 BMU14_Vol_69: 8 BMU
 SG_ BMU14_Vol_69 : 7|16@0+ (0.001,0) [1|1] "V"  BMS
 SG_ BMU14_Vol_70 : 23|16@0+ (0.001,0) [1|1] "V"  BMS
 SG_ BMU14_Vol_71 : 39|16@0+ (0.001,0) [1|1] "V"  BMS
 SG_ BMU14_Vol_72 : 55|16@0+ (0.001,0) [1|1] "V"  BMS

BO_ 2282881038 BMU14_Vol_73: 8 BMU
 SG_ BMU14_Vol_73 : 7|16@0+ (0.001,0) [1|1] "V"  BMS
 SG_ BMU14_Vol_74 : 23|16@0+ (0.001,0) [1|1] "V"  BMS
 SG_ BMU14_Vol_75 : 39|16@0+ (0.001,0) [1|1] "V"  BMS
 SG_ BMU14_Vol_76 : 55|16@0+ (0.001,0) [1|1] "V"  BMS

BO_ 2282946574 BMU14_Vol_77: 8 BMU
 SG_ BMU14_Vol_77 : 7|16@0+ (0.001,0) [1|1] "V"  BMS
 SG_ BMU14_Vol_78 : 23|16@0+ (0.001,0) [1|1] "V"  BMS
 SG_ BMU14_Vol_79 : 39|16@0+ (0.001,0) [1|1] "V"  BMS
 SG_ BMU14_Vol_80 : 55|16@0+ (0.001,0) [1|1] "V"  BMS

BO_ 2283012110 BMU14_Vol_81: 8 BMU
 SG_ BMU14_Vol_81 : 7|16@0+ (0.001,0) [1|1] "V"  BMS
 SG_ BMU14_Vol_82 : 23|16@0+ (0.001,0) [1|1] "V"  BMS
 SG_ BMU14_Vol_83 : 39|16@0+ (0.001,0) [1|1] "V"  BMS
 SG_ BMU14_Vol_84 : 55|16@0+ (0.001,0) [1|1] "V"  BMS

BO_ 2283077646 BMU14_Vol_85: 8 BMU
 SG_ BMU14_Vol_85 : 7|16@0+ (0.001,0) [1|1] "V"  BMS
 SG_ BMU14_Vol_86 : 23|16@0+ (0.001,0) [1|1] "V"  BMS
 SG_ BMU14_Vol_87 : 39|16@0+ (0.001,0) [1|1] "V"  BMS
 SG_ BMU14_Vol_88 : 55|16@0+ (0.001,0) [1|1] "V"  BMS

BO_ 2283143182 BMU14_Vol_89: 8 BMU
 SG_ BMU14_Vol_89 : 7|16@0+ (0.001,0) [1|1] "V"  BMS
 SG_ BMU14_Vol_90 : 23|16@0+ (0.001,0) [1|1] "V"  BMS
 SG_ BMU14_Vol_91 : 39|16@0+ (0.001,0) [1|1] "V"  BMS
 SG_ BMU14_Vol_92 : 55|16@0+ (0.001,0) [1|1] "V"  BMS

BO_ 2283208718 BMU14_Vol_93: 8 BMU
 SG_ BMU14_Vol_93 : 7|16@0+ (0.001,0) [1|1] "V"  BMS
 SG_ BMU14_Vol_94 : 23|16@0+ (0.001,0) [1|1] "V"  BMS
 SG_ BMU14_Vol_95 : 39|16@0+ (0.001,0) [1|1] "V"  BMS
 SG_ BMU14_Vol_96 : 55|16@0+ (0.001,0) [1|1] "V"  BMS

BO_ 2281701391 BMU15_Vol_1: 8 BMU
 SG_ BMU15_Vol_1 : 7|16@0+ (0.001,0) [1|1] "V"  BMS
 SG_ BMU15_Vol_2 : 23|16@0+ (0.001,0) [1|1] "V"  BMS
 SG_ BMU15_Vol_3 : 39|16@0+ (0.001,0) [1|1] "V"  BMS
 SG_ BMU15_Vol_4 : 55|16@0+ (0.001,0) [1|1] "V"  BMS

BO_ 2281766927 BMU15_Vol_5: 8 BMU
 SG_ BMU15_Vol_5 : 7|16@0+ (0.001,0) [1|1] "V"  BMS
 SG_ BMU15_Vol_6 : 23|16@0+ (0.001,0) [1|1] "V"  BMS
 SG_ BMU15_Vol_7 : 39|16@0+ (0.001,0) [1|1] "V"  BMS
 SG_ BMU15_Vol_8 : 55|16@0+ (0.001,0) [1|1] "V"  BMS

BO_ 2281832463 BMU15_Vol_9: 8 BMU
 SG_ BMU15_Vol_9 : 7|16@0+ (0.001,0) [1|1] "V"  BMS
 SG_ BMU15_Vol_10 : 23|16@0+ (0.001,0) [1|1] "V"  BMS
 SG_ BMU15_Vol_11 : 39|16@0+ (0.001,0) [1|1] "V"  BMS
 SG_ BMU15_Vol_12 : 55|16@0+ (0.001,0) [1|1] "V"  BMS

BO_ 2281897999 BMU15_Vol_13: 8 BMU
 SG_ BMU15_Vol_13 : 7|16@0+ (0.001,0) [1|1] "V"  BMS
 SG_ BMU15_Vol_14 : 23|16@0+ (0.001,0) [1|1] "V"  BMS
 SG_ BMU15_Vol_15 : 39|16@0+ (0.001,0) [1|1] "V"  BMS
 SG_ BMU15_Vol_16 : 55|16@0+ (0.001,0) [1|1] "V"  BMS

BO_ 2281963535 BMU15_Vol_17: 8 BMU
 SG_ BMU15_Vol_17 : 7|16@0+ (0.001,0) [1|1] "V"  BMS
 SG_ BMU15_Vol_18 : 23|16@0+ (0.001,0) [1|1] "V"  BMS
 SG_ BMU15_Vol_19 : 39|16@0+ (0.001,0) [1|1] "V"  BMS
 SG_ BMU15_Vol_20 : 55|16@0+ (0.001,0) [1|1] "V"  BMS

BO_ 2282029071 BMU15_Vol_21: 8 BMU
 SG_ BMU15_Vol_21 : 7|16@0+ (0.001,0) [1|1] "V"  BMS
 SG_ BMU15_Vol_22 : 23|16@0+ (0.001,0) [1|1] "V"  BMS
 SG_ BMU15_Vol_23 : 39|16@0+ (0.001,0) [1|1] "V"  BMS
 SG_ BMU15_Vol_24 : 55|16@0+ (0.001,0) [1|1] "V"  BMS

BO_ 2282094607 BMU15_Vol_25: 8 BMU
 SG_ BMU15_Vol_25 : 7|16@0+ (0.001,0) [1|1] "V"  BMS
 SG_ BMU15_Vol_26 : 23|16@0+ (0.001,0) [1|1] "V"  BMS
 SG_ BMU15_Vol_27 : 39|16@0+ (0.001,0) [1|1] "V"  BMS
 SG_ BMU15_Vol_28 : 55|16@0+ (0.001,0) [1|1] "V"  BMS

BO_ 2282160143 BMU15_Vol_29: 8 BMU
 SG_ BMU15_Vol_29 : 7|16@0+ (0.001,0) [1|1] "V"  BMS
 SG_ BMU15_Vol_30 : 23|16@0+ (0.001,0) [1|1] "V"  BMS
 SG_ BMU15_Vol_31 : 39|16@0+ (0.001,0) [1|1] "V"  BMS
 SG_ BMU15_Vol_32 : 55|16@0+ (0.001,0) [1|1] "V"  BMS

BO_ 2282225679 BMU15_Vol_33: 8 BMU
 SG_ BMU15_Vol_33 : 7|16@0+ (0.001,0) [1|1] "V"  BMS
 SG_ BMU15_Vol_34 : 23|16@0+ (0.001,0) [1|1] "V"  BMS
 SG_ BMU15_Vol_35 : 39|16@0+ (0.001,0) [1|1] "V"  BMS
 SG_ BMU15_Vol_36 : 55|16@0+ (0.001,0) [1|1] "V"  BMS

BO_ 2282291215 BMU15_Vol_37: 8 BMU
 SG_ BMU15_Vol_37 : 7|16@0+ (0.001,0) [1|1] "V"  BMS
 SG_ BMU15_Vol_38 : 23|16@0+ (0.001,0) [1|1] "V"  BMS
 SG_ BMU15_Vol_39 : 39|16@0+ (0.001,0) [1|1] "V"  BMS
 SG_ BMU15_Vol_40 : 55|16@0+ (0.001,0) [1|1] "V"  BMS

BO_ 2282356751 BMU15_Vol_41: 8 BMU
 SG_ BMU15_Vol_41 : 7|16@0+ (0.001,0) [1|1] "V"  BMS
 SG_ BMU15_Vol_42 : 23|16@0+ (0.001,0) [1|1] "V"  BMS
 SG_ BMU15_Vol_43 : 39|16@0+ (0.001,0) [1|1] "V"  BMS
 SG_ BMU15_Vol_44 : 55|16@0+ (0.001,0) [1|1] "V"  BMS

BO_ 2282422287 BMU15_Vol_45: 8 BMU
 SG_ BMU15_Vol_45 : 7|16@0+ (0.001,0) [1|1] "V"  BMS
 SG_ BMU15_Vol_46 : 23|16@0+ (0.001,0) [1|1] "V"  BMS
 SG_ BMU15_Vol_47 : 39|16@0+ (0.001,0) [1|1] "V"  BMS
 SG_ BMU15_Vol_48 : 55|16@0+ (0.001,0) [1|1] "V"  BMS

BO_ 2282487823 BMU15_Vol_49: 8 BMU
 SG_ BMU15_Vol_49 : 7|16@0+ (0.001,0) [1|1] "V"  BMS
 SG_ BMU15_Vol_50 : 23|16@0+ (0.001,0) [1|1] "V"  BMS
 SG_ BMU15_Vol_51 : 39|16@0+ (0.001,0) [1|1] "V"  BMS
 SG_ BMU15_Vol_52 : 55|16@0+ (0.001,0) [1|1] "V"  BMS

BO_ 2282553359 BMU15_Vol_53: 8 BMU
 SG_ BMU15_Vol_53 : 7|16@0+ (0.001,0) [1|1] "V"  BMS
 SG_ BMU15_Vol_54 : 23|16@0+ (0.001,0) [1|1] "V"  BMS
 SG_ BMU15_Vol_55 : 39|16@0+ (0.001,0) [1|1] "V"  BMS
 SG_ BMU15_Vol_56 : 55|16@0+ (0.001,0) [1|1] "V"  BMS

BO_ 2282618895 BMU15_Vol_57: 8 BMU
 SG_ BMU15_Vol_57 : 7|16@0+ (0.001,0) [1|1] "V"  BMS
 SG_ BMU15_Vol_58 : 23|16@0+ (0.001,0) [1|1] "V"  BMS
 SG_ BMU15_Vol_59 : 39|16@0+ (0.001,0) [1|1] "V"  BMS
 SG_ BMU15_Vol_60 : 55|16@0+ (0.001,0) [1|1] "V"  BMS

BO_ 2282684431 BMU15_Vol_61: 8 BMU
 SG_ BMU15_Vol_61 : 7|16@0+ (0.001,0) [1|1] "V"  BMS
 SG_ BMU15_Vol_62 : 23|16@0+ (0.001,0) [1|1] "V"  BMS
 SG_ BMU15_Vol_63 : 39|16@0+ (0.001,0) [1|1] "V"  BMS
 SG_ BMU15_Vol_64 : 55|16@0+ (0.001,0) [1|1] "V"  BMS

BO_ 2282749967 BMU15_Vol_65: 8 BMU
 SG_ BMU15_Vol_65 : 7|16@0+ (0.001,0) [1|1] "V"  BMS
 SG_ BMU15_Vol_66 : 23|16@0+ (0.001,0) [1|1] "V"  BMS
 SG_ BMU15_Vol_67 : 39|16@0+ (0.001,0) [1|1] "V"  BMS
 SG_ BMU15_Vol_68 : 55|16@0+ (0.001,0) [1|1] "V"  BMS

BO_ 2282815503 BMU15_Vol_69: 8 BMU
 SG_ BMU15_Vol_69 : 7|16@0+ (0.001,0) [1|1] "V"  BMS
 SG_ BMU15_Vol_70 : 23|16@0+ (0.001,0) [1|1] "V"  BMS
 SG_ BMU15_Vol_71 : 39|16@0+ (0.001,0) [1|1] "V"  BMS
 SG_ BMU15_Vol_72 : 55|16@0+ (0.001,0) [1|1] "V"  BMS

BO_ 2282881039 BMU15_Vol_73: 8 BMU
 SG_ BMU15_Vol_73 : 7|16@0+ (0.001,0) [1|1] "V"  BMS
 SG_ BMU15_Vol_74 : 23|16@0+ (0.001,0) [1|1] "V"  BMS
 SG_ BMU15_Vol_75 : 39|16@0+ (0.001,0) [1|1] "V"  BMS
 SG_ BMU15_Vol_76 : 55|16@0+ (0.001,0) [1|1] "V"  BMS

BO_ 2282946575 BMU15_Vol_77: 8 BMU
 SG_ BMU15_Vol_77 : 7|16@0+ (0.001,0) [1|1] "V"  BMS
 SG_ BMU15_Vol_78 : 23|16@0+ (0.001,0) [1|1] "V"  BMS
 SG_ BMU15_Vol_79 : 39|16@0+ (0.001,0) [1|1] "V"  BMS
 SG_ BMU15_Vol_80 : 55|16@0+ (0.001,0) [1|1] "V"  BMS

BO_ 2283012111 BMU15_Vol_81: 8 BMU
 SG_ BMU15_Vol_81 : 7|16@0+ (0.001,0) [1|1] "V"  BMS
 SG_ BMU15_Vol_82 : 23|16@0+ (0.001,0) [1|1] "V"  BMS
 SG_ BMU15_Vol_83 : 39|16@0+ (0.001,0) [1|1] "V"  BMS
 SG_ BMU15_Vol_84 : 55|16@0+ (0.001,0) [1|1] "V"  BMS

BO_ 2283077647 BMU15_Vol_85: 8 BMU
 SG_ BMU15_Vol_85 : 7|16@0+ (0.001,0) [1|1] "V"  BMS
 SG_ BMU15_Vol_86 : 23|16@0+ (0.001,0) [1|1] "V"  BMS
 SG_ BMU15_Vol_87 : 39|16@0+ (0.001,0) [1|1] "V"  BMS
 SG_ BMU15_Vol_88 : 55|16@0+ (0.001,0) [1|1] "V"  BMS

BO_ 2283143183 BMU15_Vol_89: 8 BMU
 SG_ BMU15_Vol_89 : 7|16@0+ (0.001,0) [1|1] "V"  BMS
 SG_ BMU15_Vol_90 : 23|16@0+ (0.001,0) [1|1] "V"  BMS
 SG_ BMU15_Vol_91 : 39|16@0+ (0.001,0) [1|1] "V"  BMS
 SG_ BMU15_Vol_92 : 55|16@0+ (0.001,0) [1|1] "V"  BMS

BO_ 2283208719 BMU15_Vol_93: 8 BMU
 SG_ BMU15_Vol_93 : 7|16@0+ (0.001,0) [1|1] "V"  BMS
 SG_ BMU15_Vol_94 : 23|16@0+ (0.001,0) [1|1] "V"  BMS
 SG_ BMU15_Vol_95 : 39|16@0+ (0.001,0) [1|1] "V"  BMS
 SG_ BMU15_Vol_96 : 55|16@0+ (0.001,0) [1|1] "V"  BMS

BO_ 2281701392 BMU16_Vol_1: 8 BMU
 SG_ BMU16_Vol_1 : 7|16@0+ (0.001,0) [1|1] "V"  BMS
 SG_ BMU16_Vol_2 : 23|16@0+ (0.001,0) [1|1] "V"  BMS
 SG_ BMU16_Vol_3 : 39|16@0+ (0.001,0) [1|1] "V"  BMS
 SG_ BMU16_Vol_4 : 55|16@0+ (0.001,0) [1|1] "V"  BMS

BO_ 2281766928 BMU16_Vol_5: 8 BMU
 SG_ BMU16_Vol_5 : 7|16@0+ (0.001,0) [1|1] "V"  BMS
 SG_ BMU16_Vol_6 : 23|16@0+ (0.001,0) [1|1] "V"  BMS
 SG_ BMU16_Vol_7 : 39|16@0+ (0.001,0) [1|1] "V"  BMS
 SG_ BMU16_Vol_8 : 55|16@0+ (0.001,0) [1|1] "V"  BMS

BO_ 2281832464 BMU16_Vol_9: 8 BMU
 SG_ BMU16_Vol_9 : 7|16@0+ (0.001,0) [1|1] "V"  BMS
 SG_ BMU16_Vol_10 : 23|16@0+ (0.001,0) [1|1] "V"  BMS
 SG_ BMU16_Vol_11 : 39|16@0+ (0.001,0) [1|1] "V"  BMS
 SG_ BMU16_Vol_12 : 55|16@0+ (0.001,0) [1|1] "V"  BMS

BO_ 2281898000 BMU16_Vol_13: 8 BMU
 SG_ BMU16_Vol_13 : 7|16@0+ (0.001,0) [1|1] "V"  BMS
 SG_ BMU16_Vol_14 : 23|16@0+ (0.001,0) [1|1] "V"  BMS
 SG_ BMU16_Vol_15 : 39|16@0+ (0.001,0) [1|1] "V"  BMS
 SG_ BMU16_Vol_16 : 55|16@0+ (0.001,0) [1|1] "V"  BMS

BO_ 2281963536 BMU16_Vol_17: 8 BMU
 SG_ BMU16_Vol_17 : 7|16@0+ (0.001,0) [1|1] "V"  BMS
 SG_ BMU16_Vol_18 : 23|16@0+ (0.001,0) [1|1] "V"  BMS
 SG_ BMU16_Vol_19 : 39|16@0+ (0.001,0) [1|1] "V"  BMS
 SG_ BMU16_Vol_20 : 55|16@0+ (0.001,0) [1|1] "V"  BMS

BO_ 2282029072 BMU16_Vol_21: 8 BMU
 SG_ BMU16_Vol_21 : 7|16@0+ (0.001,0) [1|1] "V"  BMS
 SG_ BMU16_Vol_22 : 23|16@0+ (0.001,0) [1|1] "V"  BMS
 SG_ BMU16_Vol_23 : 39|16@0+ (0.001,0) [1|1] "V"  BMS
 SG_ BMU16_Vol_24 : 55|16@0+ (0.001,0) [1|1] "V"  BMS

BO_ 2282094608 BMU16_Vol_25: 8 BMU
 SG_ BMU16_Vol_25 : 7|16@0+ (0.001,0) [1|1] "V"  BMS
 SG_ BMU16_Vol_26 : 23|16@0+ (0.001,0) [1|1] "V"  BMS
 SG_ BMU16_Vol_27 : 39|16@0+ (0.001,0) [1|1] "V"  BMS
 SG_ BMU16_Vol_28 : 55|16@0+ (0.001,0) [1|1] "V"  BMS

BO_ 2282160144 BMU16_Vol_29: 8 BMU
 SG_ BMU16_Vol_29 : 7|16@0+ (0.001,0) [1|1] "V"  BMS
 SG_ BMU16_Vol_30 : 23|16@0+ (0.001,0) [1|1] "V"  BMS
 SG_ BMU16_Vol_31 : 39|16@0+ (0.001,0) [1|1] "V"  BMS
 SG_ BMU16_Vol_32 : 55|16@0+ (0.001,0) [1|1] "V"  BMS

BO_ 2282225680 BMU16_Vol_33: 8 BMU
 SG_ BMU16_Vol_33 : 7|16@0+ (0.001,0) [1|1] "V"  BMS
 SG_ BMU16_Vol_34 : 23|16@0+ (0.001,0) [1|1] "V"  BMS
 SG_ BMU16_Vol_35 : 39|16@0+ (0.001,0) [1|1] "V"  BMS
 SG_ BMU16_Vol_36 : 55|16@0+ (0.001,0) [1|1] "V"  BMS

BO_ 2282291216 BMU16_Vol_37: 8 BMU
 SG_ BMU16_Vol_37 : 7|16@0+ (0.001,0) [1|1] "V"  BMS
 SG_ BMU16_Vol_38 : 23|16@0+ (0.001,0) [1|1] "V"  BMS
 SG_ BMU16_Vol_39 : 39|16@0+ (0.001,0) [1|1] "V"  BMS
 SG_ BMU16_Vol_40 : 55|16@0+ (0.001,0) [1|1] "V"  BMS

BO_ 2282356752 BMU16_Vol_41: 8 BMU
 SG_ BMU16_Vol_41 : 7|16@0+ (0.001,0) [1|1] "V"  BMS
 SG_ BMU16_Vol_42 : 23|16@0+ (0.001,0) [1|1] "V"  BMS
 SG_ BMU16_Vol_43 : 39|16@0+ (0.001,0) [1|1] "V"  BMS
 SG_ BMU16_Vol_44 : 55|16@0+ (0.001,0) [1|1] "V"  BMS

BO_ 2282422288 BMU16_Vol_45: 8 BMU
 SG_ BMU16_Vol_45 : 7|16@0+ (0.001,0) [1|1] "V"  BMS
 SG_ BMU16_Vol_46 : 23|16@0+ (0.001,0) [1|1] "V"  BMS
 SG_ BMU16_Vol_47 : 39|16@0+ (0.001,0) [1|1] "V"  BMS
 SG_ BMU16_Vol_48 : 55|16@0+ (0.001,0) [1|1] "V"  BMS

BO_ 2282487824 BMU16_Vol_49: 8 BMU
 SG_ BMU16_Vol_49 : 7|16@0+ (0.001,0) [1|1] "V"  BMS
 SG_ BMU16_Vol_50 : 23|16@0+ (0.001,0) [1|1] "V"  BMS
 SG_ BMU16_Vol_51 : 39|16@0+ (0.001,0) [1|1] "V"  BMS
 SG_ BMU16_Vol_52 : 55|16@0+ (0.001,0) [1|1] "V"  BMS

BO_ 2282553360 BMU16_Vol_53: 8 BMU
 SG_ BMU16_Vol_53 : 7|16@0+ (0.001,0) [1|1] "V"  BMS
 SG_ BMU16_Vol_54 : 23|16@0+ (0.001,0) [1|1] "V"  BMS
 SG_ BMU16_Vol_55 : 39|16@0+ (0.001,0) [1|1] "V"  BMS
 SG_ BMU16_Vol_56 : 55|16@0+ (0.001,0) [1|1] "V"  BMS

BO_ 2282618896 BMU16_Vol_57: 8 BMU
 SG_ BMU16_Vol_57 : 7|16@0+ (0.001,0) [1|1] "V"  BMS
 SG_ BMU16_Vol_58 : 23|16@0+ (0.001,0) [1|1] "V"  BMS
 SG_ BMU16_Vol_59 : 39|16@0+ (0.001,0) [1|1] "V"  BMS
 SG_ BMU16_Vol_60 : 55|16@0+ (0.001,0) [1|1] "V"  BMS

BO_ 2282684432 BMU16_Vol_61: 8 BMU
 SG_ BMU16_Vol_61 : 7|16@0+ (0.001,0) [1|1] "V"  BMS
 SG_ BMU16_Vol_62 : 23|16@0+ (0.001,0) [1|1] "V"  BMS
 SG_ BMU16_Vol_63 : 39|16@0+ (0.001,0) [1|1] "V"  BMS
 SG_ BMU16_Vol_64 : 55|16@0+ (0.001,0) [1|1] "V"  BMS

BO_ 2282749968 BMU16_Vol_65: 8 BMU
 SG_ BMU16_Vol_65 : 7|16@0+ (0.001,0) [1|1] "V"  BMS
 SG_ BMU16_Vol_66 : 23|16@0+ (0.001,0) [1|1] "V"  BMS
 SG_ BMU16_Vol_67 : 39|16@0+ (0.001,0) [1|1] "V"  BMS
 SG_ BMU16_Vol_68 : 55|16@0+ (0.001,0) [1|1] "V"  BMS

BO_ 2282815504 BMU16_Vol_69: 8 BMU
 SG_ BMU16_Vol_69 : 7|16@0+ (0.001,0) [1|1] "V"  BMS
 SG_ BMU16_Vol_70 : 23|16@0+ (0.001,0) [1|1] "V"  BMS
 SG_ BMU16_Vol_71 : 39|16@0+ (0.001,0) [1|1] "V"  BMS
 SG_ BMU16_Vol_72 : 55|16@0+ (0.001,0) [1|1] "V"  BMS

BO_ 2282881040 BMU16_Vol_73: 8 BMU
 SG_ BMU16_Vol_73 : 7|16@0+ (0.001,0) [1|1] "V"  BMS
 SG_ BMU16_Vol_74 : 23|16@0+ (0.001,0) [1|1] "V"  BMS
 SG_ BMU16_Vol_75 : 39|16@0+ (0.001,0) [1|1] "V"  BMS
 SG_ BMU16_Vol_76 : 55|16@0+ (0.001,0) [1|1] "V"  BMS

BO_ 2282946576 BMU16_Vol_77: 8 BMU
 SG_ BMU16_Vol_77 : 7|16@0+ (0.001,0) [1|1] "V"  BMS
 SG_ BMU16_Vol_78 : 23|16@0+ (0.001,0) [1|1] "V"  BMS
 SG_ BMU16_Vol_79 : 39|16@0+ (0.001,0) [1|1] "V"  BMS
 SG_ BMU16_Vol_80 : 55|16@0+ (0.001,0) [1|1] "V"  BMS

BO_ 2283012112 BMU16_Vol_81: 8 BMU
 SG_ BMU16_Vol_81 : 7|16@0+ (0.001,0) [1|1] "V"  BMS
 SG_ BMU16_Vol_82 : 23|16@0+ (0.001,0) [1|1] "V"  BMS
 SG_ BMU16_Vol_83 : 39|16@0+ (0.001,0) [1|1] "V"  BMS
 SG_ BMU16_Vol_84 : 55|16@0+ (0.001,0) [1|1] "V"  BMS

BO_ 2283077648 BMU16_Vol_85: 8 BMU
 SG_ BMU16_Vol_85 : 7|16@0+ (0.001,0) [1|1] "V"  BMS
 SG_ BMU16_Vol_86 : 23|16@0+ (0.001,0) [1|1] "V"  BMS
 SG_ BMU16_Vol_87 : 39|16@0+ (0.001,0) [1|1] "V"  BMS
 SG_ BMU16_Vol_88 : 55|16@0+ (0.001,0) [1|1] "V"  BMS

BO_ 2283143184 BMU16_Vol_89: 8 BMU
 SG_ BMU16_Vol_89 : 7|16@0+ (0.001,0) [1|1] "V"  BMS
 SG_ BMU16_Vol_90 : 23|16@0+ (0.001,0) [1|1] "V"  BMS
 SG_ BMU16_Vol_91 : 39|16@0+ (0.001,0) [1|1] "V"  BMS
 SG_ BMU16_Vol_92 : 55|16@0+ (0.001,0) [1|1] "V"  BMS

BO_ 2283208720 BMU16_Vol_93: 8 BMU
 SG_ BMU16_Vol_93 : 7|16@0+ (0.001,0) [1|1] "V"  BMS
 SG_ BMU16_Vol_94 : 23|16@0+ (0.001,0) [1|1] "V"  BMS
 SG_ BMU16_Vol_95 : 39|16@0+ (0.001,0) [1|1] "V"  BMS
 SG_ BMU16_Vol_96 : 55|16@0+ (0.001,0) [1|1] "V"  BMS

BO_ 2281701393 BMU17_Vol_1: 8 BMU
 SG_ BMU17_Vol_1 : 7|16@0+ (0.001,0) [1|1] "V"  BMS
 SG_ BMU17_Vol_2 : 23|16@0+ (0.001,0) [1|1] "V"  BMS
 SG_ BMU17_Vol_3 : 39|16@0+ (0.001,0) [1|1] "V"  BMS
 SG_ BMU17_Vol_4 : 55|16@0+ (0.001,0) [1|1] "V"  BMS

BO_ 2281766929 BMU17_Vol_5: 8 BMU
 SG_ BMU17_Vol_5 : 7|16@0+ (0.001,0) [1|1] "V"  BMS
 SG_ BMU17_Vol_6 : 23|16@0+ (0.001,0) [1|1] "V"  BMS
 SG_ BMU17_Vol_7 : 39|16@0+ (0.001,0) [1|1] "V"  BMS
 SG_ BMU17_Vol_8 : 55|16@0+ (0.001,0) [1|1] "V"  BMS

BO_ 2281832465 BMU17_Vol_9: 8 BMU
 SG_ BMU17_Vol_9 : 7|16@0+ (0.001,0) [1|1] "V"  BMS
 SG_ BMU17_Vol_10 : 23|16@0+ (0.001,0) [1|1] "V"  BMS
 SG_ BMU17_Vol_11 : 39|16@0+ (0.001,0) [1|1] "V"  BMS
 SG_ BMU17_Vol_12 : 55|16@0+ (0.001,0) [1|1] "V"  BMS

BO_ 2281898001 BMU17_Vol_13: 8 BMU
 SG_ BMU17_Vol_13 : 7|16@0+ (0.001,0) [1|1] "V"  BMS
 SG_ BMU17_Vol_14 : 23|16@0+ (0.001,0) [1|1] "V"  BMS
 SG_ BMU17_Vol_15 : 39|16@0+ (0.001,0) [1|1] "V"  BMS
 SG_ BMU17_Vol_16 : 55|16@0+ (0.001,0) [1|1] "V"  BMS

BO_ 2281963537 BMU17_Vol_17: 8 BMU
 SG_ BMU17_Vol_17 : 7|16@0+ (0.001,0) [1|1] "V"  BMS
 SG_ BMU17_Vol_18 : 23|16@0+ (0.001,0) [1|1] "V"  BMS
 SG_ BMU17_Vol_19 : 39|16@0+ (0.001,0) [1|1] "V"  BMS
 SG_ BMU17_Vol_20 : 55|16@0+ (0.001,0) [1|1] "V"  BMS

BO_ 2282029073 BMU17_Vol_21: 8 BMU
 SG_ BMU17_Vol_21 : 7|16@0+ (0.001,0) [1|1] "V"  BMS
 SG_ BMU17_Vol_22 : 23|16@0+ (0.001,0) [1|1] "V"  BMS
 SG_ BMU17_Vol_23 : 39|16@0+ (0.001,0) [1|1] "V"  BMS
 SG_ BMU17_Vol_24 : 55|16@0+ (0.001,0) [1|1] "V"  BMS

BO_ 2282094609 BMU17_Vol_25: 8 BMU
 SG_ BMU17_Vol_25 : 7|16@0+ (0.001,0) [1|1] "V"  BMS
 SG_ BMU17_Vol_26 : 23|16@0+ (0.001,0) [1|1] "V"  BMS
 SG_ BMU17_Vol_27 : 39|16@0+ (0.001,0) [1|1] "V"  BMS
 SG_ BMU17_Vol_28 : 55|16@0+ (0.001,0) [1|1] "V"  BMS

BO_ 2282160145 BMU17_Vol_29: 8 BMU
 SG_ BMU17_Vol_29 : 7|16@0+ (0.001,0) [1|1] "V"  BMS
 SG_ BMU17_Vol_30 : 23|16@0+ (0.001,0) [1|1] "V"  BMS
 SG_ BMU17_Vol_31 : 39|16@0+ (0.001,0) [1|1] "V"  BMS
 SG_ BMU17_Vol_32 : 55|16@0+ (0.001,0) [1|1] "V"  BMS

BO_ 2282225681 BMU17_Vol_33: 8 BMU
 SG_ BMU17_Vol_33 : 7|16@0+ (0.001,0) [1|1] "V"  BMS
 SG_ BMU17_Vol_34 : 23|16@0+ (0.001,0) [1|1] "V"  BMS
 SG_ BMU17_Vol_35 : 39|16@0+ (0.001,0) [1|1] "V"  BMS
 SG_ BMU17_Vol_36 : 55|16@0+ (0.001,0) [1|1] "V"  BMS

BO_ 2282291217 BMU17_Vol_37: 8 BMU
 SG_ BMU17_Vol_37 : 7|16@0+ (0.001,0) [1|1] "V"  BMS
 SG_ BMU17_Vol_38 : 23|16@0+ (0.001,0) [1|1] "V"  BMS
 SG_ BMU17_Vol_39 : 39|16@0+ (0.001,0) [1|1] "V"  BMS
 SG_ BMU17_Vol_40 : 55|16@0+ (0.001,0) [1|1] "V"  BMS

BO_ 2282356753 BMU17_Vol_41: 8 BMU
 SG_ BMU17_Vol_41 : 7|16@0+ (0.001,0) [1|1] "V"  BMS
 SG_ BMU17_Vol_42 : 23|16@0+ (0.001,0) [1|1] "V"  BMS
 SG_ BMU17_Vol_43 : 39|16@0+ (0.001,0) [1|1] "V"  BMS
 SG_ BMU17_Vol_44 : 55|16@0+ (0.001,0) [1|1] "V"  BMS

BO_ 2282422289 BMU17_Vol_45: 8 BMU
 SG_ BMU17_Vol_45 : 7|16@0+ (0.001,0) [1|1] "V"  BMS
 SG_ BMU17_Vol_46 : 23|16@0+ (0.001,0) [1|1] "V"  BMS
 SG_ BMU17_Vol_47 : 39|16@0+ (0.001,0) [1|1] "V"  BMS
 SG_ BMU17_Vol_48 : 55|16@0+ (0.001,0) [1|1] "V"  BMS

BO_ 2282487825 BMU17_Vol_49: 8 BMU
 SG_ BMU17_Vol_49 : 7|16@0+ (0.001,0) [1|1] "V"  BMS
 SG_ BMU17_Vol_50 : 23|16@0+ (0.001,0) [1|1] "V"  BMS
 SG_ BMU17_Vol_51 : 39|16@0+ (0.001,0) [1|1] "V"  BMS
 SG_ BMU17_Vol_52 : 55|16@0+ (0.001,0) [1|1] "V"  BMS

BO_ 2282553361 BMU17_Vol_53: 8 BMU
 SG_ BMU17_Vol_53 : 7|16@0+ (0.001,0) [1|1] "V"  BMS
 SG_ BMU17_Vol_54 : 23|16@0+ (0.001,0) [1|1] "V"  BMS
 SG_ BMU17_Vol_55 : 39|16@0+ (0.001,0) [1|1] "V"  BMS
 SG_ BMU17_Vol_56 : 55|16@0+ (0.001,0) [1|1] "V"  BMS

BO_ 2282618897 BMU17_Vol_57: 8 BMU
 SG_ BMU17_Vol_57 : 7|16@0+ (0.001,0) [1|1] "V"  BMS
 SG_ BMU17_Vol_58 : 23|16@0+ (0.001,0) [1|1] "V"  BMS
 SG_ BMU17_Vol_59 : 39|16@0+ (0.001,0) [1|1] "V"  BMS
 SG_ BMU17_Vol_60 : 55|16@0+ (0.001,0) [1|1] "V"  BMS

BO_ 2282684433 BMU17_Vol_61: 8 BMU
 SG_ BMU17_Vol_61 : 7|16@0+ (0.001,0) [1|1] "V"  BMS
 SG_ BMU17_Vol_62 : 23|16@0+ (0.001,0) [1|1] "V"  BMS
 SG_ BMU17_Vol_63 : 39|16@0+ (0.001,0) [1|1] "V"  BMS
 SG_ BMU17_Vol_64 : 55|16@0+ (0.001,0) [1|1] "V"  BMS

BO_ 2282749969 BMU17_Vol_65: 8 BMU
 SG_ BMU17_Vol_65 : 7|16@0+ (0.001,0) [1|1] "V"  BMS
 SG_ BMU17_Vol_66 : 23|16@0+ (0.001,0) [1|1] "V"  BMS
 SG_ BMU17_Vol_67 : 39|16@0+ (0.001,0) [1|1] "V"  BMS
 SG_ BMU17_Vol_68 : 55|16@0+ (0.001,0) [1|1] "V"  BMS

BO_ 2282815505 BMU17_Vol_69: 8 BMU
 SG_ BMU17_Vol_69 : 7|16@0+ (0.001,0) [1|1] "V"  BMS
 SG_ BMU17_Vol_70 : 23|16@0+ (0.001,0) [1|1] "V"  BMS
 SG_ BMU17_Vol_71 : 39|16@0+ (0.001,0) [1|1] "V"  BMS
 SG_ BMU17_Vol_72 : 55|16@0+ (0.001,0) [1|1] "V"  BMS

BO_ 2282881041 BMU17_Vol_73: 8 BMU
 SG_ BMU17_Vol_73 : 7|16@0+ (0.001,0) [1|1] "V"  BMS
 SG_ BMU17_Vol_74 : 23|16@0+ (0.001,0) [1|1] "V"  BMS
 SG_ BMU17_Vol_75 : 39|16@0+ (0.001,0) [1|1] "V"  BMS
 SG_ BMU17_Vol_76 : 55|16@0+ (0.001,0) [1|1] "V"  BMS

BO_ 2282946577 BMU17_Vol_77: 8 BMU
 SG_ BMU17_Vol_77 : 7|16@0+ (0.001,0) [1|1] "V"  BMS
 SG_ BMU17_Vol_78 : 23|16@0+ (0.001,0) [1|1] "V"  BMS
 SG_ BMU17_Vol_79 : 39|16@0+ (0.001,0) [1|1] "V"  BMS
 SG_ BMU17_Vol_80 : 55|16@0+ (0.001,0) [1|1] "V"  BMS

BO_ 2283012113 BMU17_Vol_81: 8 BMU
 SG_ BMU17_Vol_81 : 7|16@0+ (0.001,0) [1|1] "V"  BMS
 SG_ BMU17_Vol_82 : 23|16@0+ (0.001,0) [1|1] "V"  BMS
 SG_ BMU17_Vol_83 : 39|16@0+ (0.001,0) [1|1] "V"  BMS
 SG_ BMU17_Vol_84 : 55|16@0+ (0.001,0) [1|1] "V"  BMS

BO_ 2283077649 BMU17_Vol_85: 8 BMU
 SG_ BMU17_Vol_85 : 7|16@0+ (0.001,0) [1|1] "V"  BMS
 SG_ BMU17_Vol_86 : 23|16@0+ (0.001,0) [1|1] "V"  BMS
 SG_ BMU17_Vol_87 : 39|16@0+ (0.001,0) [1|1] "V"  BMS
 SG_ BMU17_Vol_88 : 55|16@0+ (0.001,0) [1|1] "V"  BMS

BO_ 2283143185 BMU17_Vol_89: 8 BMU
 SG_ BMU17_Vol_89 : 7|16@0+ (0.001,0) [1|1] "V"  BMS
 SG_ BMU17_Vol_90 : 23|16@0+ (0.001,0) [1|1] "V"  BMS
 SG_ BMU17_Vol_91 : 39|16@0+ (0.001,0) [1|1] "V"  BMS
 SG_ BMU17_Vol_92 : 55|16@0+ (0.001,0) [1|1] "V"  BMS

BO_ 2283208721 BMU17_Vol_93: 8 BMU
 SG_ BMU17_Vol_93 : 7|16@0+ (0.001,0) [1|1] "V"  BMS
 SG_ BMU17_Vol_94 : 23|16@0+ (0.001,0) [1|1] "V"  BMS
 SG_ BMU17_Vol_95 : 39|16@0+ (0.001,0) [1|1] "V"  BMS
 SG_ BMU17_Vol_96 : 55|16@0+ (0.001,0) [1|1] "V"  BMS

BO_ 2281701394 BMU18_Vol_1: 8 BMU
 SG_ BMU18_Vol_1 : 7|16@0+ (0.001,0) [1|1] "V"  BMS
 SG_ BMU18_Vol_2 : 23|16@0+ (0.001,0) [1|1] "V"  BMS
 SG_ BMU18_Vol_3 : 39|16@0+ (0.001,0) [1|1] "V"  BMS
 SG_ BMU18_Vol_4 : 55|16@0+ (0.001,0) [1|1] "V"  BMS

BO_ 2281766930 BMU18_Vol_5: 8 BMU
 SG_ BMU18_Vol_5 : 7|16@0+ (0.001,0) [1|1] "V"  BMS
 SG_ BMU18_Vol_6 : 23|16@0+ (0.001,0) [1|1] "V"  BMS
 SG_ BMU18_Vol_7 : 39|16@0+ (0.001,0) [1|1] "V"  BMS
 SG_ BMU18_Vol_8 : 55|16@0+ (0.001,0) [1|1] "V"  BMS

BO_ 2281832466 BMU18_Vol_9: 8 BMU
 SG_ BMU18_Vol_9 : 7|16@0+ (0.001,0) [1|1] "V"  BMS
 SG_ BMU18_Vol_10 : 23|16@0+ (0.001,0) [1|1] "V"  BMS
 SG_ BMU18_Vol_11 : 39|16@0+ (0.001,0) [1|1] "V"  BMS
 SG_ BMU18_Vol_12 : 55|16@0+ (0.001,0) [1|1] "V"  BMS

BO_ 2281898002 BMU18_Vol_13: 8 BMU
 SG_ BMU18_Vol_13 : 7|16@0+ (0.001,0) [1|1] "V"  BMS
 SG_ BMU18_Vol_14 : 23|16@0+ (0.001,0) [1|1] "V"  BMS
 SG_ BMU18_Vol_15 : 39|16@0+ (0.001,0) [1|1] "V"  BMS
 SG_ BMU18_Vol_16 : 55|16@0+ (0.001,0) [1|1] "V"  BMS

BO_ 2281963538 BMU18_Vol_17: 8 BMU
 SG_ BMU18_Vol_17 : 7|16@0+ (0.001,0) [1|1] "V"  BMS
 SG_ BMU18_Vol_18 : 23|16@0+ (0.001,0) [1|1] "V"  BMS
 SG_ BMU18_Vol_19 : 39|16@0+ (0.001,0) [1|1] "V"  BMS
 SG_ BMU18_Vol_20 : 55|16@0+ (0.001,0) [1|1] "V"  BMS

BO_ 2282029074 BMU18_Vol_21: 8 BMU
 SG_ BMU18_Vol_21 : 7|16@0+ (0.001,0) [1|1] "V"  BMS
 SG_ BMU18_Vol_22 : 23|16@0+ (0.001,0) [1|1] "V"  BMS
 SG_ BMU18_Vol_23 : 39|16@0+ (0.001,0) [1|1] "V"  BMS
 SG_ BMU18_Vol_24 : 55|16@0+ (0.001,0) [1|1] "V"  BMS

BO_ 2282094610 BMU18_Vol_25: 8 BMU
 SG_ BMU18_Vol_25 : 7|16@0+ (0.001,0) [1|1] "V"  BMS
 SG_ BMU18_Vol_26 : 23|16@0+ (0.001,0) [1|1] "V"  BMS
 SG_ BMU18_Vol_27 : 39|16@0+ (0.001,0) [1|1] "V"  BMS
 SG_ BMU18_Vol_28 : 55|16@0+ (0.001,0) [1|1] "V"  BMS

BO_ 2282160146 BMU18_Vol_29: 8 BMU
 SG_ BMU18_Vol_29 : 7|16@0+ (0.001,0) [1|1] "V"  BMS
 SG_ BMU18_Vol_30 : 23|16@0+ (0.001,0) [1|1] "V"  BMS
 SG_ BMU18_Vol_31 : 39|16@0+ (0.001,0) [1|1] "V"  BMS
 SG_ BMU18_Vol_32 : 55|16@0+ (0.001,0) [1|1] "V"  BMS

BO_ 2282225682 BMU18_Vol_33: 8 BMU
 SG_ BMU18_Vol_33 : 7|16@0+ (0.001,0) [1|1] "V"  BMS
 SG_ BMU18_Vol_34 : 23|16@0+ (0.001,0) [1|1] "V"  BMS
 SG_ BMU18_Vol_35 : 39|16@0+ (0.001,0) [1|1] "V"  BMS
 SG_ BMU18_Vol_36 : 55|16@0+ (0.001,0) [1|1] "V"  BMS

BO_ 2282291218 BMU18_Vol_37: 8 BMU
 SG_ BMU18_Vol_37 : 7|16@0+ (0.001,0) [1|1] "V"  BMS
 SG_ BMU18_Vol_38 : 23|16@0+ (0.001,0) [1|1] "V"  BMS
 SG_ BMU18_Vol_39 : 39|16@0+ (0.001,0) [1|1] "V"  BMS
 SG_ BMU18_Vol_40 : 55|16@0+ (0.001,0) [1|1] "V"  BMS

BO_ 2282356754 BMU18_Vol_41: 8 BMU
 SG_ BMU18_Vol_41 : 7|16@0+ (0.001,0) [1|1] "V"  BMS
 SG_ BMU18_Vol_42 : 23|16@0+ (0.001,0) [1|1] "V"  BMS
 SG_ BMU18_Vol_43 : 39|16@0+ (0.001,0) [1|1] "V"  BMS
 SG_ BMU18_Vol_44 : 55|16@0+ (0.001,0) [1|1] "V"  BMS

BO_ 2282422290 BMU18_Vol_45: 8 BMU
 SG_ BMU18_Vol_45 : 7|16@0+ (0.001,0) [1|1] "V"  BMS
 SG_ BMU18_Vol_46 : 23|16@0+ (0.001,0) [1|1] "V"  BMS
 SG_ BMU18_Vol_47 : 39|16@0+ (0.001,0) [1|1] "V"  BMS
 SG_ BMU18_Vol_48 : 55|16@0+ (0.001,0) [1|1] "V"  BMS

BO_ 2282487826 BMU18_Vol_49: 8 BMU
 SG_ BMU18_Vol_49 : 7|16@0+ (0.001,0) [1|1] "V"  BMS
 SG_ BMU18_Vol_50 : 23|16@0+ (0.001,0) [1|1] "V"  BMS
 SG_ BMU18_Vol_51 : 39|16@0+ (0.001,0) [1|1] "V"  BMS
 SG_ BMU18_Vol_52 : 55|16@0+ (0.001,0) [1|1] "V"  BMS

BO_ 2282553362 BMU18_Vol_53: 8 BMU
 SG_ BMU18_Vol_53 : 7|16@0+ (0.001,0) [1|1] "V"  BMS
 SG_ BMU18_Vol_54 : 23|16@0+ (0.001,0) [1|1] "V"  BMS
 SG_ BMU18_Vol_55 : 39|16@0+ (0.001,0) [1|1] "V"  BMS
 SG_ BMU18_Vol_56 : 55|16@0+ (0.001,0) [1|1] "V"  BMS

BO_ 2282618898 BMU18_Vol_57: 8 BMU
 SG_ BMU18_Vol_57 : 7|16@0+ (0.001,0) [1|1] "V"  BMS
 SG_ BMU18_Vol_58 : 23|16@0+ (0.001,0) [1|1] "V"  BMS
 SG_ BMU18_Vol_59 : 39|16@0+ (0.001,0) [1|1] "V"  BMS
 SG_ BMU18_Vol_60 : 55|16@0+ (0.001,0) [1|1] "V"  BMS

BO_ 2282684434 BMU18_Vol_61: 8 BMU
 SG_ BMU18_Vol_61 : 7|16@0+ (0.001,0) [1|1] "V"  BMS
 SG_ BMU18_Vol_62 : 23|16@0+ (0.001,0) [1|1] "V"  BMS
 SG_ BMU18_Vol_63 : 39|16@0+ (0.001,0) [1|1] "V"  BMS
 SG_ BMU18_Vol_64 : 55|16@0+ (0.001,0) [1|1] "V"  BMS

BO_ 2282749970 BMU18_Vol_65: 8 BMU
 SG_ BMU18_Vol_65 : 7|16@0+ (0.001,0) [1|1] "V"  BMS
 SG_ BMU18_Vol_66 : 23|16@0+ (0.001,0) [1|1] "V"  BMS
 SG_ BMU18_Vol_67 : 39|16@0+ (0.001,0) [1|1] "V"  BMS
 SG_ BMU18_Vol_68 : 55|16@0+ (0.001,0) [1|1] "V"  BMS

BO_ 2282815506 BMU18_Vol_69: 8 BMU
 SG_ BMU18_Vol_69 : 7|16@0+ (0.001,0) [1|1] "V"  BMS
 SG_ BMU18_Vol_70 : 23|16@0+ (0.001,0) [1|1] "V"  BMS
 SG_ BMU18_Vol_71 : 39|16@0+ (0.001,0) [1|1] "V"  BMS
 SG_ BMU18_Vol_72 : 55|16@0+ (0.001,0) [1|1] "V"  BMS

BO_ 2282881042 BMU18_Vol_73: 8 BMU
 SG_ BMU18_Vol_73 : 7|16@0+ (0.001,0) [1|1] "V"  BMS
 SG_ BMU18_Vol_74 : 23|16@0+ (0.001,0) [1|1] "V"  BMS
 SG_ BMU18_Vol_75 : 39|16@0+ (0.001,0) [1|1] "V"  BMS
 SG_ BMU18_Vol_76 : 55|16@0+ (0.001,0) [1|1] "V"  BMS

BO_ 2282946578 BMU18_Vol_77: 8 BMU
 SG_ BMU18_Vol_77 : 7|16@0+ (0.001,0) [1|1] "V"  BMS
 SG_ BMU18_Vol_78 : 23|16@0+ (0.001,0) [1|1] "V"  BMS
 SG_ BMU18_Vol_79 : 39|16@0+ (0.001,0) [1|1] "V"  BMS
 SG_ BMU18_Vol_80 : 55|16@0+ (0.001,0) [1|1] "V"  BMS

BO_ 2283012114 BMU18_Vol_81: 8 BMU
 SG_ BMU18_Vol_81 : 7|16@0+ (0.001,0) [1|1] "V"  BMS
 SG_ BMU18_Vol_82 : 23|16@0+ (0.001,0) [1|1] "V"  BMS
 SG_ BMU18_Vol_83 : 39|16@0+ (0.001,0) [1|1] "V"  BMS
 SG_ BMU18_Vol_84 : 55|16@0+ (0.001,0) [1|1] "V"  BMS

BO_ 2283077650 BMU18_Vol_85: 8 BMU
 SG_ BMU18_Vol_85 : 7|16@0+ (0.001,0) [1|1] "V"  BMS
 SG_ BMU18_Vol_86 : 23|16@0+ (0.001,0) [1|1] "V"  BMS
 SG_ BMU18_Vol_87 : 39|16@0+ (0.001,0) [1|1] "V"  BMS
 SG_ BMU18_Vol_88 : 55|16@0+ (0.001,0) [1|1] "V"  BMS

BO_ 2283143186 BMU18_Vol_89: 8 BMU
 SG_ BMU18_Vol_89 : 7|16@0+ (0.001,0) [1|1] "V"  BMS
 SG_ BMU18_Vol_90 : 23|16@0+ (0.001,0) [1|1] "V"  BMS
 SG_ BMU18_Vol_91 : 39|16@0+ (0.001,0) [1|1] "V"  BMS
 SG_ BMU18_Vol_92 : 55|16@0+ (0.001,0) [1|1] "V"  BMS

BO_ 2283208722 BMU18_Vol_93: 8 BMU
 SG_ BMU18_Vol_93 : 7|16@0+ (0.001,0) [1|1] "V"  BMS
 SG_ BMU18_Vol_94 : 23|16@0+ (0.001,0) [1|1] "V"  BMS
 SG_ BMU18_Vol_95 : 39|16@0+ (0.001,0) [1|1] "V"  BMS
 SG_ BMU18_Vol_96 : 55|16@0+ (0.001,0) [1|1] "V"  BMS

BO_ 2281701395 BMU19_Vol_1: 8 BMU
 SG_ BMU19_Vol_1 : 7|16@0+ (0.001,0) [1|1] "V"  BMS
 SG_ BMU19_Vol_2 : 23|16@0+ (0.001,0) [1|1] "V"  BMS
 SG_ BMU19_Vol_3 : 39|16@0+ (0.001,0) [1|1] "V"  BMS
 SG_ BMU19_Vol_4 : 55|16@0+ (0.001,0) [1|1] "V"  BMS

BO_ 2281766931 BMU19_Vol_5: 8 BMU
 SG_ BMU19_Vol_5 : 7|16@0+ (0.001,0) [1|1] "V"  BMS
 SG_ BMU19_Vol_6 : 23|16@0+ (0.001,0) [1|1] "V"  BMS
 SG_ BMU19_Vol_7 : 39|16@0+ (0.001,0) [1|1] "V"  BMS
 SG_ BMU19_Vol_8 : 55|16@0+ (0.001,0) [1|1] "V"  BMS

BO_ 2281832467 BMU19_Vol_9: 8 BMU
 SG_ BMU19_Vol_9 : 7|16@0+ (0.001,0) [1|1] "V"  BMS
 SG_ BMU19_Vol_10 : 23|16@0+ (0.001,0) [1|1] "V"  BMS
 SG_ BMU19_Vol_11 : 39|16@0+ (0.001,0) [1|1] "V"  BMS
 SG_ BMU19_Vol_12 : 55|16@0+ (0.001,0) [1|1] "V"  BMS

BO_ 2281898003 BMU19_Vol_13: 8 BMU
 SG_ BMU19_Vol_13 : 7|16@0+ (0.001,0) [1|1] "V"  BMS
 SG_ BMU19_Vol_14 : 23|16@0+ (0.001,0) [1|1] "V"  BMS
 SG_ BMU19_Vol_15 : 39|16@0+ (0.001,0) [1|1] "V"  BMS
 SG_ BMU19_Vol_16 : 55|16@0+ (0.001,0) [1|1] "V"  BMS

BO_ 2281963539 BMU19_Vol_17: 8 BMU
 SG_ BMU19_Vol_17 : 7|16@0+ (0.001,0) [1|1] "V"  BMS
 SG_ BMU19_Vol_18 : 23|16@0+ (0.001,0) [1|1] "V"  BMS
 SG_ BMU19_Vol_19 : 39|16@0+ (0.001,0) [1|1] "V"  BMS
 SG_ BMU19_Vol_20 : 55|16@0+ (0.001,0) [1|1] "V"  BMS

BO_ 2282029075 BMU19_Vol_21: 8 BMU
 SG_ BMU19_Vol_21 : 7|16@0+ (0.001,0) [1|1] "V"  BMS
 SG_ BMU19_Vol_22 : 23|16@0+ (0.001,0) [1|1] "V"  BMS
 SG_ BMU19_Vol_23 : 39|16@0+ (0.001,0) [1|1] "V"  BMS
 SG_ BMU19_Vol_24 : 55|16@0+ (0.001,0) [1|1] "V"  BMS

BO_ 2282094611 BMU19_Vol_25: 8 BMU
 SG_ BMU19_Vol_25 : 7|16@0+ (0.001,0) [1|1] "V"  BMS
 SG_ BMU19_Vol_26 : 23|16@0+ (0.001,0) [1|1] "V"  BMS
 SG_ BMU19_Vol_27 : 39|16@0+ (0.001,0) [1|1] "V"  BMS
 SG_ BMU19_Vol_28 : 55|16@0+ (0.001,0) [1|1] "V"  BMS

BO_ 2282160147 BMU19_Vol_29: 8 BMU
 SG_ BMU19_Vol_29 : 7|16@0+ (0.001,0) [1|1] "V"  BMS
 SG_ BMU19_Vol_30 : 23|16@0+ (0.001,0) [1|1] "V"  BMS
 SG_ BMU19_Vol_31 : 39|16@0+ (0.001,0) [1|1] "V"  BMS
 SG_ BMU19_Vol_32 : 55|16@0+ (0.001,0) [1|1] "V"  BMS

BO_ 2282225683 BMU19_Vol_33: 8 BMU
 SG_ BMU19_Vol_33 : 7|16@0+ (0.001,0) [1|1] "V"  BMS
 SG_ BMU19_Vol_34 : 23|16@0+ (0.001,0) [1|1] "V"  BMS
 SG_ BMU19_Vol_35 : 39|16@0+ (0.001,0) [1|1] "V"  BMS
 SG_ BMU19_Vol_36 : 55|16@0+ (0.001,0) [1|1] "V"  BMS

BO_ 2282291219 BMU19_Vol_37: 8 BMU
 SG_ BMU19_Vol_37 : 7|16@0+ (0.001,0) [1|1] "V"  BMS
 SG_ BMU19_Vol_38 : 23|16@0+ (0.001,0) [1|1] "V"  BMS
 SG_ BMU19_Vol_39 : 39|16@0+ (0.001,0) [1|1] "V"  BMS
 SG_ BMU19_Vol_40 : 55|16@0+ (0.001,0) [1|1] "V"  BMS

BO_ 2282356755 BMU19_Vol_41: 8 BMU
 SG_ BMU19_Vol_41 : 7|16@0+ (0.001,0) [1|1] "V"  BMS
 SG_ BMU19_Vol_42 : 23|16@0+ (0.001,0) [1|1] "V"  BMS
 SG_ BMU19_Vol_43 : 39|16@0+ (0.001,0) [1|1] "V"  BMS
 SG_ BMU19_Vol_44 : 55|16@0+ (0.001,0) [1|1] "V"  BMS

BO_ 2282422291 BMU19_Vol_45: 8 BMU
 SG_ BMU19_Vol_45 : 7|16@0+ (0.001,0) [1|1] "V"  BMS
 SG_ BMU19_Vol_46 : 23|16@0+ (0.001,0) [1|1] "V"  BMS
 SG_ BMU19_Vol_47 : 39|16@0+ (0.001,0) [1|1] "V"  BMS
 SG_ BMU19_Vol_48 : 55|16@0+ (0.001,0) [1|1] "V"  BMS

BO_ 2282487827 BMU19_Vol_49: 8 BMU
 SG_ BMU19_Vol_49 : 7|16@0+ (0.001,0) [1|1] "V"  BMS
 SG_ BMU19_Vol_50 : 23|16@0+ (0.001,0) [1|1] "V"  BMS
 SG_ BMU19_Vol_51 : 39|16@0+ (0.001,0) [1|1] "V"  BMS
 SG_ BMU19_Vol_52 : 55|16@0+ (0.001,0) [1|1] "V"  BMS

BO_ 2282553363 BMU19_Vol_53: 8 BMU
 SG_ BMU19_Vol_53 : 7|16@0+ (0.001,0) [1|1] "V"  BMS
 SG_ BMU19_Vol_54 : 23|16@0+ (0.001,0) [1|1] "V"  BMS
 SG_ BMU19_Vol_55 : 39|16@0+ (0.001,0) [1|1] "V"  BMS
 SG_ BMU19_Vol_56 : 55|16@0+ (0.001,0) [1|1] "V"  BMS

BO_ 2282618899 BMU19_Vol_57: 8 BMU
 SG_ BMU19_Vol_57 : 7|16@0+ (0.001,0) [1|1] "V"  BMS
 SG_ BMU19_Vol_58 : 23|16@0+ (0.001,0) [1|1] "V"  BMS
 SG_ BMU19_Vol_59 : 39|16@0+ (0.001,0) [1|1] "V"  BMS
 SG_ BMU19_Vol_60 : 55|16@0+ (0.001,0) [1|1] "V"  BMS

BO_ 2282684435 BMU19_Vol_61: 8 BMU
 SG_ BMU19_Vol_61 : 7|16@0+ (0.001,0) [1|1] "V"  BMS
 SG_ BMU19_Vol_62 : 23|16@0+ (0.001,0) [1|1] "V"  BMS
 SG_ BMU19_Vol_63 : 39|16@0+ (0.001,0) [1|1] "V"  BMS
 SG_ BMU19_Vol_64 : 55|16@0+ (0.001,0) [1|1] "V"  BMS

BO_ 2282749971 BMU19_Vol_65: 8 BMU
 SG_ BMU19_Vol_65 : 7|16@0+ (0.001,0) [1|1] "V"  BMS
 SG_ BMU19_Vol_66 : 23|16@0+ (0.001,0) [1|1] "V"  BMS
 SG_ BMU19_Vol_67 : 39|16@0+ (0.001,0) [1|1] "V"  BMS
 SG_ BMU19_Vol_68 : 55|16@0+ (0.001,0) [1|1] "V"  BMS

BO_ 2282815507 BMU19_Vol_69: 8 BMU
 SG_ BMU19_Vol_69 : 7|16@0+ (0.001,0) [1|1] "V"  BMS
 SG_ BMU19_Vol_70 : 23|16@0+ (0.001,0) [1|1] "V"  BMS
 SG_ BMU19_Vol_71 : 39|16@0+ (0.001,0) [1|1] "V"  BMS
 SG_ BMU19_Vol_72 : 55|16@0+ (0.001,0) [1|1] "V"  BMS

BO_ 2282881043 BMU19_Vol_73: 8 BMU
 SG_ BMU19_Vol_73 : 7|16@0+ (0.001,0) [1|1] "V"  BMS
 SG_ BMU19_Vol_74 : 23|16@0+ (0.001,0) [1|1] "V"  BMS
 SG_ BMU19_Vol_75 : 39|16@0+ (0.001,0) [1|1] "V"  BMS
 SG_ BMU19_Vol_76 : 55|16@0+ (0.001,0) [1|1] "V"  BMS

BO_ 2282946579 BMU19_Vol_77: 8 BMU
 SG_ BMU19_Vol_77 : 7|16@0+ (0.001,0) [1|1] "V"  BMS
 SG_ BMU19_Vol_78 : 23|16@0+ (0.001,0) [1|1] "V"  BMS
 SG_ BMU19_Vol_79 : 39|16@0+ (0.001,0) [1|1] "V"  BMS
 SG_ BMU19_Vol_80 : 55|16@0+ (0.001,0) [1|1] "V"  BMS

BO_ 2283012115 BMU19_Vol_81: 8 BMU
 SG_ BMU19_Vol_81 : 7|16@0+ (0.001,0) [1|1] "V"  BMS
 SG_ BMU19_Vol_82 : 23|16@0+ (0.001,0) [1|1] "V"  BMS
 SG_ BMU19_Vol_83 : 39|16@0+ (0.001,0) [1|1] "V"  BMS
 SG_ BMU19_Vol_84 : 55|16@0+ (0.001,0) [1|1] "V"  BMS

BO_ 2283077651 BMU19_Vol_85: 8 BMU
 SG_ BMU19_Vol_85 : 7|16@0+ (0.001,0) [1|1] "V"  BMS
 SG_ BMU19_Vol_86 : 23|16@0+ (0.001,0) [1|1] "V"  BMS
 SG_ BMU19_Vol_87 : 39|16@0+ (0.001,0) [1|1] "V"  BMS
 SG_ BMU19_Vol_88 : 55|16@0+ (0.001,0) [1|1] "V"  BMS

BO_ 2283143187 BMU19_Vol_89: 8 BMU
 SG_ BMU19_Vol_89 : 7|16@0+ (0.001,0) [1|1] "V"  BMS
 SG_ BMU19_Vol_90 : 23|16@0+ (0.001,0) [1|1] "V"  BMS
 SG_ BMU19_Vol_91 : 39|16@0+ (0.001,0) [1|1] "V"  BMS
 SG_ BMU19_Vol_92 : 55|16@0+ (0.001,0) [1|1] "V"  BMS

BO_ 2283208723 BMU19_Vol_93: 8 BMU
 SG_ BMU19_Vol_93 : 7|16@0+ (0.001,0) [1|1] "V"  BMS
 SG_ BMU19_Vol_94 : 23|16@0+ (0.001,0) [1|1] "V"  BMS
 SG_ BMU19_Vol_95 : 39|16@0+ (0.001,0) [1|1] "V"  BMS
 SG_ BMU19_Vol_96 : 55|16@0+ (0.001,0) [1|1] "V"  BMS

BO_ 2281701396 BMU20_Vol_1: 8 BMU
 SG_ BMU20_Vol_1 : 7|16@0+ (0.001,0) [1|1] "V"  BMS
 SG_ BMU20_Vol_2 : 23|16@0+ (0.001,0) [1|1] "V"  BMS
 SG_ BMU20_Vol_3 : 39|16@0+ (0.001,0) [1|1] "V"  BMS
 SG_ BMU20_Vol_4 : 55|16@0+ (0.001,0) [1|1] "V"  BMS

BO_ 2281766932 BMU20_Vol_5: 8 BMU
 SG_ BMU20_Vol_5 : 7|16@0+ (0.001,0) [1|1] "V"  BMS
 SG_ BMU20_Vol_6 : 23|16@0+ (0.001,0) [1|1] "V"  BMS
 SG_ BMU20_Vol_7 : 39|16@0+ (0.001,0) [1|1] "V"  BMS
 SG_ BMU20_Vol_8 : 55|16@0+ (0.001,0) [1|1] "V"  BMS

BO_ 2281832468 BMU20_Vol_9: 8 BMU
 SG_ BMU20_Vol_9 : 7|16@0+ (0.001,0) [1|1] "V"  BMS
 SG_ BMU20_Vol_10 : 23|16@0+ (0.001,0) [1|1] "V"  BMS
 SG_ BMU20_Vol_11 : 39|16@0+ (0.001,0) [1|1] "V"  BMS
 SG_ BMU20_Vol_12 : 55|16@0+ (0.001,0) [1|1] "V"  BMS

BO_ 2281898004 BMU20_Vol_13: 8 BMU
 SG_ BMU20_Vol_13 : 7|16@0+ (0.001,0) [1|1] "V"  BMS
 SG_ BMU20_Vol_14 : 23|16@0+ (0.001,0) [1|1] "V"  BMS
 SG_ BMU20_Vol_15 : 39|16@0+ (0.001,0) [1|1] "V"  BMS
 SG_ BMU20_Vol_16 : 55|16@0+ (0.001,0) [1|1] "V"  BMS

BO_ 2281963540 BMU20_Vol_17: 8 BMU
 SG_ BMU20_Vol_17 : 7|16@0+ (0.001,0) [1|1] "V"  BMS
 SG_ BMU20_Vol_18 : 23|16@0+ (0.001,0) [1|1] "V"  BMS
 SG_ BMU20_Vol_19 : 39|16@0+ (0.001,0) [1|1] "V"  BMS
 SG_ BMU20_Vol_20 : 55|16@0+ (0.001,0) [1|1] "V"  BMS

BO_ 2282029076 BMU20_Vol_21: 8 BMU
 SG_ BMU20_Vol_21 : 7|16@0+ (0.001,0) [1|1] "V"  BMS
 SG_ BMU20_Vol_22 : 23|16@0+ (0.001,0) [1|1] "V"  BMS
 SG_ BMU20_Vol_23 : 39|16@0+ (0.001,0) [1|1] "V"  BMS
 SG_ BMU20_Vol_24 : 55|16@0+ (0.001,0) [1|1] "V"  BMS

BO_ 2282094612 BMU20_Vol_25: 8 BMU
 SG_ BMU20_Vol_25 : 7|16@0+ (0.001,0) [1|1] "V"  BMS
 SG_ BMU20_Vol_26 : 23|16@0+ (0.001,0) [1|1] "V"  BMS
 SG_ BMU20_Vol_27 : 39|16@0+ (0.001,0) [1|1] "V"  BMS
 SG_ BMU20_Vol_28 : 55|16@0+ (0.001,0) [1|1] "V"  BMS

BO_ 2282160148 BMU20_Vol_29: 8 BMU
 SG_ BMU20_Vol_29 : 7|16@0+ (0.001,0) [1|1] "V"  BMS
 SG_ BMU20_Vol_30 : 23|16@0+ (0.001,0) [1|1] "V"  BMS
 SG_ BMU20_Vol_31 : 39|16@0+ (0.001,0) [1|1] "V"  BMS
 SG_ BMU20_Vol_32 : 55|16@0+ (0.001,0) [1|1] "V"  BMS

BO_ 2282225684 BMU20_Vol_33: 8 BMU
 SG_ BMU20_Vol_33 : 7|16@0+ (0.001,0) [1|1] "V"  BMS
 SG_ BMU20_Vol_34 : 23|16@0+ (0.001,0) [1|1] "V"  BMS
 SG_ BMU20_Vol_35 : 39|16@0+ (0.001,0) [1|1] "V"  BMS
 SG_ BMU20_Vol_36 : 55|16@0+ (0.001,0) [1|1] "V"  BMS

BO_ 2282291220 BMU20_Vol_37: 8 BMU
 SG_ BMU20_Vol_37 : 7|16@0+ (0.001,0) [1|1] "V"  BMS
 SG_ BMU20_Vol_38 : 23|16@0+ (0.001,0) [1|1] "V"  BMS
 SG_ BMU20_Vol_39 : 39|16@0+ (0.001,0) [1|1] "V"  BMS
 SG_ BMU20_Vol_40 : 55|16@0+ (0.001,0) [1|1] "V"  BMS

BO_ 2282356756 BMU20_Vol_41: 8 BMU
 SG_ BMU20_Vol_41 : 7|16@0+ (0.001,0) [1|1] "V"  BMS
 SG_ BMU20_Vol_42 : 23|16@0+ (0.001,0) [1|1] "V"  BMS
 SG_ BMU20_Vol_43 : 39|16@0+ (0.001,0) [1|1] "V"  BMS
 SG_ BMU20_Vol_44 : 55|16@0+ (0.001,0) [1|1] "V"  BMS

BO_ 2282422292 BMU20_Vol_45: 8 BMU
 SG_ BMU20_Vol_45 : 7|16@0+ (0.001,0) [1|1] "V"  BMS
 SG_ BMU20_Vol_46 : 23|16@0+ (0.001,0) [1|1] "V"  BMS
 SG_ BMU20_Vol_47 : 39|16@0+ (0.001,0) [1|1] "V"  BMS
 SG_ BMU20_Vol_48 : 55|16@0+ (0.001,0) [1|1] "V"  BMS

BO_ 2282487828 BMU20_Vol_49: 8 BMU
 SG_ BMU20_Vol_49 : 7|16@0+ (0.001,0) [1|1] "V"  BMS
 SG_ BMU20_Vol_50 : 23|16@0+ (0.001,0) [1|1] "V"  BMS
 SG_ BMU20_Vol_51 : 39|16@0+ (0.001,0) [1|1] "V"  BMS
 SG_ BMU20_Vol_52 : 55|16@0+ (0.001,0) [1|1] "V"  BMS

BO_ 2282553364 BMU20_Vol_53: 8 BMU
 SG_ BMU20_Vol_53 : 7|16@0+ (0.001,0) [1|1] "V"  BMS
 SG_ BMU20_Vol_54 : 23|16@0+ (0.001,0) [1|1] "V"  BMS
 SG_ BMU20_Vol_55 : 39|16@0+ (0.001,0) [1|1] "V"  BMS
 SG_ BMU20_Vol_56 : 55|16@0+ (0.001,0) [1|1] "V"  BMS

BO_ 2282618900 BMU20_Vol_57: 8 BMU
 SG_ BMU20_Vol_57 : 7|16@0+ (0.001,0) [1|1] "V"  BMS
 SG_ BMU20_Vol_58 : 23|16@0+ (0.001,0) [1|1] "V"  BMS
 SG_ BMU20_Vol_59 : 39|16@0+ (0.001,0) [1|1] "V"  BMS
 SG_ BMU20_Vol_60 : 55|16@0+ (0.001,0) [1|1] "V"  BMS

BO_ 2282684436 BMU20_Vol_61: 8 BMU
 SG_ BMU20_Vol_61 : 7|16@0+ (0.001,0) [1|1] "V"  BMS
 SG_ BMU20_Vol_62 : 23|16@0+ (0.001,0) [1|1] "V"  BMS
 SG_ BMU20_Vol_63 : 39|16@0+ (0.001,0) [1|1] "V"  BMS
 SG_ BMU20_Vol_64 : 55|16@0+ (0.001,0) [1|1] "V"  BMS

BO_ 2282749972 BMU20_Vol_65: 8 BMU
 SG_ BMU20_Vol_65 : 7|16@0+ (0.001,0) [1|1] "V"  BMS
 SG_ BMU20_Vol_66 : 23|16@0+ (0.001,0) [1|1] "V"  BMS
 SG_ BMU20_Vol_67 : 39|16@0+ (0.001,0) [1|1] "V"  BMS
 SG_ BMU20_Vol_68 : 55|16@0+ (0.001,0) [1|1] "V"  BMS

BO_ 2282815508 BMU20_Vol_69: 8 BMU
 SG_ BMU20_Vol_69 : 7|16@0+ (0.001,0) [1|1] "V"  BMS
 SG_ BMU20_Vol_70 : 23|16@0+ (0.001,0) [1|1] "V"  BMS
 SG_ BMU20_Vol_71 : 39|16@0+ (0.001,0) [1|1] "V"  BMS
 SG_ BMU20_Vol_72 : 55|16@0+ (0.001,0) [1|1] "V"  BMS

BO_ 2282881044 BMU20_Vol_73: 8 BMU
 SG_ BMU20_Vol_73 : 7|16@0+ (0.001,0) [1|1] "V"  BMS
 SG_ BMU20_Vol_74 : 23|16@0+ (0.001,0) [1|1] "V"  BMS
 SG_ BMU20_Vol_75 : 39|16@0+ (0.001,0) [1|1] "V"  BMS
 SG_ BMU20_Vol_76 : 55|16@0+ (0.001,0) [1|1] "V"  BMS

BO_ 2282946580 BMU20_Vol_77: 8 BMU
 SG_ BMU20_Vol_77 : 7|16@0+ (0.001,0) [1|1] "V"  BMS
 SG_ BMU20_Vol_78 : 23|16@0+ (0.001,0) [1|1] "V"  BMS
 SG_ BMU20_Vol_79 : 39|16@0+ (0.001,0) [1|1] "V"  BMS
 SG_ BMU20_Vol_80 : 55|16@0+ (0.001,0) [1|1] "V"  BMS

BO_ 2283012116 BMU20_Vol_81: 8 BMU
 SG_ BMU20_Vol_81 : 7|16@0+ (0.001,0) [1|1] "V"  BMS
 SG_ BMU20_Vol_82 : 23|16@0+ (0.001,0) [1|1] "V"  BMS
 SG_ BMU20_Vol_83 : 39|16@0+ (0.001,0) [1|1] "V"  BMS
 SG_ BMU20_Vol_84 : 55|16@0+ (0.001,0) [1|1] "V"  BMS

BO_ 2283077652 BMU20_Vol_85: 8 BMU
 SG_ BMU20_Vol_85 : 7|16@0+ (0.001,0) [1|1] "V"  BMS
 SG_ BMU20_Vol_86 : 23|16@0+ (0.001,0) [1|1] "V"  BMS
 SG_ BMU20_Vol_87 : 39|16@0+ (0.001,0) [1|1] "V"  BMS
 SG_ BMU20_Vol_88 : 55|16@0+ (0.001,0) [1|1] "V"  BMS

BO_ 2283143188 BMU20_Vol_89: 8 BMU
 SG_ BMU20_Vol_89 : 7|16@0+ (0.001,0) [1|1] "V"  BMS
 SG_ BMU20_Vol_90 : 23|16@0+ (0.001,0) [1|1] "V"  BMS
 SG_ BMU20_Vol_91 : 39|16@0+ (0.001,0) [1|1] "V"  BMS
 SG_ BMU20_Vol_92 : 55|16@0+ (0.001,0) [1|1] "V"  BMS

BO_ 2283208724 BMU20_Vol_93: 8 BMU
 SG_ BMU20_Vol_93 : 7|16@0+ (0.001,0) [1|1] "V"  BMS
 SG_ BMU20_Vol_94 : 23|16@0+ (0.001,0) [1|1] "V"  BMS
 SG_ BMU20_Vol_95 : 39|16@0+ (0.001,0) [1|1] "V"  BMS
 SG_ BMU20_Vol_96 : 55|16@0+ (0.001,0) [1|1] "V"  BMS

BO_ 2281701397 BMU21_Vol_1: 8 BMU
 SG_ BMU21_Vol_1 : 7|16@0+ (0.001,0) [1|1] "V"  BMS
 SG_ BMU21_Vol_2 : 23|16@0+ (0.001,0) [1|1] "V"  BMS
 SG_ BMU21_Vol_3 : 39|16@0+ (0.001,0) [1|1] "V"  BMS
 SG_ BMU21_Vol_4 : 55|16@0+ (0.001,0) [1|1] "V"  BMS

BO_ 2281766933 BMU21_Vol_5: 8 BMU
 SG_ BMU21_Vol_5 : 7|16@0+ (0.001,0) [1|1] "V"  BMS
 SG_ BMU21_Vol_6 : 23|16@0+ (0.001,0) [1|1] "V"  BMS
 SG_ BMU21_Vol_7 : 39|16@0+ (0.001,0) [1|1] "V"  BMS
 SG_ BMU21_Vol_8 : 55|16@0+ (0.001,0) [1|1] "V"  BMS

BO_ 2281832469 BMU21_Vol_9: 8 BMU
 SG_ BMU21_Vol_9 : 7|16@0+ (0.001,0) [1|1] "V"  BMS
 SG_ BMU21_Vol_10 : 23|16@0+ (0.001,0) [1|1] "V"  BMS
 SG_ BMU21_Vol_11 : 39|16@0+ (0.001,0) [1|1] "V"  BMS
 SG_ BMU21_Vol_12 : 55|16@0+ (0.001,0) [1|1] "V"  BMS

BO_ 2281898005 BMU21_Vol_13: 8 BMU
 SG_ BMU21_Vol_13 : 7|16@0+ (0.001,0) [1|1] "V"  BMS
 SG_ BMU21_Vol_14 : 23|16@0+ (0.001,0) [1|1] "V"  BMS
 SG_ BMU21_Vol_15 : 39|16@0+ (0.001,0) [1|1] "V"  BMS
 SG_ BMU21_Vol_16 : 55|16@0+ (0.001,0) [1|1] "V"  BMS

BO_ 2281963541 BMU21_Vol_17: 8 BMU
 SG_ BMU21_Vol_17 : 7|16@0+ (0.001,0) [1|1] "V"  BMS
 SG_ BMU21_Vol_18 : 23|16@0+ (0.001,0) [1|1] "V"  BMS
 SG_ BMU21_Vol_19 : 39|16@0+ (0.001,0) [1|1] "V"  BMS
 SG_ BMU21_Vol_20 : 55|16@0+ (0.001,0) [1|1] "V"  BMS

BO_ 2282029077 BMU21_Vol_21: 8 BMU
 SG_ BMU21_Vol_21 : 7|16@0+ (0.001,0) [1|1] "V"  BMS
 SG_ BMU21_Vol_22 : 23|16@0+ (0.001,0) [1|1] "V"  BMS
 SG_ BMU21_Vol_23 : 39|16@0+ (0.001,0) [1|1] "V"  BMS
 SG_ BMU21_Vol_24 : 55|16@0+ (0.001,0) [1|1] "V"  BMS

BO_ 2282094613 BMU21_Vol_25: 8 BMU
 SG_ BMU21_Vol_25 : 7|16@0+ (0.001,0) [1|1] "V"  BMS
 SG_ BMU21_Vol_26 : 23|16@0+ (0.001,0) [1|1] "V"  BMS
 SG_ BMU21_Vol_27 : 39|16@0+ (0.001,0) [1|1] "V"  BMS
 SG_ BMU21_Vol_28 : 55|16@0+ (0.001,0) [1|1] "V"  BMS

BO_ 2282160149 BMU21_Vol_29: 8 BMU
 SG_ BMU21_Vol_29 : 7|16@0+ (0.001,0) [1|1] "V"  BMS
 SG_ BMU21_Vol_30 : 23|16@0+ (0.001,0) [1|1] "V"  BMS
 SG_ BMU21_Vol_31 : 39|16@0+ (0.001,0) [1|1] "V"  BMS
 SG_ BMU21_Vol_32 : 55|16@0+ (0.001,0) [1|1] "V"  BMS

BO_ 2282225685 BMU21_Vol_33: 8 BMU
 SG_ BMU21_Vol_33 : 7|16@0+ (0.001,0) [1|1] "V"  BMS
 SG_ BMU21_Vol_34 : 23|16@0+ (0.001,0) [1|1] "V"  BMS
 SG_ BMU21_Vol_35 : 39|16@0+ (0.001,0) [1|1] "V"  BMS
 SG_ BMU21_Vol_36 : 55|16@0+ (0.001,0) [1|1] "V"  BMS

BO_ 2282291221 BMU21_Vol_37: 8 BMU
 SG_ BMU21_Vol_37 : 7|16@0+ (0.001,0) [1|1] "V"  BMS
 SG_ BMU21_Vol_38 : 23|16@0+ (0.001,0) [1|1] "V"  BMS
 SG_ BMU21_Vol_39 : 39|16@0+ (0.001,0) [1|1] "V"  BMS
 SG_ BMU21_Vol_40 : 55|16@0+ (0.001,0) [1|1] "V"  BMS

BO_ 2282356757 BMU21_Vol_41: 8 BMU
 SG_ BMU21_Vol_41 : 7|16@0+ (0.001,0) [1|1] "V"  BMS
 SG_ BMU21_Vol_42 : 23|16@0+ (0.001,0) [1|1] "V"  BMS
 SG_ BMU21_Vol_43 : 39|16@0+ (0.001,0) [1|1] "V"  BMS
 SG_ BMU21_Vol_44 : 55|16@0+ (0.001,0) [1|1] "V"  BMS

BO_ 2282422293 BMU21_Vol_45: 8 BMU
 SG_ BMU21_Vol_45 : 7|16@0+ (0.001,0) [1|1] "V"  BMS
 SG_ BMU21_Vol_46 : 23|16@0+ (0.001,0) [1|1] "V"  BMS
 SG_ BMU21_Vol_47 : 39|16@0+ (0.001,0) [1|1] "V"  BMS
 SG_ BMU21_Vol_48 : 55|16@0+ (0.001,0) [1|1] "V"  BMS

BO_ 2282487829 BMU21_Vol_49: 8 BMU
 SG_ BMU21_Vol_49 : 7|16@0+ (0.001,0) [1|1] "V"  BMS
 SG_ BMU21_Vol_50 : 23|16@0+ (0.001,0) [1|1] "V"  BMS
 SG_ BMU21_Vol_51 : 39|16@0+ (0.001,0) [1|1] "V"  BMS
 SG_ BMU21_Vol_52 : 55|16@0+ (0.001,0) [1|1] "V"  BMS

BO_ 2282553365 BMU21_Vol_53: 8 BMU
 SG_ BMU21_Vol_53 : 7|16@0+ (0.001,0) [1|1] "V"  BMS
 SG_ BMU21_Vol_54 : 23|16@0+ (0.001,0) [1|1] "V"  BMS
 SG_ BMU21_Vol_55 : 39|16@0+ (0.001,0) [1|1] "V"  BMS
 SG_ BMU21_Vol_56 : 55|16@0+ (0.001,0) [1|1] "V"  BMS

BO_ 2282618901 BMU21_Vol_57: 8 BMU
 SG_ BMU21_Vol_57 : 7|16@0+ (0.001,0) [1|1] "V"  BMS
 SG_ BMU21_Vol_58 : 23|16@0+ (0.001,0) [1|1] "V"  BMS
 SG_ BMU21_Vol_59 : 39|16@0+ (0.001,0) [1|1] "V"  BMS
 SG_ BMU21_Vol_60 : 55|16@0+ (0.001,0) [1|1] "V"  BMS

BO_ 2282684437 BMU21_Vol_61: 8 BMU
 SG_ BMU21_Vol_61 : 7|16@0+ (0.001,0) [1|1] "V"  BMS
 SG_ BMU21_Vol_62 : 23|16@0+ (0.001,0) [1|1] "V"  BMS
 SG_ BMU21_Vol_63 : 39|16@0+ (0.001,0) [1|1] "V"  BMS
 SG_ BMU21_Vol_64 : 55|16@0+ (0.001,0) [1|1] "V"  BMS

BO_ 2282749973 BMU21_Vol_65: 8 BMU
 SG_ BMU21_Vol_65 : 7|16@0+ (0.001,0) [1|1] "V"  BMS
 SG_ BMU21_Vol_66 : 23|16@0+ (0.001,0) [1|1] "V"  BMS
 SG_ BMU21_Vol_67 : 39|16@0+ (0.001,0) [1|1] "V"  BMS
 SG_ BMU21_Vol_68 : 55|16@0+ (0.001,0) [1|1] "V"  BMS

BO_ 2282815509 BMU21_Vol_69: 8 BMU
 SG_ BMU21_Vol_69 : 7|16@0+ (0.001,0) [1|1] "V"  BMS
 SG_ BMU21_Vol_70 : 23|16@0+ (0.001,0) [1|1] "V"  BMS
 SG_ BMU21_Vol_71 : 39|16@0+ (0.001,0) [1|1] "V"  BMS
 SG_ BMU21_Vol_72 : 55|16@0+ (0.001,0) [1|1] "V"  BMS

BO_ 2282881045 BMU21_Vol_73: 8 BMU
 SG_ BMU21_Vol_73 : 7|16@0+ (0.001,0) [1|1] "V"  BMS
 SG_ BMU21_Vol_74 : 23|16@0+ (0.001,0) [1|1] "V"  BMS
 SG_ BMU21_Vol_75 : 39|16@0+ (0.001,0) [1|1] "V"  BMS
 SG_ BMU21_Vol_76 : 55|16@0+ (0.001,0) [1|1] "V"  BMS

BO_ 2282946581 BMU21_Vol_77: 8 BMU
 SG_ BMU21_Vol_77 : 7|16@0+ (0.001,0) [1|1] "V"  BMS
 SG_ BMU21_Vol_78 : 23|16@0+ (0.001,0) [1|1] "V"  BMS
 SG_ BMU21_Vol_79 : 39|16@0+ (0.001,0) [1|1] "V"  BMS
 SG_ BMU21_Vol_80 : 55|16@0+ (0.001,0) [1|1] "V"  BMS

BO_ 2283012117 BMU21_Vol_81: 8 BMU
 SG_ BMU21_Vol_81 : 7|16@0+ (0.001,0) [1|1] "V"  BMS
 SG_ BMU21_Vol_82 : 23|16@0+ (0.001,0) [1|1] "V"  BMS
 SG_ BMU21_Vol_83 : 39|16@0+ (0.001,0) [1|1] "V"  BMS
 SG_ BMU21_Vol_84 : 55|16@0+ (0.001,0) [1|1] "V"  BMS

BO_ 2283077653 BMU21_Vol_85: 8 BMU
 SG_ BMU21_Vol_85 : 7|16@0+ (0.001,0) [1|1] "V"  BMS
 SG_ BMU21_Vol_86 : 23|16@0+ (0.001,0) [1|1] "V"  BMS
 SG_ BMU21_Vol_87 : 39|16@0+ (0.001,0) [1|1] "V"  BMS
 SG_ BMU21_Vol_88 : 55|16@0+ (0.001,0) [1|1] "V"  BMS

BO_ 2283143189 BMU21_Vol_89: 8 BMU
 SG_ BMU21_Vol_89 : 7|16@0+ (0.001,0) [1|1] "V"  BMS
 SG_ BMU21_Vol_90 : 23|16@0+ (0.001,0) [1|1] "V"  BMS
 SG_ BMU21_Vol_91 : 39|16@0+ (0.001,0) [1|1] "V"  BMS
 SG_ BMU21_Vol_92 : 55|16@0+ (0.001,0) [1|1] "V"  BMS

BO_ 2283208725 BMU21_Vol_93: 8 BMU
 SG_ BMU21_Vol_93 : 7|16@0+ (0.001,0) [1|1] "V"  BMS
 SG_ BMU21_Vol_94 : 23|16@0+ (0.001,0) [1|1] "V"  BMS
 SG_ BMU21_Vol_95 : 39|16@0+ (0.001,0) [1|1] "V"  BMS
 SG_ BMU21_Vol_96 : 55|16@0+ (0.001,0) [1|1] "V"  BMS

BO_ 2281701398 BMU22_Vol_1: 8 BMU
 SG_ BMU22_Vol_1 : 7|16@0+ (0.001,0) [1|1] "V"  BMS
 SG_ BMU22_Vol_2 : 23|16@0+ (0.001,0) [1|1] "V"  BMS
 SG_ BMU22_Vol_3 : 39|16@0+ (0.001,0) [1|1] "V"  BMS
 SG_ BMU22_Vol_4 : 55|16@0+ (0.001,0) [1|1] "V"  BMS

BO_ 2281766934 BMU22_Vol_5: 8 BMU
 SG_ BMU22_Vol_5 : 7|16@0+ (0.001,0) [1|1] "V"  BMS
 SG_ BMU22_Vol_6 : 23|16@0+ (0.001,0) [1|1] "V"  BMS
 SG_ BMU22_Vol_7 : 39|16@0+ (0.001,0) [1|1] "V"  BMS
 SG_ BMU22_Vol_8 : 55|16@0+ (0.001,0) [1|1] "V"  BMS

BO_ 2281832470 BMU22_Vol_9: 8 BMU
 SG_ BMU22_Vol_9 : 7|16@0+ (0.001,0) [1|1] "V"  BMS
 SG_ BMU22_Vol_10 : 23|16@0+ (0.001,0) [1|1] "V"  BMS
 SG_ BMU22_Vol_11 : 39|16@0+ (0.001,0) [1|1] "V"  BMS
 SG_ BMU22_Vol_12 : 55|16@0+ (0.001,0) [1|1] "V"  BMS

BO_ 2281898006 BMU22_Vol_13: 8 BMU
 SG_ BMU22_Vol_13 : 7|16@0+ (0.001,0) [1|1] "V"  BMS
 SG_ BMU22_Vol_14 : 23|16@0+ (0.001,0) [1|1] "V"  BMS
 SG_ BMU22_Vol_15 : 39|16@0+ (0.001,0) [1|1] "V"  BMS
 SG_ BMU22_Vol_16 : 55|16@0+ (0.001,0) [1|1] "V"  BMS

BO_ 2281963542 BMU22_Vol_17: 8 BMU
 SG_ BMU22_Vol_17 : 7|16@0+ (0.001,0) [1|1] "V"  BMS
 SG_ BMU22_Vol_18 : 23|16@0+ (0.001,0) [1|1] "V"  BMS
 SG_ BMU22_Vol_19 : 39|16@0+ (0.001,0) [1|1] "V"  BMS
 SG_ BMU22_Vol_20 : 55|16@0+ (0.001,0) [1|1] "V"  BMS

BO_ 2282029078 BMU22_Vol_21: 8 BMU
 SG_ BMU22_Vol_21 : 7|16@0+ (0.001,0) [1|1] "V"  BMS
 SG_ BMU22_Vol_22 : 23|16@0+ (0.001,0) [1|1] "V"  BMS
 SG_ BMU22_Vol_23 : 39|16@0+ (0.001,0) [1|1] "V"  BMS
 SG_ BMU22_Vol_24 : 55|16@0+ (0.001,0) [1|1] "V"  BMS

BO_ 2282094614 BMU22_Vol_25: 8 BMU
 SG_ BMU22_Vol_25 : 7|16@0+ (0.001,0) [1|1] "V"  BMS
 SG_ BMU22_Vol_26 : 23|16@0+ (0.001,0) [1|1] "V"  BMS
 SG_ BMU22_Vol_27 : 39|16@0+ (0.001,0) [1|1] "V"  BMS
 SG_ BMU22_Vol_28 : 55|16@0+ (0.001,0) [1|1] "V"  BMS

BO_ 2282160150 BMU22_Vol_29: 8 BMU
 SG_ BMU22_Vol_29 : 7|16@0+ (0.001,0) [1|1] "V"  BMS
 SG_ BMU22_Vol_30 : 23|16@0+ (0.001,0) [1|1] "V"  BMS
 SG_ BMU22_Vol_31 : 39|16@0+ (0.001,0) [1|1] "V"  BMS
 SG_ BMU22_Vol_32 : 55|16@0+ (0.001,0) [1|1] "V"  BMS

BO_ 2282225686 BMU22_Vol_33: 8 BMU
 SG_ BMU22_Vol_33 : 7|16@0+ (0.001,0) [1|1] "V"  BMS
 SG_ BMU22_Vol_34 : 23|16@0+ (0.001,0) [1|1] "V"  BMS
 SG_ BMU22_Vol_35 : 39|16@0+ (0.001,0) [1|1] "V"  BMS
 SG_ BMU22_Vol_36 : 55|16@0+ (0.001,0) [1|1] "V"  BMS

BO_ 2282291222 BMU22_Vol_37: 8 BMU
 SG_ BMU22_Vol_37 : 7|16@0+ (0.001,0) [1|1] "V"  BMS
 SG_ BMU22_Vol_38 : 23|16@0+ (0.001,0) [1|1] "V"  BMS
 SG_ BMU22_Vol_39 : 39|16@0+ (0.001,0) [1|1] "V"  BMS
 SG_ BMU22_Vol_40 : 55|16@0+ (0.001,0) [1|1] "V"  BMS

BO_ 2282356758 BMU22_Vol_41: 8 BMU
 SG_ BMU22_Vol_41 : 7|16@0+ (0.001,0) [1|1] "V"  BMS
 SG_ BMU22_Vol_42 : 23|16@0+ (0.001,0) [1|1] "V"  BMS
 SG_ BMU22_Vol_43 : 39|16@0+ (0.001,0) [1|1] "V"  BMS
 SG_ BMU22_Vol_44 : 55|16@0+ (0.001,0) [1|1] "V"  BMS

BO_ 2282422294 BMU22_Vol_45: 8 BMU
 SG_ BMU22_Vol_45 : 7|16@0+ (0.001,0) [1|1] "V"  BMS
 SG_ BMU22_Vol_46 : 23|16@0+ (0.001,0) [1|1] "V"  BMS
 SG_ BMU22_Vol_47 : 39|16@0+ (0.001,0) [1|1] "V"  BMS
 SG_ BMU22_Vol_48 : 55|16@0+ (0.001,0) [1|1] "V"  BMS

BO_ 2282487830 BMU22_Vol_49: 8 BMU
 SG_ BMU22_Vol_49 : 7|16@0+ (0.001,0) [1|1] "V"  BMS
 SG_ BMU22_Vol_50 : 23|16@0+ (0.001,0) [1|1] "V"  BMS
 SG_ BMU22_Vol_51 : 39|16@0+ (0.001,0) [1|1] "V"  BMS
 SG_ BMU22_Vol_52 : 55|16@0+ (0.001,0) [1|1] "V"  BMS

BO_ 2282553366 BMU22_Vol_53: 8 BMU
 SG_ BMU22_Vol_53 : 7|16@0+ (0.001,0) [1|1] "V"  BMS
 SG_ BMU22_Vol_54 : 23|16@0+ (0.001,0) [1|1] "V"  BMS
 SG_ BMU22_Vol_55 : 39|16@0+ (0.001,0) [1|1] "V"  BMS
 SG_ BMU22_Vol_56 : 55|16@0+ (0.001,0) [1|1] "V"  BMS
